VERSION ""

NS_ :

BS_:

BU_: mLEDR mLEDL TLR TLL RLR RLL HLR HLL DASCU CGW BCM

BO_ 3221225472 VECTOR__INDEPENDENT_SIG_MSG: 0 Vector__XXX
 SG_ MAS_SteeringAngle_Req : 0|16@1- (0.1,0) [-780|779.9] "Â°" Vector__XXX
 SG_ MAS_DistanceToGo_Val : 0|10@1+ (1,0) [0|1023] "cm" Vector__XXX
 SG_ MAS_TmissionMode_Req : 0|3@1+ (1,0) [0|4] "" Vector__XXX
 SG_ VCU_DriveInfo_RC : 0|4@1+ (1,0) [0|15] "" Vector__XXX

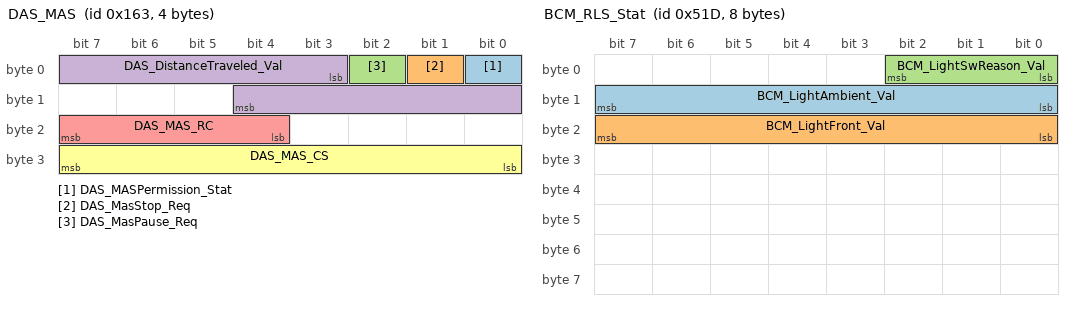
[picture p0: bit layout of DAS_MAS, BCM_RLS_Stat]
BO_ 355 DAS_MAS: 4 DASCU
 SG_ DAS_MASPermission_Stat : 0|1@1+ (1,0) [0|1] ""  CGW
 SG_ DAS_MasStop_Req : 1|1@1+ (1,0) [0|1] ""  CGW
 SG_ DAS_MasPause_Req : 2|1@1+ (1,0) [0|1] ""  CGW
 SG_ DAS_DistanceTraveled_Val : 3|10@1+ (1,0) [0|1023] "cm"  CGW
 SG_ DAS_MAS_RC : 20|4@1+ (1,0) [0|15] ""  CGW
 SG_ DAS_MAS_CS : 24|8@1+ (1,0) [0|255] ""  CGW

BO_ 640 BCM_VEH_STATE: 8 BCM
 SG_ BCM_T15_Stat : 0|1@1+ (1,0) [0|1] ""  HLR,mLEDR,TLR,RLL,RLR,DASCU,TLL,mLEDL,HLL
 SG_ BCM_CCTerm_Stat : 13|1@1+ (1,0) [0|1] "" Vector__XXX
 SG_ BCM_SwIndIntens_Stat : 52|1@1+ (1,0) [0|1] "" Vector__XXX
 SG_ BCM_T30d_Stat : 1|1@1+ (1,0) [0|1] ""  DASCU
 SG_ BCM_IndFadingTime_Req : 26|5@1+ (0.1,0) [0|3.1] "s" Vector__XXX
 SG_ HUD_IntensityRequest : 16|8@1+ (1,0) [0|255] "" Vector__XXX
 SG_ StealthModeEn : 6|1@1+ (1,0) [0|1] "" Vector__XXX
 SG_ BCM_T30i_DisableWarning : 14|1@1+ (1,0) [0|1] "" Vector__XXX
 SG_ BCM_T30i_Stat : 2|1@1+ (1,0) [0|1] ""  DASCU
 SG_ BCM_Light_Stat : 25|1@1+ (1,0) [0|1] "" Vector__XXX
 SG_ BCM_LightBCM_Stat : 15|1@1+ (1,0) [0|1] "" Vector__XXX
 SG_ BCM_CCTermDisableWarning : 31|1@1+ (1,0) [0|1] "" Vector__XXX
 SG_ BCM_SwBackIntens_Val : 40|8@1+ (0.394,0) [0|100.47] "%" Vector__XXX
 SG_ BCM_LVBatteryVoltage : 56|8@1+ (0.075,0) [0|19.125] "V" Vector__XXX
 SG_ BCM_PreheatFunction_Stat : 32|2@1+ (1,0) [0|3] "" Vector__XXX
 SG_ BCM_ADASTerm_Stat : 12|1@1+ (1,0) [0|1] ""  DASCU
 SG_ BCM_VehicleBody_Stat : 8|4@1+ (1,0) [0|6] ""  DASCU
 SG_ BCM_T30d_DisableWarning : 24|1@1+ (1,0) [0|1] ""  DASCU
 SG_ BCM_VehicleType_Stat : 7|1@1+ (1,0) [0|1] ""  DASCU
 SG_ BCM_T15h_Stat : 3|1@1+ (1,0) [0|1] "" Vector__XXX
 SG_ BCM_VehicleMode_Stat : 48|4@1+ (1,0) [0|6] ""  DASCU
 SG_ BCM_Vehicle_DrvMode : 53|3@1+ (1,0) [0|7] "" Vector__XXX
 SG_ BCM_VehiclePowertrain_Stat : 34|2@1+ (1,0) [0|3] "" Vector__XXX
 SG_ BCM_SPV_Feature_Stat : 5|1@1+ (1,0) [0|1] "" Vector__XXX

BO_ 1535 DAS_Configure: 5 DASCU
 SG_ DAS_CaebConf_Stat : 21|1@1+ (1,0) [0|1] ""  CGW
 SG_ DAS_CcConf_Stat : 0|1@1+ (1,0) [0|1] ""  CGW
 SG_ DAS_AccConf_Stat : 1|1@1+ (1,0) [0|1] ""  CGW
 SG_ DAS_LimConf_Stat : 2|1@1+ (1,0) [0|1] ""  CGW
 SG_ DAS_AslaConf_Stat : 3|1@1+ (1,0) [0|1] ""  CGW
 SG_ DAS_LkaConf_Stat : 4|1@1+ (1,0) [0|1] ""  CGW
 SG_ DAS_FcwConf_Stat : 5|1@1+ (1,0) [0|1] ""  CGW
 SG_ DAS_AebConf_Stat : 6|1@1+ (1,0) [0|1] ""  CGW
 SG_ DAS_LccConf_Stat : 7|1@1+ (1,0) [0|1] ""  CGW
 SG_ DAS_AlccConf_Stat : 8|1@1+ (1,0) [0|1] ""  CGW
 SG_ DAS_DowConf_Stat : 9|1@1+ (1,0) [0|1] ""  CGW
 SG_ DAS_LdwConf_Stat : 10|1@1+ (1,0) [0|1] ""  CGW
 SG_ DAS_LdpConf_Stat : 11|1@1+ (1,0) [0|1] ""  CGW
 SG_ DAS_TsrConf_Stat : 12|1@1+ (1,0) [0|1] ""  CGW
 SG_ DAS_AaConf_Stat : 13|1@1+ (1,0) [0|1] ""  CGW
 SG_ DAS_AfsConf_Stat : 14|1@1+ (1,0) [0|1] ""  CGW
 SG_ DAS_RdaConf_Stat : 15|1@1+ (1,0) [0|1] ""  CGW
 SG_ DAS_RctcConf_Stat : 16|1@1+ (1,0) [0|1] ""  CGW
 SG_ DAS_RcwConf_Stat : 17|1@1+ (1,0) [0|1] ""  CGW
 SG_ DAS_RecConf_Stat : 18|1@1+ (1,0) [0|1] ""  CGW
 SG_ DAS_NvConf_Stat : 19|1@1+ (1,0) [0|1] ""  CGW
 SG_ DAS_VisualConf_Stat : 20|1@1+ (1,0) [0|1] ""  CGW
 SG_ DAS_Conf_RC : 28|4@1+ (1,0) [0|15] ""  CGW
 SG_ DAS_Conf_CS : 32|8@1+ (1,0) [0|255] ""  CGW
 SG_ DAS_MliaConf_Stat : 22|1@1+ (1,0) [0|1] ""  CGW

BO_ 1309 BCM_RLS_Stat: 8 BCM
 SG_ BCM_LightAmbient_Val : 8|8@1+ (100,0) [0|25500] "lx"  DASCU
 SG_ BCM_LightFront_Val : 16|8@1+ (50,0) [0|12750] "lx"  DASCU
 SG_ BCM_LightSwReason_Val : 0|3@1+ (1,0) [0|6] ""  DASCU

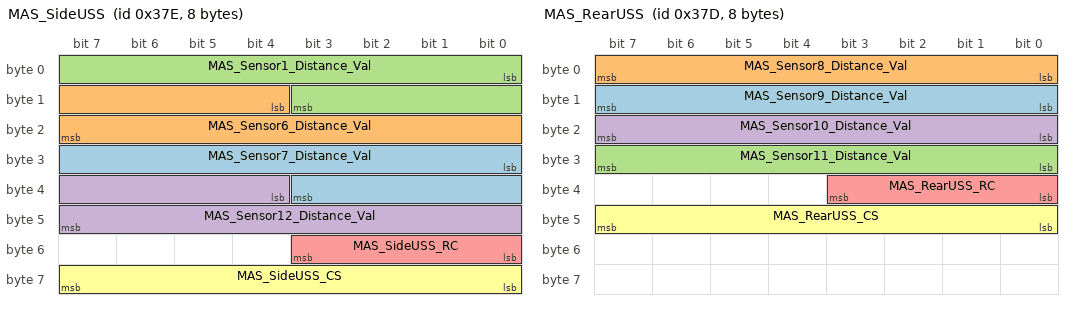
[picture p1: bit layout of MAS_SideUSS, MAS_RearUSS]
BO_ 894 MAS_SideUSS: 8 CGW
 SG_ MAS_Sensor7_Distance_Val : 24|12@1+ (2.5,0) [0|635] "cm"  DASCU
 SG_ MAS_Sensor6_Distance_Val : 12|12@1+ (2.5,0) [0|635] "cm"  DASCU
 SG_ MAS_Sensor1_Distance_Val : 0|12@1+ (2.5,0) [0|635] "cm"  DASCU
 SG_ MAS_Sensor12_Distance_Val : 36|12@1+ (2.5,0) [0|635] "cm"  DASCU
 SG_ MAS_SideUSS_RC : 48|4@1+ (1,0) [0|15] ""  DASCU
 SG_ MAS_SideUSS_CS : 56|8@1+ (1,0) [0|255] ""  DASCU

BO_ 893 MAS_RearUSS: 8 CGW
 SG_ MAS_Sensor9_Distance_Val : 8|8@1+ (1,0) [0|255] "cm"  DASCU
 SG_ MAS_Sensor8_Distance_Val : 0|8@1+ (1,0) [0|255] "cm"  DASCU
 SG_ MAS_Sensor11_Distance_Val : 24|8@1+ (1,0) [0|255] "cm"  DASCU
 SG_ MAS_Sensor10_Distance_Val : 16|8@1+ (1,0) [0|255] "cm"  DASCU
 SG_ MAS_RearUSS_RC : 32|4@1+ (1,0) [0|15] ""  DASCU
 SG_ MAS_RearUSS_CS : 40|8@1+ (1,0) [0|255] ""  DASCU

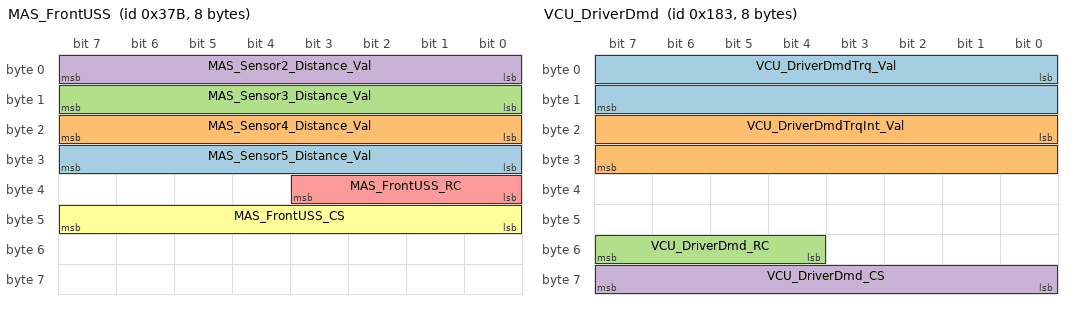
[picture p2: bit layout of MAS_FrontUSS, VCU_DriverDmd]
BO_ 891 MAS_FrontUSS: 8 CGW
 SG_ MAS_Sensor5_Distance_Val : 24|8@1+ (1,0) [0|255] "cm"  DASCU
 SG_ MAS_Sensor4_Distance_Val : 16|8@1+ (1,0) [0|255] "cm"  DASCU
 SG_ MAS_Sensor3_Distance_Val : 8|8@1+ (1,0) [0|255] "cm"  DASCU
 SG_ MAS_Sensor2_Distance_Val : 0|8@1+ (1,0) [0|255] "cm"  DASCU
 SG_ MAS_FrontUSS_RC : 32|4@1+ (1,0) [0|15] ""  DASCU
 SG_ MAS_FrontUSS_CS : 40|8@1+ (1,0) [0|255] ""  DASCU

BO_ 567 SWM_ContrlsState_Old: 8 CGW
 SG_ SWM_ContrlsState_Old_RC : 48|4@1+ (1,0) [0|15] ""  DASCU
 SG_ SWM_DC_WheelPosition_Stat : 10|6@1+ (1,0) [0|63] "" Vector__XXX
 SG_ SWM_ContrlsState_Old_CS : 56|8@1+ (1,0) [0|255] ""  DASCU
 SG_ SWM_MMSPrevBtn_Stat : 18|2@1+ (1,0) [0|3] "" Vector__XXX
 SG_ SWM_DC_WheelButton_Stat : 8|2@1+ (1,0) [0|3] "" Vector__XXX
 SG_ SWM_TELBtn_Stat : 20|2@1+ (1,0) [0|3] "" Vector__XXX
 SG_ SWM_ECULED_Stat : 36|2@1+ (1,0) [0|3] "" Vector__XXX
 SG_ SWM_ACC_SpeedIncrease_Stat : 6|2@1+ (1,0) [0|3] ""  DASCU
 SG_ SWM_ACCDistanceChange_Stat : 2|2@1+ (1,0) [0|3] ""  DASCU
 SG_ SWM_UpshiftPaddle_Stat : 32|2@1+ (1,0) [0|3] "" Vector__XXX
 SG_ SWM_ACCactivate_Stat : 0|2@1+ (1,0) [0|3] ""  DASCU
 SG_ SWM_MMSNextBtn_Stat : 16|2@1+ (1,0) [0|3] "" Vector__XXX
 SG_ SWM_ACCSpeedDecrease_Stat : 4|2@1+ (1,0) [0|3] ""  DASCU
 SG_ SWM_DownshiftPaddle_Stat : 34|2@1+ (1,0) [0|3] "" Vector__XXX
 SG_ SWM_VOLWheelBtn_Stat : 24|2@1+ (1,0) [0|3] "" Vector__XXX
 SG_ SWM_VCBtn_Stat : 22|2@1+ (1,0) [0|3] "" Vector__XXX
 SG_ SWM_VOLWheelPosition_Stat : 26|6@1+ (1,0) [0|63] "" Vector__XXX

BO_ 1902 Diag_To_RLR: 8 CGW
 SG_ Diag_To_RLR : 7|64@0+ (1,0) [0|1.84467440737096E+019] ""  RLR

BO_ 1901 Diag_To_RLL: 8 CGW
 SG_ Diag_To_RLL : 7|64@0+ (1,0) [0|1.84467440737096E+019] ""  RLL

BO_ 1894 Diag_To_TLR: 8 CGW
 SG_ Diag_To_TLR : 7|64@0+ (1,0) [0|1.84467440737096E+019] ""  TLR

BO_ 1893 Diag_To_TLL: 8 CGW
 SG_ Diag_To_TLL : 7|64@0+ (1,0) [0|1.84467440737096E+019] ""  TLL

BO_ 1900 Diag_To_mLEDR: 8 CGW
 SG_ Diag_To_mLEDR : 7|64@0+ (1,0) [0|1.84467440737096E+019] ""  mLEDR

BO_ 1915 Diag_To_HLR: 8 CGW
 SG_ Diag_To_HLR : 7|64@0+ (1,0) [0|1.84467440737096E+019] ""  HLR

BO_ 1898 Diag_To_mLEDL: 8 CGW
 SG_ Diag_To_mLEDL : 7|64@0+ (1,0) [0|1.84467440737096E+019] ""  mLEDL

BO_ 1897 Diag_To_HLL: 8 CGW
 SG_ Diag_To_HLL : 7|64@0+ (1,0) [0|1.84467440737096E+019] ""  HLL

BO_ 1910 Diag_From_TLR: 8 TLR
 SG_ Diag_From_TLR : 7|64@0+ (1,0) [0|1.84467440737096E+019] ""  CGW

BO_ 1909 Diag_From_TLL: 8 TLL
 SG_ Diag_From_TLL : 7|64@0+ (1,0) [0|1.84467440737096E+019] ""  CGW

BO_ 1918 Diag_From_RLR: 8 RLR
 SG_ Diag_From_RLR : 7|64@0+ (1,0) [0|1.84467440737096E+019] ""  CGW

BO_ 1917 Diag_From_RLL: 8 RLL
 SG_ Diag_From_RLL : 7|64@0+ (1,0) [0|1.84467440737096E+019] ""  CGW

BO_ 1916 Diag_From_mLEDR: 8 mLEDR
 SG_ Diag_From_mLEDR : 7|64@0+ (1,0) [0|1.84467440737096E+019] ""  CGW

BO_ 1899 Diag_From_HLR: 8 HLR
 SG_ Diag_From_HLR : 7|64@0+ (1,0) [0|1.84467440737096E+019] ""  CGW

BO_ 1914 Diag_From_mLEDL: 8 mLEDL
 SG_ Diag_From_mLEDL : 7|64@0+ (1,0) [0|1.84467440737096E+019] ""  CGW

BO_ 1913 Diag_From_HLL: 8 HLL
 SG_ Diag_From_HLL : 7|64@0+ (1,0) [0|1.84467440737096E+019] ""  CGW

BO_ 387 VCU_DriverDmd: 8 CGW
 SG_ VCU_DriverDmdTrq_Val : 0|16@1+ (0.25,-1533) [-1533|1537.5] "Nm"  DASCU
 SG_ VCU_DriverDmdTrqInt_Val : 16|16@1+ (0.25,-1533) [-1533|1537.5] "Nm"  DASCU
 SG_ VCU_DriverDmd_RC : 52|4@1+ (1,0) [0|15] ""  DASCU
 SG_ VCU_DriverDmd_CS : 56|8@1+ (1,0) [0|255] ""  DASCU

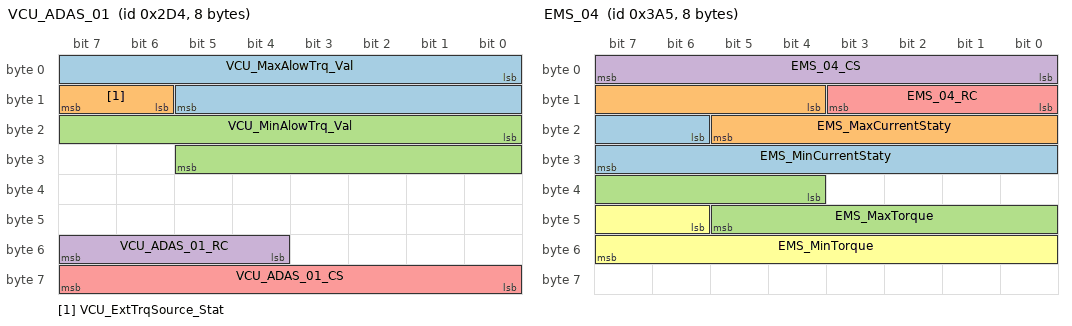
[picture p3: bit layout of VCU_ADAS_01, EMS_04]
BO_ 724 VCU_ADAS_01: 8 CGW
 SG_ VCU_MaxAlowTrq_Val : 0|14@1+ (0.25,-1533) [-1533|1537.5] "Nm"  DASCU
 SG_ VCU_ExtTrqSource_Stat : 14|2@1+ (1,0) [0|3] ""  DASCU
 SG_ VCU_MinAlowTrq_Val : 16|14@1+ (0.25,-1533) [-1533|1537.5] "Nm"  DASCU
 SG_ VCU_ADAS_01_RC : 52|4@1+ (1,0) [0|15] ""  DASCU
 SG_ VCU_ADAS_01_CS : 56|8@1+ (1,0) [0|255] ""  DASCU

BO_ 933 EMS_04: 8 CGW
 SG_ EMS_MinCurrentStaty : 22|10@1+ (1,-511) [-511|511] "A"  DASCU
 SG_ EMS_MaxCurrentStaty : 12|10@1+ (1,-511) [-511|511] "A"  DASCU
 SG_ EMS_MaxTorque : 36|10@1+ (1,-511) [-511|511] "Nm"  DASCU
 SG_ EMS_04_CS : 0|8@1+ (1,0) [0|255] ""  DASCU
 SG_ EMS_04_RC : 8|4@1+ (1,0) [0|15] ""  DASCU
 SG_ EMS_MinTorque : 46|10@1+ (1,-511) [-511|511] "Nm"  DASCU

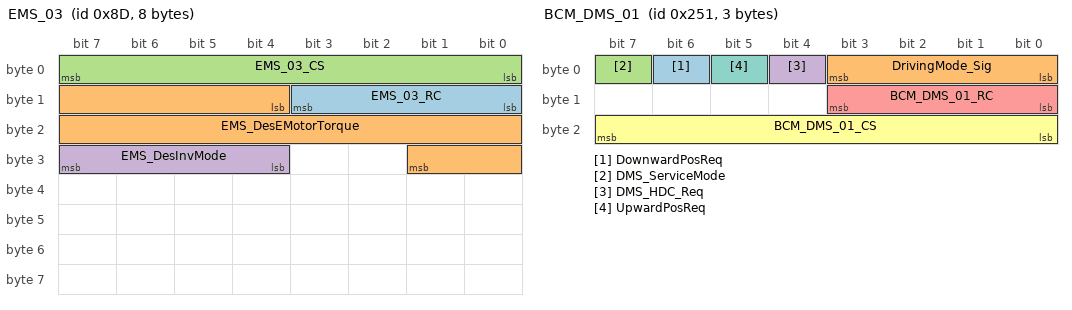
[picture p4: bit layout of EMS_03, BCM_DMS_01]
BO_ 141 EMS_03: 8 CGW
 SG_ EMS_03_RC : 8|4@1+ (1,0) [0|15] ""  DASCU
 SG_ EMS_DesEMotorTorque : 12|14@1+ (0.1,-819.1) [-819.1|819.1] "Nm"  DASCU
 SG_ EMS_03_CS : 0|8@1+ (1,0) [0|255] ""  DASCU
 SG_ EMS_DesInvMode : 28|4@1+ (1,0) [0|15] ""  DASCU

BO_ 593 BCM_DMS_01: 3 CGW
 SG_ DownwardPosReq : 6|1@1+ (1,0) [0|1] "" Vector__XXX
 SG_ DrivingMode_Sig : 0|4@1+ (1,0) [0|4] ""  DASCU
 SG_ DMS_ServiceMode : 7|1@1+ (1,0) [0|1] "" Vector__XXX
 SG_ DMS_HDC_Req : 4|1@1+ (1,0) [0|1] "" Vector__XXX
 SG_ BCM_DMS_01_RC : 8|4@1+ (1,0) [0|15] ""  DASCU
 SG_ BCM_DMS_01_CS : 16|8@1+ (1,0) [0|255] ""  DASCU
 SG_ UpwardPosReq : 5|1@1+ (1,0) [0|1] "" Vector__XXX

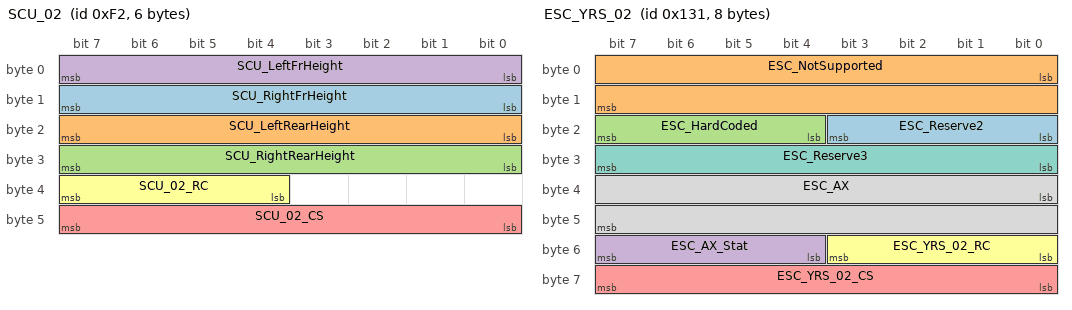
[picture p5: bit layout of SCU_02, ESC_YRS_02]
BO_ 242 SCU_02: 6 CGW
 SG_ SCU_RightFrHeight : 8|8@1+ (1,40) [40|254] ""  DASCU
 SG_ SCU_LeftRearHeight : 16|8@1+ (1,40) [40|254] ""  DASCU
 SG_ SCU_RightRearHeight : 24|8@1+ (1,40) [40|254] ""  DASCU
 SG_ SCU_LeftFrHeight : 0|8@1+ (1,40) [40|254] ""  DASCU
 SG_ SCU_02_CS : 40|8@1+ (1,0) [0|255] ""  DASCU
 SG_ SCU_02_RC : 36|4@1+ (1,0) [0|15] ""  DASCU

BO_ 305 ESC_YRS_02: 8 CGW
 SG_ ESC_Reserve2 : 16|4@1+ (1,0) [0|15] "" Vector__XXX
 SG_ ESC_NotSupported : 0|16@1+ (1,0) [0|65535] "" Vector__XXX
 SG_ ESC_HardCoded : 20|4@1+ (1,0) [0|15] "" Vector__XXX
 SG_ ESC_AX_Stat : 52|4@1+ (1,0) [0|15] ""  DASCU
 SG_ ESC_YRS_02_CS : 56|8@1+ (1,0) [0|255] ""  DASCU
 SG_ ESC_YRS_02_RC : 48|4@1+ (1,0) [0|15] ""  DASCU
 SG_ ESC_Reserve3 : 24|8@1+ (1,0) [0|255] "" Vector__XXX
 SG_ ESC_AX : 32|16@1+ (0.0001274,-4.1745) [-4.1745|4.1745] "g"  DASCU

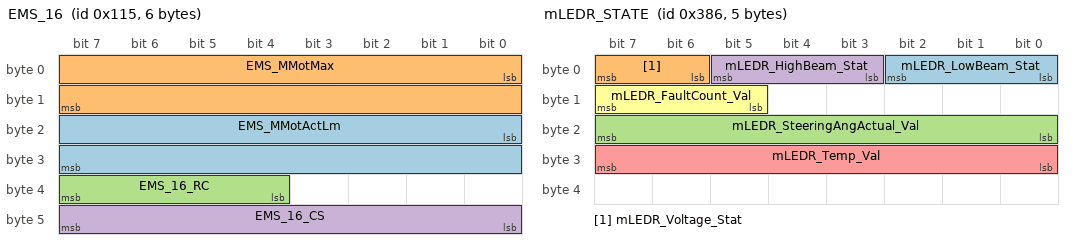
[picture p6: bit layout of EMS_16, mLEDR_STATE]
BO_ 277 EMS_16: 6 CGW
 SG_ EMS_MMotActLm : 16|16@1+ (1,-30000) [-30000|30000] "Nm"  DASCU
 SG_ EMS_MMotMax : 0|16@1+ (1,-30000) [-30000|30000] "Nm"  DASCU
 SG_ EMS_16_RC : 36|4@1+ (1,0) [0|15] ""  DASCU
 SG_ EMS_16_CS : 40|8@1+ (1,0) [0|255] ""  DASCU

BO_ 902 mLEDR_STATE: 5 mLEDR
 SG_ mLEDR_LowBeam_Stat : 0|3@1+ (1,0) [0|6] ""  BCM,DASCU,HLR
 SG_ mLEDR_Voltage_Stat : 6|2@1+ (1,0) [0|2] ""  HLR,BCM
 SG_ mLEDR_SteeringAngActual_Val : 16|8@1+ (1,0) [0|40] ""  DASCU,BCM,HLR
 SG_ mLEDR_HighBeam_Stat : 3|3@1+ (1,0) [0|4] ""  DASCU,HLR,BCM
 SG_ mLEDR_Temp_Val : 24|8@1+ (1,-40) [-40|150] ""  BCM,HLR
 SG_ mLEDR_FaultCount_Val : 13|3@1+ (1,0) [0|2] ""  BCM,DASCU,HLR

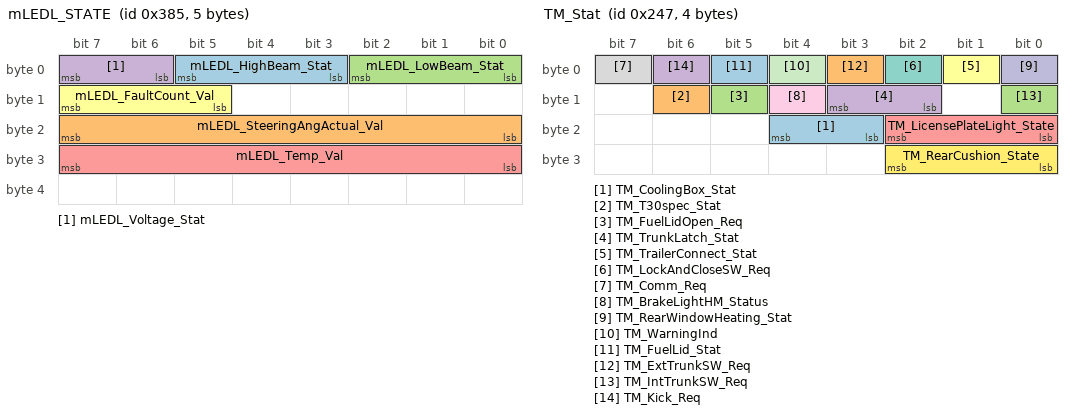
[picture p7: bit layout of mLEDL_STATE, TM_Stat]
BO_ 901 mLEDL_STATE: 5 mLEDL
 SG_ mLEDL_HighBeam_Stat : 3|3@1+ (1,0) [0|4] ""  HLL,BCM,DASCU
 SG_ mLEDL_SteeringAngActual_Val : 16|8@1+ (1,0) [0|40] ""  HLL,BCM,DASCU
 SG_ mLEDL_LowBeam_Stat : 0|3@1+ (1,0) [0|6] ""  HLL,DASCU,BCM
 SG_ mLEDL_Voltage_Stat : 6|2@1+ (1,0) [0|2] ""  BCM,HLL
 SG_ mLEDL_Temp_Val : 24|8@1+ (1,-40) [-40|150] "°C"  HLL,BCM
 SG_ mLEDL_FaultCount_Val : 13|3@1+ (1,0) [0|2] ""  HLL,BCM,DASCU

BO_ 583 TM_Stat: 4 CGW
 SG_ TM_CoolingBox_Stat : 19|2@1+ (1,0) [0|3] "2" Vector__XXX
 SG_ TM_T30spec_Stat : 14|1@1+ (1,0) [0|1] "" Vector__XXX
 SG_ TM_FuelLidOpen_Req : 13|1@1+ (1,0) [0|1] "" Vector__XXX
 SG_ TM_TrunkLatch_Stat : 10|2@1+ (1,0) [0|3] "" Vector__XXX
 SG_ TM_LicensePlateLight_State : 16|3@1+ (1,0) [0|2] "" Vector__XXX
 SG_ TM_TrailerConnect_Stat : 1|1@1+ (1,0) [0|1] ""  DASCU
 SG_ TM_LockAndCloseSW_Req : 2|1@1+ (1,0) [0|1] "" Vector__XXX
 SG_ TM_Comm_Req : 7|1@1+ (1,0) [0|1] ""  DASCU
 SG_ TM_BrakeLightHM_Status : 12|1@1+ (1,0) [0|1] "" Vector__XXX
 SG_ TM_RearWindowHeating_Stat : 0|1@1+ (1,0) [0|1] "" Vector__XXX
 SG_ TM_WarningInd : 4|1@1+ (1,0) [0|1] "" Vector__XXX
 SG_ TM_RearCushion_State : 24|3@1+ (1,0) [0|4] "" Vector__XXX
 SG_ TM_FuelLid_Stat : 5|1@1+ (1,0) [0|1] "" Vector__XXX
 SG_ TM_ExtTrunkSW_Req : 3|1@1+ (1,0) [0|1] "" Vector__XXX
 SG_ TM_IntTrunkSW_Req : 8|1@1+ (1,0) [0|1] "" Vector__XXX
 SG_ TM_Kick_Req : 6|1@1+ (1,0) [0|1] "" Vector__XXX

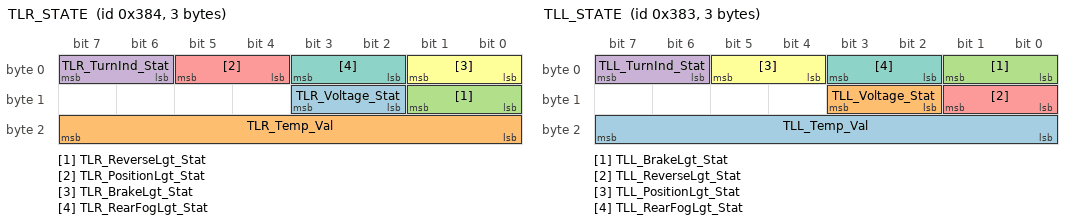
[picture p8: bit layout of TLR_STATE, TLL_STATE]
BO_ 900 TLR_STATE: 3 TLR
 SG_ TLR_Voltage_Stat : 10|2@1+ (1,0) [0|3] ""  BCM
 SG_ TLR_Temp_Val : 16|8@1+ (1,0) [0|150] "°C"  BCM
 SG_ TLR_ReverseLgt_Stat : 8|2@1+ (1,0) [0|3] ""  BCM
 SG_ TLR_TurnInd_Stat : 6|2@1+ (1,0) [0|3] ""  BCM
 SG_ TLR_PositionLgt_Stat : 4|2@1+ (1,0) [0|3] ""  BCM
 SG_ TLR_BrakeLgt_Stat : 0|2@1+ (1,0) [0|3] ""  BCM
 SG_ TLR_RearFogLgt_Stat : 2|2@1+ (1,0) [0|3] ""  BCM

BO_ 899 TLL_STATE: 3 TLL
 SG_ TLL_Temp_Val : 16|8@1+ (1,0) [0|150] "°C"  BCM
 SG_ TLL_Voltage_Stat : 10|2@1+ (1,0) [0|3] ""  BCM
 SG_ TLL_BrakeLgt_Stat : 0|2@1+ (1,0) [0|3] ""  BCM
 SG_ TLL_TurnInd_Stat : 6|2@1+ (1,0) [0|3] ""  BCM
 SG_ TLL_ReverseLgt_Stat : 8|2@1+ (1,0) [0|3] ""  BCM
 SG_ TLL_PositionLgt_Stat : 4|2@1+ (1,0) [0|3] ""  BCM
 SG_ TLL_RearFogLgt_Stat : 2|2@1+ (1,0) [0|3] ""  BCM

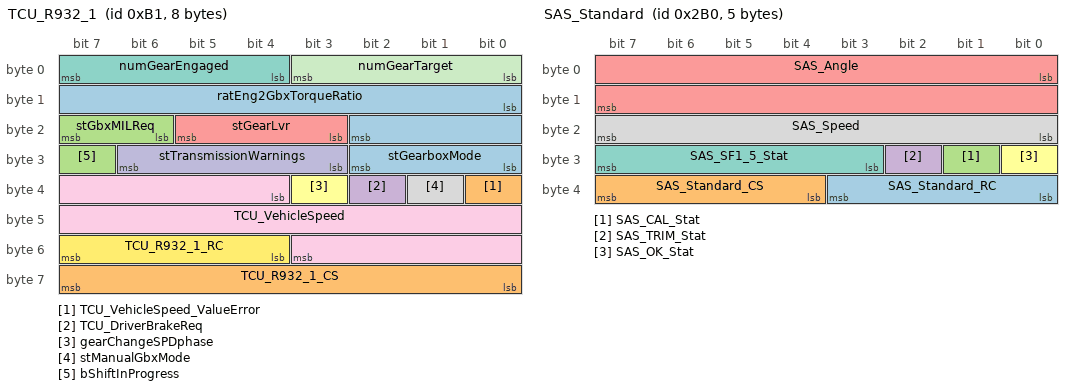
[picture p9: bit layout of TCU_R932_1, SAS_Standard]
BO_ 177 TCU_R932_1: 8 CGW
 SG_ ratEng2GbxTorqueRatio : 8|11@1+ (0.01,0) [0|20.47] "" Vector__XXX
 SG_ TCU_VehicleSpeed_ValueError : 32|1@1+ (1,0) [0|1] "" Vector__XXX
 SG_ stGbxMILReq : 22|2@1+ (1,0) [0|3] ""  DASCU
 SG_ TCU_DriverBrakeReq : 34|1@1+ (1,0) [0|1] "" Vector__XXX
 SG_ stGearLvr : 19|3@1+ (1,0) [0|7] ""  DASCU
 SG_ gearChangeSPDphase : 35|1@1+ (1,0) [0|1] ""  DASCU
 SG_ numGearEngaged : 4|4@1+ (1,0) [0|15] ""  DASCU
 SG_ stManualGbxMode : 33|1@1+ (1,0) [0|1] ""  DASCU
 SG_ TCU_VehicleSpeed : 36|16@1+ (0.01,0) [0|655.35] "km/h" Vector__XXX
 SG_ stTransmissionWarnings : 27|4@1+ (1,0) [0|15] "" Vector__XXX
 SG_ numGearTarget : 0|4@1+ (1,0) [0|15] ""  DASCU
 SG_ TCU_R932_1_RC : 52|4@1+ (1,0) [0|15] ""  DASCU
 SG_ stGearboxMode : 24|3@1+ (1,0) [0|7] ""  DASCU
 SG_ TCU_R932_1_CS : 56|8@1+ (1,0) [0|255] ""  DASCU
 SG_ bShiftInProgress : 31|1@1+ (1,0) [0|1] ""  DASCU

BO_ 568 SWM_ContrlsState: 8 CGW
 SG_ SWM_ContrlsState_CS : 56|8@1+ (1,0) [0|255] ""  DASCU
 SG_ SWM_ContrlsState_RC : 48|4@1+ (1,0) [0|15] ""  DASCU
 SG_ SWM_VolumeMute_Req : 42|2@1+ (1,0) [0|3] "" Vector__XXX
 SG_ SWM_VolumeDownBtn_Req : 40|2@1+ (1,0) [0|3] "" Vector__XXX
 SG_ SWM_VolumeUpBtn_Req : 38|2@1+ (1,0) [0|3] "" Vector__XXX
 SG_ SWM_VoiceCntrl_Req : 36|2@1+ (1,0) [0|3] "" Vector__XXX
 SG_ SWM_MMCPrevBtn_Req : 34|2@1+ (1,0) [0|3] "" Vector__XXX
 SG_ SWM_MMCNextBtn_Req : 32|2@1+ (1,0) [0|3] "" Vector__XXX
 SG_ SWM_MODE_Req : 0|2@1+ (1,0) [0|3] ""  DASCU
 SG_ SWM_CNCL_Req : 2|2@1+ (1,0) [0|3] ""  DASCU
 SG_ SWM_DIS_Req : 10|2@1+ (1,0) [0|3] ""  DASCU
 SG_ SWM_RES_Req : 12|2@1+ (1,0) [0|3] ""  DASCU
 SG_ SWM_UserFunc_Req : 8|2@1+ (1,0) [0|3] ""  DASCU
 SG_ SWM_ACCSpeedDecrease_Req : 4|2@1+ (1,0) [0|3] ""  DASCU
 SG_ SWM_ACCSpeedIncrease_Req : 6|2@1+ (1,0) [0|3] ""  DASCU
 SG_ SWM_SETSpeed_Req : 14|2@1+ (1,0) [0|3] ""  DASCU
 SG_ SWM_TELBtn_Req : 16|2@1+ (1,0) [0|3] "" Vector__XXX
 SG_ SWM_Home_Req : 18|2@1+ (1,0) [0|3] "" Vector__XXX
 SG_ SWM_Back_Req : 20|2@1+ (1,0) [0|3] "" Vector__XXX
 SG_ SWM_ICNextBtn_Req : 22|2@1+ (1,0) [0|3] "" Vector__XXX
 SG_ SWM_ICPrevBtn_Req : 24|2@1+ (1,0) [0|3] "" Vector__XXX
 SG_ SWM_ICUpBtn_Req : 26|2@1+ (1,0) [0|3] "" Vector__XXX
 SG_ SWM_ICDownBtn_Req : 28|2@1+ (1,0) [0|3] "" Vector__XXX
 SG_ SWM_ICConfBtn_Req : 30|2@1+ (1,0) [0|3] "" Vector__XXX
 SG_ SWM_UpshiftPaddle_Req : 44|2@1+ (1,0) [0|3] "" Vector__XXX
 SG_ SWM_DownshiftPaddle_Req : 46|2@1+ (1,0) [0|3] "" Vector__XXX
 SG_ SWM_PosHand_Stat : 54|2@1+ (1,0) [0|3] ""  DASCU

BO_ 688 SAS_Standard: 5 CGW
 SG_ SAS_Standard_RC : 32|4@1+ (1,0) [0|15] ""  DASCU
 SG_ SAS_Standard_CS : 36|4@1+ (1,0) [0|15] ""  DASCU
 SG_ SAS_CAL_Stat : 25|1@1+ (1,0) [0|1] ""  DASCU
 SG_ SAS_TRIM_Stat : 26|1@1+ (1,0) [0|1] "" Vector__XXX
 SG_ SAS_Angle : 0|16@1- (0.1,0) [-780|779.9] "°"  DASCU
 SG_ SAS_OK_Stat : 24|1@1+ (1,0) [0|1] ""  DASCU
 SG_ SAS_SF1_5_Stat : 27|5@1+ (1,0) [0|31] "" Vector__XXX
 SG_ SAS_Speed : 16|8@1+ (4,0) [0|1016] "°/s"  DASCU

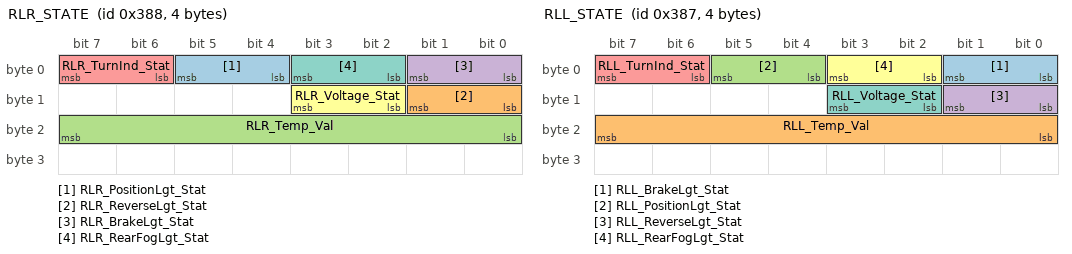
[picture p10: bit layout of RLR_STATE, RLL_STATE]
BO_ 904 RLR_STATE: 4 RLR
 SG_ RLR_PositionLgt_Stat : 4|2@1+ (1,0) [0|2] ""  BCM
 SG_ RLR_ReverseLgt_Stat : 8|2@1+ (1,0) [0|2] ""  BCM
 SG_ RLR_Temp_Val : 16|8@1+ (1,-40) [-40|150] "°C"  BCM
 SG_ RLR_BrakeLgt_Stat : 0|2@1+ (1,0) [0|2] ""  BCM
 SG_ RLR_TurnInd_Stat : 6|2@1+ (1,0) [0|2] ""  BCM
 SG_ RLR_Voltage_Stat : 10|2@1+ (1,0) [0|2] ""  BCM
 SG_ RLR_RearFogLgt_Stat : 2|2@1+ (1,0) [0|2] ""  BCM

BO_ 903 RLL_STATE: 4 RLL
 SG_ RLL_BrakeLgt_Stat : 0|2@1+ (1,0) [0|2] ""  BCM
 SG_ RLL_Temp_Val : 16|8@1+ (1,-40) [-40|150] "°C"  BCM
 SG_ RLL_PositionLgt_Stat : 4|2@1+ (1,0) [0|2] ""  BCM
 SG_ RLL_ReverseLgt_Stat : 8|2@1+ (1,0) [0|2] ""  BCM
 SG_ RLL_TurnInd_Stat : 6|2@1+ (1,0) [0|2] ""  BCM
 SG_ RLL_RearFogLgt_Stat : 2|2@1+ (1,0) [0|2] ""  BCM
 SG_ RLL_Voltage_Stat : 10|2@1+ (1,0) [0|2] ""  BCM

BO_ 976 MAS_Status: 8 CGW
 SG_ MAS_ParkingOutSuccess_Stat : 27|1@1+ (1,0) [0|1] ""  DASCU
 SG_ MAS_ParkingOutAvailable_Stat : 26|1@1+ (1,0) [0|1] ""  DASCU
 SG_ MAS_APAMode_Stat : 21|3@1+ (1,0) [0|7] ""  DASCU
 SG_ MAS_APAManeuverSuccess_Stat : 25|1@1+ (1,0) [0|1] ""  DASCU
 SG_ MAS_AVMUltrasonicSide_Stat : 16|2@1+ (1,0) [0|2] ""  DASCU
 SG_ MAS_Status_RC : 28|4@1+ (1,0) [0|15] ""  DASCU
 SG_ MAS_Status_CS : 32|8@1+ (1,0) [0|255] ""  DASCU
 SG_ MAS_AVMUltrasonicRear_Stat : 14|2@1+ (1,0) [0|2] ""  DASCU
 SG_ MAS_AVMUltrasonicFront_Stat : 12|2@1+ (1,0) [0|2] ""  DASCU
 SG_ MAS_AVMCameraRightSide_Stat : 7|1@1+ (1,0) [0|1] "" Vector__XXX
 SG_ MAS_AVMCameraLeftSide_Stat : 6|1@1+ (1,0) [0|1] "" Vector__XXX
 SG_ MAS_AVMCameraRear_Stat : 5|1@1+ (1,0) [0|1] "" Vector__XXX
 SG_ MAS_AVMCameraFront_Stat : 4|1@1+ (1,0) [0|1] "" Vector__XXX
 SG_ MAS_AVMUltraSonic_Stat : 3|1@1+ (1,0) [0|1] ""  DASCU
 SG_ MAS_AVMNarrowMode_Stat : 1|2@1+ (1,0) [0|1] "" Vector__XXX
 SG_ MAS_AVMAutoAct_Stat : 24|1@1+ (1,0) [0|1] "" Vector__XXX
 SG_ MAS_MASmode_Stat : 18|3@1+ (1,0) [0|4] "" Vector__XXX
 SG_ MAS_View_Stat : 8|3@1+ (1,0) [0|7] "" Vector__XXX
 SG_ MAS_Calibration_Stat : 11|1@1+ (1,0) [0|1] "" Vector__XXX

BO_ 320 DAS_HUD_02: 7 DASCU
 SG_ DAS_LeftLaneLDWWarning_Req m0 : 7|1@1+ (1,0) [0|1] ""  CGW
 SG_ DAS_RightLaneLDWWarning_Req m1 : 7|1@1+ (1,0) [0|1] ""  CGW
 SG_ DAS_SPLimRoadSignInf1_Stat m0 : 16|6@1+ (1,0) [0|63] ""  CGW
 SG_ DAS_SPLimRoadSignInf2_Stat m1 : 16|6@1+ (1,0) [0|63] ""  CGW
 SG_ DAS_SPLimRoadSignInf3_Stat m2 : 16|6@1+ (1,0) [0|63] ""  CGW
 SG_ DAS_RoadSignAddressing_Stat M : 22|2@1+ (1,0) [0|3] ""  CGW
 SG_ DAS_SPLimRoadSignCurrSpeed_Stat : 24|8@1+ (1,0) [0|255] "km/h"  CGW
 SG_ DAS_RoadLaneAddressing_Stat M : 34|1@1+ (1,0) [0|1] ""  CGW

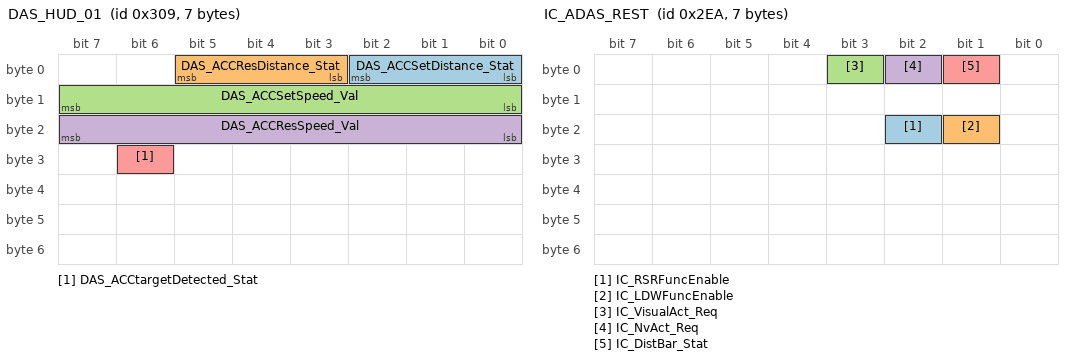
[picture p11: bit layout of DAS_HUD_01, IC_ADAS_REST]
BO_ 777 DAS_HUD_01: 7 DASCU
 SG_ DAS_ACCSetDistance_Stat : 0|3@1+ (1,0) [0|2] ""  CGW
 SG_ DAS_ACCResDistance_Stat : 3|3@1+ (1,0) [0|1] ""  CGW
 SG_ DAS_ACCSetSpeed_Val : 8|8@1+ (1,0) [0|255] ""  CGW
 SG_ DAS_ACCResSpeed_Val : 16|8@1+ (1,0) [0|255] ""  CGW
 SG_ DAS_ACCtargetDetected_Stat : 30|1@1+ (1,0) [0|1] ""  CGW

BO_ 746 IC_ADAS_REST: 7 CGW
 SG_ IC_RSRFuncEnable : 18|1@1+ (1,0) [0|1] "" Vector__XXX
 SG_ IC_LDWFuncEnable : 17|1@1+ (1,0) [0|1] "" Vector__XXX
 SG_ IC_VisualAct_Req : 3|1@1+ (1,0) [0|1] ""  DASCU
 SG_ IC_NvAct_Req : 2|1@1+ (1,0) [0|1] ""  DASCU
 SG_ IC_DistBar_Stat : 1|1@1+ (1,0) [0|1] ""  DASCU

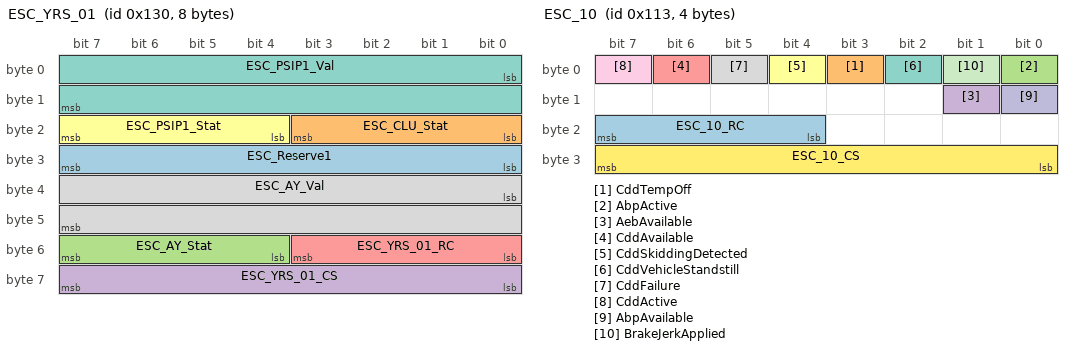
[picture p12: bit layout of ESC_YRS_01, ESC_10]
BO_ 304 ESC_YRS_01: 8 CGW
 SG_ ESC_Reserve1 : 24|8@1+ (1,0) [0|255] "" Vector__XXX
 SG_ ESC_CLU_Stat : 16|4@1+ (1,0) [0|15] "" Vector__XXX
 SG_ ESC_AY_Stat : 52|4@1+ (1,0) [0|15] ""  DASCU
 SG_ ESC_YRS_01_CS : 56|8@1+ (1,0) [0|255] ""  DASCU
 SG_ ESC_YRS_01_RC : 48|4@1+ (1,0) [0|15] ""  DASCU
 SG_ ESC_PSIP1_Stat : 20|4@1+ (1,0) [0|15] ""  DASCU
 SG_ ESC_PSIP1_Val : 0|16@1+ (0.005,-163.84) [-163.84|163.83] "°/s"  DASCU
 SG_ ESC_AY_Val : 32|16@1+ (0.0001274,-4.1745) [-4.1745|4.174659] "g"  DASCU

BO_ 275 ESC_10: 4 CGW
 SG_ ESC_10_RC : 20|4@1+ (1,0) [0|15] ""  DASCU
 SG_ CddTempOff : 3|1@1+ (1,0) [0|1] ""  DASCU
 SG_ AbpActive : 0|1@1+ (1,0) [0|1] "" Vector__XXX
 SG_ AebAvailable : 9|1@1+ (1,0) [0|1] ""  DASCU
 SG_ CddAvailable : 6|1@1+ (1,0) [0|1] ""  DASCU
 SG_ CddSkiddingDetected : 4|1@1+ (1,0) [0|1] ""  DASCU
 SG_ CddVehicleStandstill : 2|1@1+ (1,0) [0|1] ""  DASCU
 SG_ CddFailure : 5|1@1+ (1,0) [0|1] "" Vector__XXX
 SG_ CddActive : 7|1@1+ (1,0) [0|1] ""  DASCU
 SG_ AbpAvailable : 8|1@1+ (1,0) [0|1] "" Vector__XXX
 SG_ BrakeJerkApplied : 1|1@1+ (1,0) [0|1] "" Vector__XXX
 SG_ ESC_10_CS : 24|8@1+ (1,0) [0|255] ""  DASCU

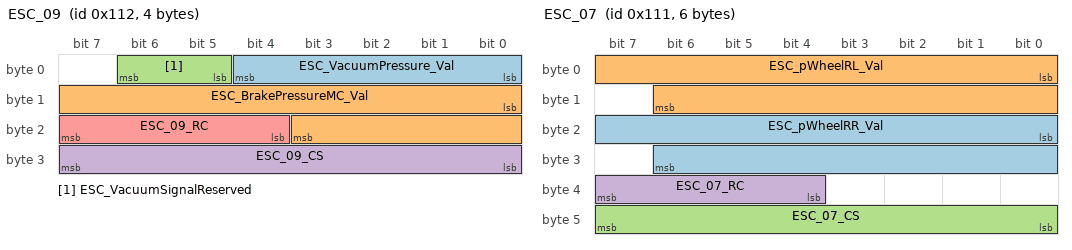
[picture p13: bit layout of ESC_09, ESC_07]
BO_ 274 ESC_09: 4 CGW
 SG_ ESC_VacuumPressure_Val : 0|5@1+ (5,-100) [-100|55] "kPa" Vector__XXX
 SG_ ESC_BrakePressureMC_Val : 8|12@1+ (0.1,0) [0|409.5] "bar"  DASCU,BCM
 SG_ ESC_VacuumSignalReserved : 5|2@1+ (1,0) [0|3] "" Vector__XXX
 SG_ ESC_09_CS : 24|8@1+ (1,0) [0|255] ""  DASCU
 SG_ ESC_09_RC : 20|4@1+ (1,0) [0|15] ""  DASCU

BO_ 273 ESC_07: 6 CGW
 SG_ ESC_pWheelRR_Val : 16|15@1+ (0.0153,0) [0|425] "bar"  DASCU
 SG_ ESC_pWheelRL_Val : 0|15@1+ (0.0153,0) [0|425] "bar"  DASCU
 SG_ ESC_07_CS : 40|8@1+ (1,0) [0|255] ""  DASCU
 SG_ ESC_07_RC : 36|4@1+ (1,0) [0|15] ""  DASCU

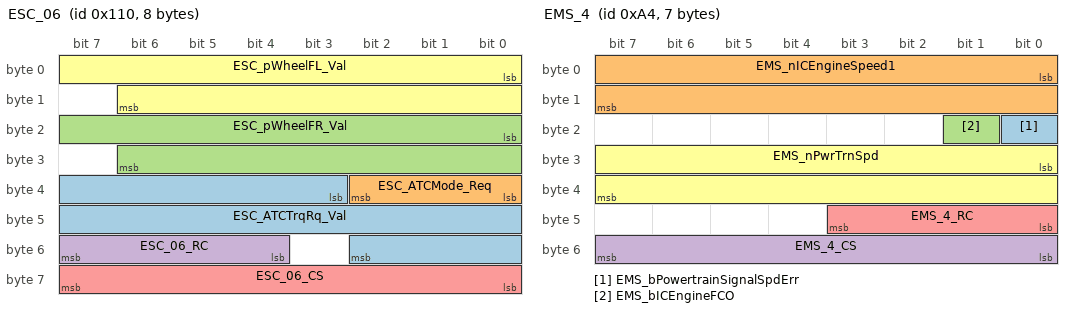
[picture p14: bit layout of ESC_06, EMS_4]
BO_ 272 ESC_06: 8 CGW
 SG_ ESC_ATCTrqRq_Val : 35|16@1+ (1,-30000) [-30000|35535] "Nm" Vector__XXX
 SG_ ESC_ATCMode_Req : 32|3@1+ (1,0) [0|7] "" Vector__XXX
 SG_ ESC_pWheelFR_Val : 16|15@1+ (0.0153,0) [0|425] "bar"  DASCU
 SG_ ESC_06_RC : 52|4@1+ (1,0) [0|15] ""  DASCU
 SG_ ESC_06_CS : 56|8@1+ (1,0) [0|255] ""  DASCU
 SG_ ESC_pWheelFL_Val : 0|15@1+ (0.0153,0) [0|425] "bar"  DASCU

BO_ 164 EMS_4: 7 CGW
 SG_ EMS_bPowertrainSignalSpdErr : 16|1@1+ (1,0) [0|1] "" Vector__XXX
 SG_ EMS_nICEngineSpeed1 : 0|16@1+ (0.25,0) [0|16383.75] "rpm"  DASCU
 SG_ EMS_bICEngineFCO : 17|1@1+ (1,0) [0|1] "" Vector__XXX
 SG_ EMS_4_CS : 48|8@1+ (1,0) [0|255] "" Vector__XXX
 SG_ EMS_4_RC : 40|4@1+ (1,0) [0|15] "" Vector__XXX
 SG_ EMS_nPwrTrnSpd : 24|16@1+ (0.25,0) [0|16383.75] "rpm" Vector__XXX

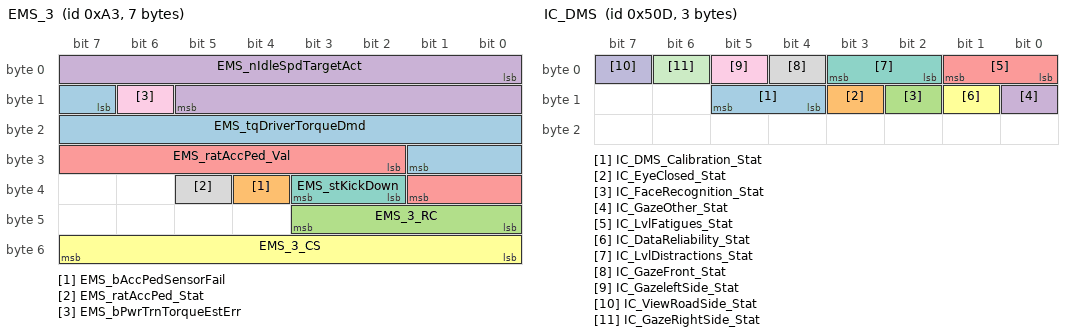
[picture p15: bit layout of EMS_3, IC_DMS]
BO_ 163 EMS_3: 7 CGW
 SG_ EMS_tqDriverTorqueDmd : 15|11@1+ (1,-500) [-500|1547] "Nm"  DASCU
 SG_ EMS_bAccPedSensorFail : 36|1@1+ (1,0) [0|1] ""  DASCU
 SG_ EMS_3_RC : 40|4@1+ (1,0) [0|15] "" Vector__XXX
 SG_ EMS_nIdleSpdTargetAct : 0|14@1+ (1,0) [0|16383] "rpm" Vector__XXX
 SG_ EMS_ratAccPed_Val : 26|8@1+ (0.39,0) [0|99.45] "%"  DASCU
 SG_ EMS_3_CS : 48|8@1+ (1,0) [0|255] "" Vector__XXX
 SG_ EMS_stKickDown : 34|2@1+ (1,0) [0|3] ""  DASCU
 SG_ EMS_ratAccPed_Stat : 37|1@1+ (1,0) [0|1] "" Vector__XXX
 SG_ EMS_bPwrTrnTorqueEstErr : 14|1@1+ (1,0) [0|1] "" Vector__XXX

BO_ 1292 IC_HUD_01: 4 CGW
 SG_ IC_Speed : 1|9@1+ (1,0) [0|510] "km/h"  DASCU

BO_ 1293 IC_DMS: 3 CGW
 SG_ IC_DMS_Calibration_Stat : 12|2@1+ (1,0) [0|2] ""  DASCU
 SG_ IC_EyeClosed_Stat : 11|1@1+ (1,0) [0|1] ""  DASCU
 SG_ IC_FaceRecognition_Stat : 10|1@1+ (1,0) [0|1] ""  DASCU
 SG_ IC_GazeOther_Stat : 8|1@1+ (1,0) [0|1] ""  DASCU
 SG_ IC_LvlFatigues_Stat : 0|2@1+ (1,0) [0|3] ""  DASCU
 SG_ IC_DataReliability_Stat : 9|1@1+ (1,0) [0|1] ""  DASCU
 SG_ IC_LvlDistractions_Stat : 2|2@1+ (1,0) [0|2] ""  DASCU
 SG_ IC_GazeFront_Stat : 4|1@1+ (1,0) [0|1] ""  DASCU
 SG_ IC_GazeleftSide_Stat : 5|1@1+ (1,0) [0|1] ""  DASCU
 SG_ IC_ViewRoadSide_Stat : 7|1@1+ (1,0) [0|1] ""  DASCU
 SG_ IC_GazeRightSide_Stat : 6|1@1+ (1,0) [0|1] ""  DASCU

BO_ 743 IC_ABSOLUTE_CLOCK: 6 CGW
 SG_ IC_AbsoluteDateAndTime : 0|32@1+ (1,0) [0|4294967295] ""  DASCU
 SG_ IC_ABSOLUTE_CLOCK_RC : 36|4@1+ (1,0) [0|15] ""  DASCU
 SG_ IC_ABSOLUTE_CLOCK_CS : 40|8@1+ (1,0) [0|255] ""  DASCU

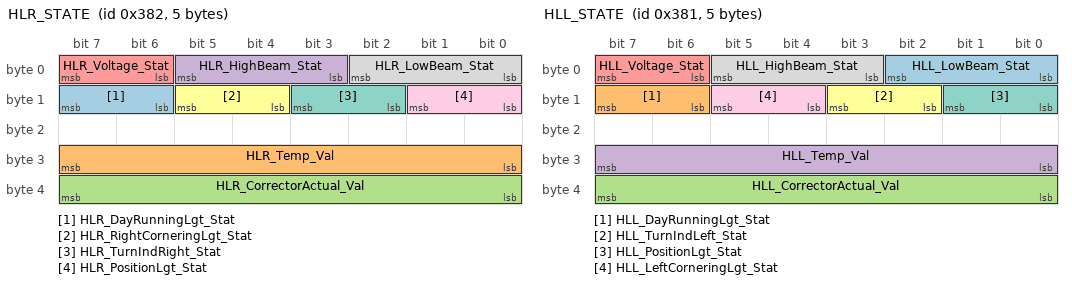
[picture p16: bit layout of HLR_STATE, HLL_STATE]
BO_ 898 HLR_STATE: 5 HLR
 SG_ HLR_DayRunningLgt_Stat : 14|2@1+ (1,0) [0|2] ""  BCM,mLEDR
 SG_ HLR_Temp_Val : 24|8@1+ (1,-40) [-40|150] "°C"  BCM,mLEDR
 SG_ HLR_CorrectorActual_Val : 32|8@1+ (1,0) [0|255] ""  DASCU,mLEDR,BCM
 SG_ HLR_HighBeam_Stat : 3|3@1+ (1,0) [0|4] ""  BCM,mLEDR
 SG_ HLR_Voltage_Stat : 6|2@1+ (1,0) [0|2] ""  BCM,mLEDR
 SG_ HLR_RightCorneringLgt_Stat : 12|2@1+ (1,0) [0|2] ""  mLEDR,BCM
 SG_ HLR_TurnIndRight_Stat : 10|2@1+ (1,0) [0|2] ""  BCM,mLEDR
 SG_ HLR_LowBeam_Stat : 0|3@1+ (1,0) [0|6] ""  BCM,mLEDR
 SG_ HLR_PositionLgt_Stat : 8|2@1+ (1,0) [0|2] ""  BCM,mLEDR

BO_ 897 HLL_STATE: 5 HLL
 SG_ HLL_LowBeam_Stat : 0|3@1+ (1,0) [0|6] ""  mLEDL,BCM
 SG_ HLL_DayRunningLgt_Stat : 14|2@1+ (1,0) [0|2] ""  mLEDL,BCM
 SG_ HLL_CorrectorActual_Val : 32|8@1+ (1,0) [0|255] ""  DASCU,mLEDL,BCM
 SG_ HLL_Temp_Val : 24|8@1+ (1,-40) [-40|150] "°C"  BCM,mLEDL
 SG_ HLL_Voltage_Stat : 6|2@1+ (1,0) [0|2] ""  mLEDL,BCM
 SG_ HLL_TurnIndLeft_Stat : 10|2@1+ (1,0) [0|2] ""  mLEDL,BCM
 SG_ HLL_PositionLgt_Stat : 8|2@1+ (1,0) [0|2] ""  mLEDL,BCM
 SG_ HLL_HighBeam_Stat : 3|3@1+ (1,0) [0|4] ""  BCM,mLEDL
 SG_ HLL_LeftCorneringLgt_Stat : 12|2@1+ (1,0) [0|2] ""  mLEDL,BCM

BO_ 1428 FIU_Msg3: 8 CGW
 SG_ FIU_FR_Synx_Req : 6|2@1+ (1,0) [0|2] "" Vector__XXX
 SG_ FIU_FL_Synx_Req : 4|2@1+ (1,0) [0|2] "" Vector__XXX
 SG_ FIU_ReduceChrgCurr_Stat : 38|1@1+ (1,0) [0|1] "" Vector__XXX
 SG_ FIU_SchedWed_Stat : 13|1@1+ (1,0) [0|1] "" Vector__XXX
 SG_ FIU_SchedTue_Stat : 12|1@1+ (1,0) [0|1] "" Vector__XXX
 SG_ FIU_SchedThu_Stat : 14|1@1+ (1,0) [0|1] "" Vector__XXX
 SG_ FIU_SchedSu_Stat : 25|1@1+ (1,0) [0|1] "" Vector__XXX
 SG_ FIU_SchedStart_Stat : 31|1@1+ (1,0) [0|1] "" Vector__XXX
 SG_ FIU_SchedSat_Stat : 24|1@1+ (1,0) [0|1] "" Vector__XXX
 SG_ FIU_SchedMon_Stat : 39|1@1+ (1,0) [0|1] "" Vector__XXX
 SG_ FIU_SchedFri_Stat : 15|1@1+ (1,0) [0|1] "" Vector__XXX
 SG_ FIU_SchedEnd_Stat : 53|1@1+ (1,0) [0|1] "" Vector__XXX
 SG_ FIU_Sched_StartTimeMinutes_Val : 40|4@1+ (5,0) [0|55] "min" Vector__XXX
 SG_ FIU_Sched_StartTimeHours_Val : 26|5@1+ (1,0) [0|24] "h" Vector__XXX
 SG_ FIU_Sched_EndTimeMinutes_Val : 44|4@1+ (5,0) [0|55] "min" Vector__XXX
 SG_ FIU_Sched_EndTimeHours_Val : 48|5@1+ (1,0) [0|24] "h" Vector__XXX
 SG_ FIU_PrepearClim_Stat : 54|1@1+ (1,0) [0|1] "" Vector__XXX
 SG_ FIU_DischrgLim_Val : 35|3@1+ (10,0) [20|60] "%" Vector__XXX
 SG_ FIU_ProjectionLiveObj_Req : 23|1@1+ (1,0) [0|1] ""  DASCU
 SG_ FIU_ProjectionNavigation_Req : 22|1@1+ (1,0) [0|1] ""  DASCU
 SG_ FIU_ProjectionRoadSigns_Req : 21|1@1+ (1,0) [0|1] ""  DASCU
 SG_ FIU_ProjectionOnRoad_Req : 18|1@1+ (1,0) [0|1] ""  DASCU
 SG_ FIU_RR_Synx_Req : 10|2@1+ (1,0) [0|2] "" Vector__XXX
 SG_ FIU_RL_Synx_Req : 8|2@1+ (1,0) [0|2] "" Vector__XXX
 SG_ FIU_ChrgLim_Val : 32|3@1+ (10,0) [60|100] "%" Vector__XXX
 SG_ FIU_ICimage_Req : 16|2@1+ (1,0) [0|3] "" Vector__XXX
 SG_ FIU_RearSideWindowsElcrome_Req : 19|2@1+ (1,0) [0|3] "" Vector__XXX
 SG_ FIU_ArmrestHeatFL_Req : 0|1@1+ (1,0) [0|1] "" Vector__XXX
 SG_ FIU_ArmrestHeatRL_Req : 2|1@1+ (1,0) [0|1] "" Vector__XXX
 SG_ FIU_ArmrestHeatFR_Req : 1|1@1+ (1,0) [0|1] "" Vector__XXX
 SG_ FIU_ArmrestHeatRR_Req : 3|1@1+ (1,0) [0|1] "" Vector__XXX

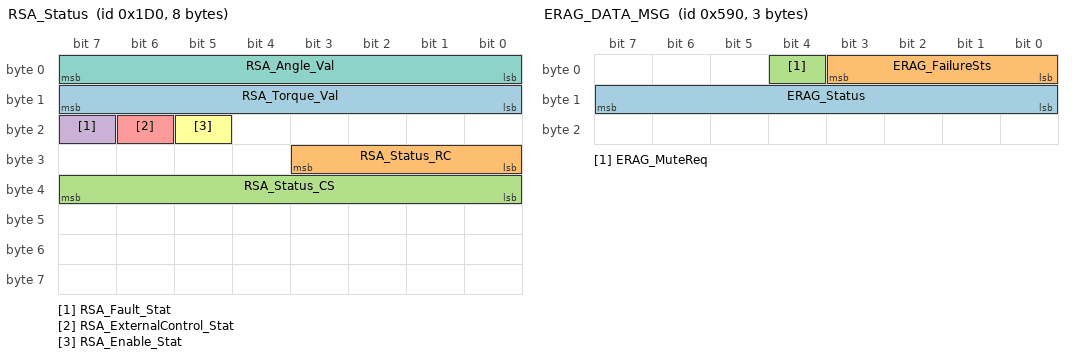
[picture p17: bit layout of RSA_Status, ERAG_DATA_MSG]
BO_ 464 RSA_Status: 8 CGW
 SG_ RSA_Torque_Val : 8|8@1+ (0.125,-15.875) [-15.875|15.875] "Nm"  DASCU
 SG_ RSA_Status_RC : 24|4@1+ (1,0) [0|15] ""  DASCU
 SG_ RSA_Status_CS : 32|8@1+ (1,0) [0|255] ""  DASCU
 SG_ RSA_Fault_Stat : 23|1@1+ (1,0) [0|1] ""  DASCU
 SG_ RSA_ExternalControl_Stat : 22|1@1+ (1,0) [0|1] ""  DASCU
 SG_ RSA_Enable_Stat : 21|1@1+ (1,0) [0|1] ""  DASCU
 SG_ RSA_Angle_Val : 0|8@1+ (0.1,-12.7) [-12.7|12.7] "°"  DASCU

BO_ 1198 ERAG_NMEA6: 8 CGW
 SG_ NMEA6_Sig : 0|64@1+ (1,0) [0|1.84467440737096E+019] ""  DASCU

BO_ 1196 ERAG_NMEA5: 8 CGW
 SG_ NMEA5_Sig : 0|64@1+ (1,0) [0|1.84467440737096E+019] ""  DASCU

BO_ 1194 ERAG_NMEA4: 8 CGW
 SG_ NMEA4_Sig : 0|64@1+ (1,0) [0|1.84467440737096E+019] ""  DASCU

BO_ 1192 ERAG_NMEA3: 8 CGW
 SG_ NMEA3_Sig : 0|64@1+ (1,0) [0|1.84467440737096E+019] ""  DASCU

BO_ 1190 ERAG_NMEA2: 8 CGW
 SG_ NMEA2_Sig : 0|64@1+ (1,0) [0|1.84467440737096E+019] ""  DASCU

BO_ 1188 ERAG_NMEA1: 8 CGW
 SG_ NMEA1_Sig : 0|64@1+ (1,0) [0|1.84467440737096E+019] ""  DASCU

BO_ 1424 ERAG_DATA_MSG: 3 CGW
 SG_ ERAG_Status : 8|8@1+ (1,0) [0|255] ""  DASCU
 SG_ ERAG_FailureSts : 0|4@1+ (1,0) [0|6] ""  DASCU
 SG_ ERAG_MuteReq : 4|1@1+ (1,0) [0|1] ""  DASCU

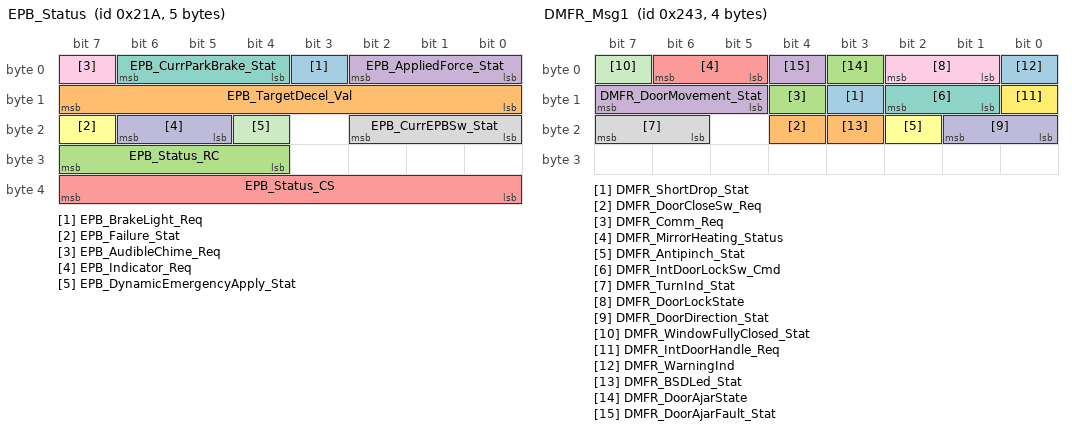
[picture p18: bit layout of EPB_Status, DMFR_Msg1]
BO_ 538 EPB_Status: 5 CGW
 SG_ EPB_BrakeLight_Req : 3|1@1+ (1,0) [0|1] "" Vector__XXX
 SG_ EPB_TargetDecel_Val : 8|8@1+ (0.05,-4) [-4|8] "m/s^2" Vector__XXX
 SG_ EPB_Status_RC : 28|4@1+ (1,0) [0|15] ""  DASCU
 SG_ EPB_AppliedForce_Stat : 0|3@1+ (1,0) [0|3] "" Vector__XXX
 SG_ EPB_Status_CS : 32|8@1+ (1,0) [0|255] ""  DASCU
 SG_ EPB_Failure_Stat : 23|1@1+ (1,0) [0|1] "" Vector__XXX
 SG_ EPB_CurrParkBrake_Stat : 4|3@1+ (1,0) [0|5] ""  DASCU
 SG_ EPB_CurrEPBSw_Stat : 16|3@1+ (1,0) [0|3] "" Vector__XXX
 SG_ EPB_AudibleChime_Req : 7|1@1+ (1,0) [0|1] "" Vector__XXX
 SG_ EPB_Indicator_Req : 21|2@1+ (1,0) [0|3] "" Vector__XXX
 SG_ EPB_DynamicEmergencyApply_Stat : 20|1@1+ (1,0) [0|1] ""  DASCU

BO_ 582 DMRR_Msg1: 5 CGW
 SG_ DMRR_DoorCloseSw_Req : 4|1@1+ (1,0) [0|1] "" Vector__XXX
 SG_ DMRR_DoorDirection_Stat : 24|2@1+ (1,0) [0|2] "" Vector__XXX
 SG_ DMRR_ChildLock_Stat : 8|2@1+ (1,0) [0|2] "" Vector__XXX
 SG_ DMRR_DoorMovement_Stat : 20|3@1+ (1,0) [0|4] "" Vector__XXX
 SG_ DMRR_RearCurtain_Req : 36|2@1+ (1,0) [0|2] "" Vector__XXX
 SG_ DMRR_IntDoorHandle_Req : 5|1@1+ (1,0) [0|1] ""  DASCU
 SG_ DMRR_WarningInd : 0|1@1+ (1,0) [0|1] "" Vector__XXX
 SG_ DMRR_VolumeLevel_Cmd : 10|3@1+ (1,0) [0|4] "" Vector__XXX
 SG_ DMRR_WindowFullyClosed_Stat : 13|1@1+ (1,0) [0|1] "" Vector__XXX
 SG_ DMRR_Comm_Req : 18|1@1+ (1,0) [0|1] "" Vector__XXX
 SG_ DMRR_ElcromeBright_Stat : 30|2@1+ (1,0) [0|3] "" Vector__XXX
 SG_ DMRR_DoorLockState : 1|2@1+ (1,0) [0|2] "" Vector__XXX
 SG_ DMRR_Multimedia_Req : 16|2@1+ (1,0) [0|2] "" Vector__XXX
 SG_ DMRR_Antipinch_Stat : 23|1@1+ (1,0) [0|1] "" Vector__XXX
 SG_ DMRR_RL_Window_Cmd : 27|3@1+ (1,0) [0|4] "" Vector__XXX
 SG_ DMRR_IntDoorLockSw_Cmd : 6|2@1+ (1,0) [0|2] "" Vector__XXX
 SG_ DMRR_SunShade_Stat : 32|3@1+ (1,0) [0|4] "" Vector__XXX
 SG_ DMRR_DoorAjarState : 3|1@1+ (1,0) [0|1] ""  DASCU
 SG_ DMRR_DoorAjarFault_Stat : 19|1@1+ (1,0) [0|1] "" Vector__XXX

BO_ 581 DMRL_Msg1: 5 CGW
 SG_ DMRL_DoorCloseSw_Req : 4|1@1+ (1,0) [0|1] "" Vector__XXX
 SG_ DMRL_WindowFullyClosed_Stat : 13|1@1+ (1,0) [0|1] "" Vector__XXX
 SG_ DMRL_ChildLock_Stat : 8|2@1+ (1,0) [0|2] "" Vector__XXX
 SG_ DMRL_IntDoorHandle_Req : 5|1@1+ (1,0) [0|1] ""  DASCU
 SG_ DMRL_IntDoorLockSw_Cmd : 6|2@1+ (1,0) [0|2] "" Vector__XXX
 SG_ DMRL_DoorLockState : 1|2@1+ (1,0) [0|2] "" Vector__XXX
 SG_ DMRL_ElcromeBright_Stat : 30|2@1+ (1,0) [0|3] "" Vector__XXX
 SG_ DMRL_DoorMovement_Stat : 20|3@1+ (1,0) [0|4] "" Vector__XXX
 SG_ DMRL_RR_Window_Cmd : 27|3@1+ (1,0) [0|4] "" Vector__XXX
 SG_ DMRL_RearCurtain_Req : 36|2@1+ (1,0) [0|2] "" Vector__XXX
 SG_ DMRL_DoorDirection_Stat : 24|2@1+ (1,0) [0|2] "" Vector__XXX
 SG_ DMRL_Antipinch_Stat : 23|1@1+ (1,0) [0|1] "" Vector__XXX
 SG_ DMRL_WarningInd : 0|1@1+ (1,0) [0|1] "" Vector__XXX
 SG_ DMRL_VolumeLevel_Cmd : 10|3@1+ (1,0) [0|4] "" Vector__XXX
 SG_ DMRL_Multimedia_Req : 16|2@1+ (1,0) [0|2] "" Vector__XXX
 SG_ DMRL_Comm_Req : 18|1@1+ (1,0) [0|1] "" Vector__XXX
 SG_ DMRL_SunShade_Stat : 32|3@1+ (1,0) [0|4] "" Vector__XXX
 SG_ DMRL_DoorAjarState : 3|1@1+ (1,0) [0|1] ""  DASCU
 SG_ DMRL_DoorAjarFault_Stat : 19|1@1+ (1,0) [0|1] "" Vector__XXX

BO_ 579 DMFR_Msg1: 4 CGW
 SG_ DMFR_ShortDrop_Stat : 11|1@1+ (1,0) [0|1] "" Vector__XXX
 SG_ DMFR_DoorCloseSw_Req : 20|1@1+ (1,0) [0|1] "" Vector__XXX
 SG_ DMFR_Comm_Req : 12|1@1+ (1,0) [0|1] "" Vector__XXX
 SG_ DMFR_DoorMovement_Stat : 13|3@1+ (1,0) [0|4] "" Vector__XXX
 SG_ DMFR_MirrorHeating_Status : 5|2@1+ (1,0) [0|3] "" Vector__XXX
 SG_ DMFR_Antipinch_Stat : 18|1@1+ (1,0) [0|1] "" Vector__XXX
 SG_ DMFR_IntDoorLockSw_Cmd : 9|2@1+ (1,0) [0|2] "" Vector__XXX
 SG_ DMFR_TurnInd_Stat : 22|2@1+ (1,0) [0|2] "" Vector__XXX
 SG_ DMFR_DoorLockState : 1|2@1+ (1,0) [0|2] "" Vector__XXX
 SG_ DMFR_DoorDirection_Stat : 16|2@1+ (1,0) [0|2] "" Vector__XXX
 SG_ DMFR_WindowFullyClosed_Stat : 7|1@1+ (1,0) [0|1] "" Vector__XXX
 SG_ DMFR_IntDoorHandle_Req : 8|1@1+ (1,0) [0|1] ""  DASCU
 SG_ DMFR_WarningInd : 0|1@1+ (1,0) [0|1] "" Vector__XXX
 SG_ DMFR_BSDLed_Stat : 19|1@1+ (1,0) [0|1] "" Vector__XXX
 SG_ DMFR_DoorAjarState : 3|1@1+ (1,0) [0|1] ""  DASCU
 SG_ DMFR_DoorAjarFault_Stat : 4|1@1+ (1,0) [0|1] "" Vector__XXX

BO_ 580 DMFL_Msg1: 8 CGW
 SG_ DMFL_ChildLockRRTab_Stat : 15|1@1+ (1,0) [0|1] "" Vector__XXX
 SG_ DMFL_ChildLockRLTab_Stat : 12|1@1+ (1,0) [0|1] "" Vector__XXX
 SG_ DMFL_ShortDrop_Stat : 44|1@1+ (1,0) [0|1] "" Vector__XXX
 SG_ DMFL_ChildLockCentralTab_Stat : 6|1@1+ (1,0) [0|1] "" Vector__XXX
 SG_ DMFL_DoorCloseSw_Req : 7|1@1+ (1,0) [0|1] "" Vector__XXX
 SG_ DMFL_RightMirrorFold_Cmd : 30|2@1+ (1,0) [0|2] "" Vector__XXX
 SG_ DMFL_DoorMovement_Stat : 36|3@1+ (1,0) [0|4] "" Vector__XXX
 SG_ DMFL_KeyCylinder_Req : 0|2@1+ (1,0) [0|3] "" Vector__XXX
 SG_ DMFL_DoorLockState : 3|2@1+ (1,0) [0|2] "" Vector__XXX
 SG_ DMFL_RRWindow_Cmd : 24|3@1+ (1,0) [0|4] "" Vector__XXX
 SG_ DMFL_ChildLock_RRdoor_Stat : 52|1@1+ (1,0) [0|1] "" Vector__XXX
 SG_ DMFL_ChildLock_RLwindow_Stat : 11|1@1+ (1,0) [0|1] "" Vector__XXX
 SG_ DMFL_WindowFullyClosed_Stat : 32|1@1+ (1,0) [0|1] "" Vector__XXX
 SG_ DMFL_ChildLock_RRwindow_Stat : 47|1@1+ (1,0) [0|1] "" Vector__XXX
 SG_ DMFL_BSDLed_Stat : 42|1@1+ (1,0) [0|1] "" Vector__XXX
 SG_ DMFL_IntDoorHandle_Req : 10|1@1+ (1,0) [0|1] ""  DASCU
 SG_ DMFL_TurnInd_Stat : 45|2@1+ (1,0) [0|2] "" Vector__XXX
 SG_ DMFL_Antipinch_Stat : 39|1@1+ (1,0) [0|1] "" Vector__XXX
 SG_ DMFL_WarningInd : 2|1@1+ (1,0) [0|1] "" Vector__XXX
 SG_ DMFL_Comm_Req : 34|1@1+ (1,0) [0|1] "" Vector__XXX
 SG_ DMFL_RightMirrorTilt_Cmd : 23|1@1+ (1,0) [0|1] "" Vector__XXX
 SG_ DMFL_RLWindow_Cmd : 20|3@1+ (1,0) [0|4] "" Vector__XXX
 SG_ DMFL_RearWindowCurtain_Req : 48|2@1+ (1,0) [0|2] "" Vector__XXX
 SG_ DMFL_ChildLock_RLdoor_Stat : 50|1@1+ (1,0) [0|1] "" Vector__XXX
 SG_ DMFL_RightMirrorAdjust_Cmd : 27|3@1+ (1,0) [0|4] "" Vector__XXX
 SG_ DMFL_ChildLock_Stat : 35|1@1+ (1,0) [0|1] "" Vector__XXX
 SG_ DMFL_MirrorHeating_Status : 8|2@1+ (1,0) [0|3] "" Vector__XXX
 SG_ DMFL_IntDoorLockSw_Cmd : 13|2@1+ (1,0) [0|2] "" Vector__XXX
 SG_ DMFL_FRWindow_Cmd : 17|3@1+ (1,0) [0|4] "" Vector__XXX
 SG_ DMFL_DoorDirection_Stat : 40|2@1+ (1,0) [0|2] "" Vector__XXX
 SG_ DMFL_DoorAjarState : 5|1@1+ (1,0) [0|1] ""  DASCU
 SG_ DMFL_DoorAjarFault_Stat : 43|1@1+ (1,0) [0|1] "" Vector__XXX

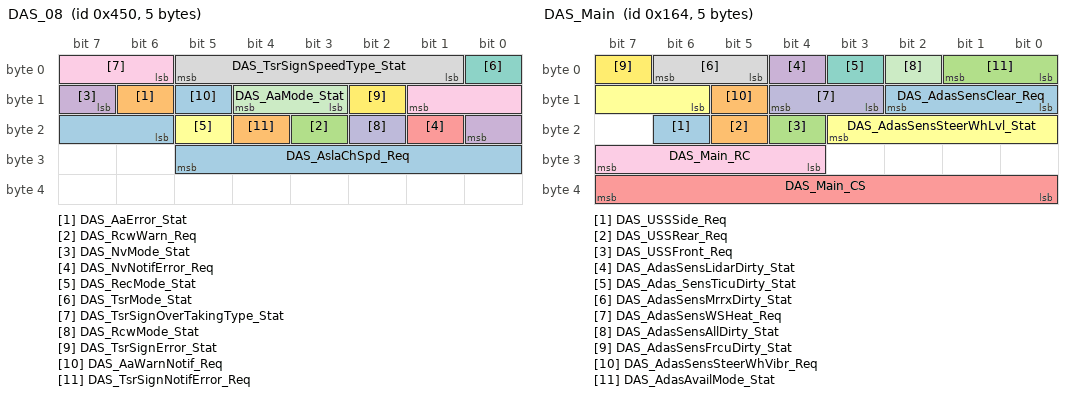
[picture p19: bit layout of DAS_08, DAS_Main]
BO_ 1104 DAS_08: 5 DASCU
 SG_ DAS_AslaChSpd_Req : 22|8@1+ (1,0) [0|254] "km"  CGW
 SG_ DAS_AaError_Stat : 14|1@1+ (1,0) [0|1] ""  CGW
 SG_ DAS_RcwWarn_Req : 19|1@1+ (1,0) [0|1] ""  BCM,CGW
 SG_ DAS_NvMode_Stat : 15|2@1+ (1,0) [0|2] ""  CGW
 SG_ DAS_NvNotifError_Req : 17|1@1+ (1,0) [0|1] ""  CGW
 SG_ DAS_RecMode_Stat : 21|1@1+ (1,0) [0|1] ""  CGW
 SG_ DAS_TsrMode_Stat : 0|1@1+ (1,0) [0|1] ""  CGW
 SG_ DAS_TsrSignSpeedType_Stat : 1|5@1+ (1,0) [0|20] ""  CGW
 SG_ DAS_TsrSignOverTakingType_Stat : 6|4@1+ (1,0) [0|11] ""  CGW
 SG_ DAS_RcwMode_Stat : 18|1@1+ (1,0) [0|1] ""  CGW
 SG_ DAS_AaMode_Stat : 11|2@1+ (1,0) [0|2] ""  CGW
 SG_ DAS_TsrSignError_Stat : 10|1@1+ (1,0) [0|1] ""  CGW
 SG_ DAS_AaWarnNotif_Req : 13|1@1+ (1,0) [0|1] ""  CGW
 SG_ DAS_TsrSignNotifError_Req : 20|1@1+ (1,0) [0|1] ""  CGW

BO_ 523 DAS_07: 6 DASCU
 SG_ DAS_LdpNotifError_Req : 29|1@1+ (1,0) [0|1] ""  CGW
 SG_ DAS_ALccNotifError_Req : 12|1@1+ (1,0) [0|1] ""  CGW
 SG_ DAS_LdpRightLaneWarn_Req : 11|1@1+ (1,0) [0|1] ""  CGW
 SG_ DAS_LdpLeftLaneWarn_Req : 10|1@1+ (1,0) [0|1] ""  CGW
 SG_ DAS_LdwLeftLaneWarn_Req : 13|1@1+ (1,0) [0|1] ""  CGW
 SG_ DAS_LkaWarnNotif_Req : 2|1@1+ (1,0) [0|1] ""  CGW
 SG_ DAS_LkaNotifError_Req : 3|1@1+ (1,0) [0|1] ""  CGW
 SG_ DAS_DowMode_Stat : 19|1@1+ (1,0) [0|1] ""  CGW,BCM
 SG_ DAS_LccLeftWarn_Req : 24|1@1+ (1,0) [0|1] ""  BCM,CGW
 SG_ DAS_LccRightLed_Req : 21|1@1+ (1,0) [0|3] ""  BCM,CGW
 SG_ DAS_LdwSound_Req : 15|1@1+ (1,0) [0|1] ""  CGW
 SG_ DAS_07_RC : 36|4@1+ (1,0) [0|15] ""  CGW,BCM
 SG_ DAS_RdaNotifError_Req : 6|1@1+ (1,0) [0|1] ""  BCM,CGW
 SG_ DAS_LccNotifError_Req : 27|1@1+ (1,0) [0|1] ""  CGW,BCM
 SG_ DAS_LkaShootdownSound_Req : 1|1@1+ (1,0) [0|1] ""  CGW
 SG_ DAS_LccSound_Req : 26|1@1+ (1,0) [0|1] ""  BCM,CGW
 SG_ DAS_LdwMode_Stat : 7|3@1+ (1,0) [0|4] ""  BCM,CGW
 SG_ DAS_LccLeftLed_Req : 20|1@1+ (1,0) [0|3] ""  BCM,CGW
 SG_ DAS_LdwNotifError_Req : 16|1@1+ (1,0) [0|1] ""  CGW
 SG_ DAS_DowNotifError_Req : 28|1@1+ (1,0) [0|1] ""  CGW,BCM
 SG_ DAS_RctcWarn_Req : 5|1@1+ (1,0) [0|1] ""  CGW,BCM
 SG_ DAS_RdaWarn_Req : 4|1@1+ (1,0) [0|1] ""  BCM,CGW
 SG_ DAS_LdwRightLaneWarn_Req : 14|1@1+ (1,0) [0|1] ""  CGW
 SG_ DAS_LkaWarnSound_Req : 0|1@1+ (1,0) [0|1] ""  CGW
 SG_ DAS_LccRightWarn_Req : 25|1@1+ (1,0) [0|1] ""  CGW,BCM
 SG_ DAS_07_CS : 40|8@1+ (1,0) [0|255] ""  CGW,BCM
 SG_ DAS_LccMode_Stat : 17|2@1+ (1,0) [0|2] ""  BCM,CGW

BO_ 356 DAS_Main: 5 DASCU
 SG_ DAS_USSSide_Req : 22|1@1+ (1,0) [0|1] ""  CGW
 SG_ DAS_USSRear_Req : 21|1@1+ (1,0) [0|1] ""  CGW
 SG_ DAS_USSFront_Req : 20|1@1+ (1,0) [0|1] ""  CGW
 SG_ DAS_AdasSensLidarDirty_Stat : 4|1@1+ (1,0) [0|1] ""  CGW,BCM
 SG_ DAS_Main_CS : 32|8@1+ (1,0) [0|255] ""  BCM,CGW
 SG_ DAS_AdasSensSteerWhLvl_Stat : 14|6@1+ (1,0) [0|63] ""  CGW,BCM
 SG_ DAS_Adas_SensTicuDirty_Stat : 3|1@1+ (1,0) [0|1] ""  BCM,CGW
 SG_ DAS_AdasSensMrrxDirty_Stat : 5|2@1+ (1,0) [0|3] ""  BCM,CGW
 SG_ DAS_Main_RC : 28|4@1+ (1,0) [0|15] ""  BCM,CGW
 SG_ DAS_AdasSensWSHeat_Req : 11|2@1+ (1,0) [0|3] ""  BCM,CGW
 SG_ DAS_AdasSensAllDirty_Stat : 2|1@1+ (1,0) [0|1] ""  CGW,BCM
 SG_ DAS_AdasSensFrcuDirty_Stat : 7|1@1+ (1,0) [0|1] ""  BCM,CGW
 SG_ DAS_AdasSensClear_Req : 8|3@1+ (1,0) [0|4] ""  BCM,CGW
 SG_ DAS_AdasSensSteerWhVibr_Req : 13|1@1+ (1,0) [0|1] ""  CGW,BCM
 SG_ DAS_AdasAvailMode_Stat : 0|2@1+ (1,0) [0|2] ""  CGW

BO_ 353 DAS_FIU_Settings: 8 DASCU
 SG_ DAS_SettRdaAutoBrake_Stat : 48|1@1+ (1,0) [0|1] ""  CGW
 SG_ DAS_ProjectionRoadSigns_Req : 45|1@1+ (1,0) [0|1] ""  CGW
 SG_ DAS_ProjectionOnRoad_Req : 44|1@1+ (1,0) [0|1] ""  CGW
 SG_ DAS_ProjectionNavigation_Req : 46|1@1+ (1,0) [0|1] ""  CGW
 SG_ DAS_ProjectionLiveObj_Req : 47|1@1+ (1,0) [0|1] ""  CGW
 SG_ DAS_SettFcwMode_Stat : 14|2@1+ (1,0) [0|2] ""  CGW
 SG_ DAS_SettRda_Stat : 36|1@1+ (1,0) [0|1] ""  CGW
 SG_ DAS_SettLdwVibration_Stat : 28|1@1+ (1,0) [0|1] ""  CGW
 SG_ DAS_SettRctc_Stat : 37|1@1+ (1,0) [0|1] ""  CGW
 SG_ DAS_SettAa_Stat : 32|1@1+ (1,0) [0|1] ""  CGW
 SG_ DAS_SettLdw_Stat : 26|1@1+ (1,0) [0|1] ""  CGW
 SG_ DAS_SettLdwSound_Stat : 29|1@1+ (1,0) [0|1] ""  CGW
 SG_ DAS_SettLdp_Stat : 30|1@1+ (1,0) [0|1] ""  CGW
 SG_ DAS_SettLcc_Stat : 18|1@1+ (1,0) [0|1] ""  CGW
 SG_ DAS_SettLdwMode_Stat : 27|1@1+ (1,0) [0|1] ""  CGW
 SG_ DAS_SettLka_Stat : 6|1@1+ (1,0) [0|1] ""  CGW
 SG_ DAS_SettFcw_Stat : 7|1@1+ (1,0) [0|1] ""  CGW
 SG_ DAS_SettRecResol_Stat : 40|1@1+ (1,0) [0|1] ""  CGW
 SG_ DAS_SettSensClean_Stat : 43|1@1+ (1,0) [0|1] ""  CGW
 SG_ DAS_SettCcMode_Stat : 3|2@1+ (1,0) [0|2] ""  CGW
 SG_ DAS_SettLccSound_Stat : 22|1@1+ (1,0) [0|1] ""  CGW
 SG_ DAS_SettRec_Stat : 39|1@1+ (1,0) [0|1] ""  CGW
 SG_ DAS_SettDowSound_Stat : 25|1@1+ (1,0) [0|1] ""  CGW
 SG_ DAS_SettAaMode_Stat : 33|1@1+ (1,0) [0|1] ""  CGW
 SG_ DAS_SettAfs_Stat : 35|1@1+ (1,0) [0|1] ""  CGW
 SG_ DAS_SettTsr_Stat : 31|1@1+ (1,0) [0|1] ""  CGW
 SG_ DAS_SettLccMode_Stat : 19|2@1+ (1,0) [0|2] ""  CGW
 SG_ DAS_FIU_Settings_RC : 52|4@1+ (1,0) [0|15] ""  CGW
 SG_ DAS_SettRecFileSize_Stat : 41|2@1+ (1,0) [0|2] ""  CGW
 SG_ DAS_SettDow_Stat : 24|1@1+ (1,0) [0|1] ""  CGW
 SG_ DAS_SettAslaOver_Stat : 8|6@1+ (1,0) [0|60] "km/h"  CGW
 SG_ DAS_SettLccVibration_Stat : 21|1@1+ (1,0) [0|1] ""  CGW
 SG_ DAS_SettFcwVibration_Stat : 16|1@1+ (1,0) [0|1] ""  CGW
 SG_ DAS_SettCcSpdCorrect_Stat : 34|1@1+ (1,0) [0|1] ""  CGW
 SG_ DAS_SettCcType_Stat : 0|2@1+ (1,0) [0|3] ""  CGW
 SG_ DAS_SettAlcc_Stat : 23|1@1+ (1,0) [0|1] ""  CGW
 SG_ DAS_FIU_Settings_CS : 56|8@1+ (1,0) [0|255] ""  CGW
 SG_ DAS_SettAsla_Stat : 5|1@1+ (1,0) [0|1] ""  CGW
 SG_ DAS_SettAeb_Stat : 17|1@1+ (1,0) [0|1] ""  CGW

BO_ 778 DAS_03: 8 DASCU
 SG_ DAS_LkaShootdownNotif_Req : 15|1@1+ (1,0) [0|1] ""  CGW
 SG_ DAS_MliaStreetLigth_Stat : 36|1@1+ (1,0) [0|1] ""  BCM
 SG_ DAS_AccToCc_Req : 12|1@1+ (1,0) [0|1] ""  CGW
 SG_ DAS_AccNotifError_Req : 13|1@1+ (1,0) [0|1] ""  CGW
 SG_ DAS_LimNotifError_Req : 14|1@1+ (1,0) [0|1] ""  CGW
 SG_ DAS_AebUnAvaliable_Stat : 31|1@1+ (1,0) [0|1] ""  CGW
 SG_ DAS_LkaAngleSpeed_Req : 40|10@1- (1,0) [0|1023] ""  CGW
 SG_ DAS_AebDeactivNotif_Stat : 16|1@1+ (1,0) [0|1] ""  CGW
 SG_ DAS_CcSetDist_Stat : 10|2@1+ (1,0) [0|3] ""  CGW
 SG_ DAS_CcReject_Req : 20|3@1+ (1,0) [0|6] ""  CGW
 SG_ DAS_CcNotifError_Req : 28|1@1+ (1,0) [0|1] ""  CGW
 SG_ DAS_FcwSoundWarn_Req : 18|1@1+ (1,0) [0|1] ""  CGW
 SG_ DAS_AslaMode_Stat : 29|1@1+ (1,0) [0|1] ""  CGW
 SG_ DAS_CcTargetId_Stat : 23|1@1+ (1,0) [0|1] ""  CGW
 SG_ DAS_AebNotifError_Req : 19|1@1+ (1,0) [0|1] ""  CGW
 SG_ DAS_FcwNotifError_Req : 38|1@1+ (1,0) [0|1] ""  CGW
 SG_ DAS_FcwMode_Stat : 39|1@1+ (1,0) [0|1] ""  CGW
 SG_ DAS_CcType_Stat : 0|2@1+ (1,0) [0|3] ""  CGW,BCM
 SG_ DAS_CcSleep_Stat : 27|1@1+ (1,0) [0|1] ""  CGW
 SG_ DAS_FcwActivNotif_Req : 17|1@1+ (1,0) [0|1] ""  CGW
 SG_ DAS_03_RC : 52|4@1+ (1,0) [0|15] ""  CGW
 SG_ DAS_CcSetSpeed_Stat : 2|8@1+ (1,0) [0|255] "km/h"  CGW
 SG_ DAS_03_CS : 56|8@1+ (1,0) [0|255] ""  CGW
 SG_ DAS_MliaMode_Stat : 33|2@1+ (1,0) [0|3] ""  BCM
 SG_ DAS_MliaFuncError_Stat : 35|1@1+ (1,0) [0|1] ""  BCM

BO_ 642 BCM_Veh_State2: 6 CGW
 SG_ BCM_RoofControl_Req : 46|2@1+ (1,0) [0|2] "" Vector__XXX
 SG_ BCM_AdasSensWSHeat_Req : 40|2@1+ (1,0) [0|3] ""  DASCU
 SG_ BCM_PanoramicViewLed_Cmd : 31|1@1+ (1,0) [0|1] "" Vector__XXX
 SG_ BCM_AntiTheft_Stat : 30|1@1+ (1,0) [0|1] "" Vector__XXX
 SG_ BCM_LccBtn_Stat : 24|1@1+ (1,0) [0|1] ""  DASCU
 SG_ BCM_LdwBtn_Stat : 25|1@1+ (1,0) [0|1] ""  DASCU
 SG_ BCM_AdasSensClear_Stat : 26|1@1+ (1,0) [0|1] ""  DASCU
 SG_ BCM_FootrestRRWarning_Stat : 18|1@1+ (1,0) [0|1] "" Vector__XXX
 SG_ BCM_AmbientTempHMI : 8|8@1+ (0.5,-50) [-50|75] "°C"  DASCU
 SG_ BCM_GovernmentComSw_Stat : 16|1@1+ (1,0) [0|1] "" Vector__XXX
 SG_ BCM_FootrestRLWarning_Stat : 7|1@1+ (1,0) [0|1] "" Vector__XXX
 SG_ BCM_MAS_Activation_Req : 0|2@1+ (1,0) [0|2] "" Vector__XXX
 SG_ BCM_EasyExitSMFL_Stat : 23|1@1+ (1,0) [0|1] "" Vector__XXX
 SG_ BCM_GovernmentHandset_Stat : 19|1@1+ (1,0) [0|1] "" Vector__XXX
 SG_ BCM_ElcromeMirror_Req : 32|8@1+ (0.394,0) [0|100.47] "" Vector__XXX
 SG_ BCM_HeadUpDispSw_Stat : 2|1@1+ (1,0) [0|1] "" Vector__XXX
 SG_ BCM_RearWindowHeatingLED : 17|1@1+ (1,0) [0|1] "" Vector__XXX
 SG_ BCM_EasyExitSMRL_Stat : 20|1@1+ (1,0) [0|1] "" Vector__XXX
 SG_ BCM_EasyExitSMRR_Stat : 21|1@1+ (1,0) [0|1] "" Vector__XXX
 SG_ BCM_EasyExitSMFR_Stat : 22|1@1+ (1,0) [0|1] "" Vector__XXX
 SG_ BCM_FootrestRR_Stat : 5|2@1+ (1,0) [0|3] "" Vector__XXX
 SG_ BCM_FootrestRL_Stat : 3|2@1+ (1,0) [0|3] "" Vector__XXX
 SG_ BCM_RemoteStart_Stat : 28|2@1+ (1,0) [0|3] "" Vector__XXX
 SG_ BCM_T15h_Deactivation_Req : 27|1@1+ (1,0) [0|1] "" Vector__XXX

CM_ BU_ mLEDR "mLEDR: matrix LED Right";
CM_ BU_ mLEDL "mLEDL: matrix LED Left";
CM_ BU_ TLR "TLR: Trunk Lid Light Right";
CM_ BU_ TLL "TLL: Trunk Lid Light Left";
CM_ BU_ RLR "RLR: Rear Light Right";
CM_ BU_ RLL "RLL: Rear Light Left";
CM_ BU_ HLR "HLR: Head Light Right";
CM_ BU_ HLL "HLL: Head Light Left";
CM_ BU_ DASCU "DASCU: Driving Assistance System Control Unit";
CM_ BU_ CGW "CGW: Central Gateway";
CM_ BU_ BCM "BCM: Body Control Module";
CM_ BO_ 3221225472 "This is a message for not used signals, created by Vector CANdb++ DBC OLE DB Provider.";
CM_ SG_ 3221225472 MAS_SteeringAngle_Req "Requested rotation angle by APA";
CM_ SG_ 3221225472 MAS_DistanceToGo_Val "The distance to travel";
CM_ SG_ 3221225472 MAS_TmissionMode_Req "The transmission state requested by APA";
CM_ SG_ 3221225472 VCU_DriveInfo_RC "Rolling Counter [0 - 15]";
CM_ SG_ 355 DAS_MASPermission_Stat "Permission from ADAS";
CM_ SG_ 355 DAS_MasStop_Req "Request to stop MAS";
CM_ SG_ 355 DAS_MasPause_Req "Request to pause MAS";
CM_ SG_ 355 DAS_DistanceTraveled_Val "Distance traveled by vehicle";
CM_ SG_ 355 DAS_MAS_RC "Rolling Counter [0 - 15]";
CM_ SG_ 355 DAS_MAS_CS "Checksum CRC8 SAE J1850 of the data field this message";
CM_ SG_ 640 BCM_T15_Stat "Terminal T15 state";
CM_ SG_ 640 BCM_CCTerm_Stat "Terminal to power climate system";
CM_ SG_ 640 BCM_SwIndIntens_Stat "Switches indicator intensity level";
CM_ SG_ 640 BCM_T30d_Stat "State of T30d terminal";
CM_ SG_ 640 BCM_IndFadingTime_Req "The timer for smoothly change switches intensity, when day detected.";
CM_ SG_ 640 HUD_IntensityRequest "Head-up display intensity value from RLS";
CM_ SG_ 640 StealthModeEn "Indicates that the Stealth mode  is required:
$0 = Stealth mode disable
$1 = Stealth mode enable";
CM_ SG_ 640 BCM_T30i_DisableWarning "$0 = No Warning 
$1 = Warning Active";
CM_ SG_ 640 BCM_T30i_Stat "State of T30i terminal";
CM_ SG_ 640 BCM_Light_Stat "Terminal to power individual light sections";
CM_ SG_ 640 BCM_LightBCM_Stat "Terminal to power all internal plafonds";
CM_ SG_ 640 BCM_CCTermDisableWarning "Indicates if CC terminal will be disconnected soon";
CM_ SG_ 640 BCM_SwBackIntens_Val "Background  illumination level of switches";
CM_ SG_ 640 BCM_LVBatteryVoltage "Indicates the battery voltage. Measurement from the Battery sensor";
CM_ SG_ 640 BCM_PreheatFunction_Stat "Status of Preheating function:
0x1 – If BCM_T15_Stat = 0x0 than Preheating Inprogress, ready to Preheating phase
0x1 - If BCM_T15_Stat = 0x1 than Additional Heating Active";
CM_ SG_ 640 BCM_ADASTerm_Stat "Terminal to power ADASCAN";
CM_ SG_ 640 BCM_VehicleBody_Stat "Vehicle's body type (sedan, limousine, etc.)";
CM_ SG_ 640 BCM_T30d_DisableWarning "T30d terminal warning status signal
3 sec before T30d off";
CM_ SG_ 640 BCM_VehicleType_Stat "Type of vehicle: armoured or not";
CM_ SG_ 640 BCM_T15h_Stat "Terminal 15h status";
CM_ SG_ 640 BCM_VehicleMode_Stat "Current vehicle state according Terminal concept";
CM_ SG_ 640 BCM_Vehicle_DrvMode "Vehicle drive mode, set by user";
CM_ SG_ 640 BCM_VehiclePowertrain_Stat "Type of vehicle powertrain";
CM_ SG_ 640 BCM_SPV_Feature_Stat "The flag, which provide an information about vehicle type.
Default value - 0x0 uses for commercial vehilces,
0x1 - SPV (Special purpose vehilces)  type uses for GON vehicles";
CM_ SG_ 1535 DAS_CaebConf_Stat "CAEB configuration status";
CM_ SG_ 1535 DAS_CcConf_Stat "CC configuration status";
CM_ SG_ 1535 DAS_AccConf_Stat "ACC configuration status";
CM_ SG_ 1535 DAS_LimConf_Stat "Lim configuration status";
CM_ SG_ 1535 DAS_AslaConf_Stat "ASLA configuration status";
CM_ SG_ 1535 DAS_LkaConf_Stat "LKA configuration status";
CM_ SG_ 1535 DAS_FcwConf_Stat "FCW configuration status";
CM_ SG_ 1535 DAS_AebConf_Stat "AEB configuration status";
CM_ SG_ 1535 DAS_LccConf_Stat "LCC configuration status";
CM_ SG_ 1535 DAS_AlccConf_Stat "ALCC configuration status";
CM_ SG_ 1535 DAS_DowConf_Stat "DOW configuration status";
CM_ SG_ 1535 DAS_LdwConf_Stat "LDW configuration status";
CM_ SG_ 1535 DAS_LdpConf_Stat "LDP configuration status";
CM_ SG_ 1535 DAS_TsrConf_Stat "TSR configuration status";
CM_ SG_ 1535 DAS_AaConf_Stat "AA configuration status";
CM_ SG_ 1535 DAS_AfsConf_Stat "AFS configuration status";
CM_ SG_ 1535 DAS_RdaConf_Stat "RDA configuration status";
CM_ SG_ 1535 DAS_RctcConf_Stat "RCTC configuration status";
CM_ SG_ 1535 DAS_RcwConf_Stat "RCW configuration status";
CM_ SG_ 1535 DAS_RecConf_Stat "REC (Recording video) configuration status";
CM_ SG_ 1535 DAS_NvConf_Stat "NV configuration status";
CM_ SG_ 1535 DAS_VisualConf_Stat "VISUAL configuration status";
CM_ SG_ 1535 DAS_Conf_RC "Rolling Counter [0 - 15]";
CM_ SG_ 1535 DAS_Conf_CS "Checksum CRC8 SAE J1850 of the data field this message";
CM_ SG_ 1535 DAS_MliaConf_Stat "MLIA configuration status";
CM_ SG_ 1309 BCM_LightAmbient_Val "RAW value of ambient light from light sensor";
CM_ SG_ 1309 BCM_LightFront_Val "RAW value of front light from light sensor";
CM_ SG_ 1309 BCM_LightSwReason_Val "This signal indicates which ambient conditions have been detected by the running light sensor";
CM_ SG_ 894 MAS_Sensor7_Distance_Val "Value of the signal corresponds to the distance in cm from the sensor to the obstacle";
CM_ SG_ 894 MAS_Sensor6_Distance_Val "Value of the signal corresponds to the distance in cm from the sensor to the obstacle";
CM_ SG_ 894 MAS_Sensor1_Distance_Val "Value of the signal corresponds to the distance in cm from the sensor to the obstacle";
CM_ SG_ 894 MAS_Sensor12_Distance_Val "Value of the signal corresponds to the distance in cm from the sensor to the obstacle";
CM_ SG_ 894 MAS_SideUSS_RC "Rolling Counter [0 - 15]";
CM_ SG_ 894 MAS_SideUSS_CS "Checksum CRC8 SAE J1850 of the data field this message";
CM_ SG_ 893 MAS_Sensor9_Distance_Val "Value of the signal corresponds to the distance in cm from the sensor to the obstacle";
CM_ SG_ 893 MAS_Sensor8_Distance_Val "Value of the signal corresponds to the distance in cm from the sensor to the obstacle";
CM_ SG_ 893 MAS_Sensor11_Distance_Val "Value of the signal corresponds to the distance in cm from the sensor to the obstacle";
CM_ SG_ 893 MAS_Sensor10_Distance_Val "Value of the signal corresponds to the distance in cm from the sensor to the obstacle";
CM_ SG_ 893 MAS_RearUSS_RC "Rolling Counter [0 - 15]";
CM_ SG_ 893 MAS_RearUSS_CS "Checksum CRC8 SAE J1850 of the data field this message";
CM_ SG_ 891 MAS_Sensor5_Distance_Val "Value of the signal corresponds to the distance in cm from the sensor to the obstacle";
CM_ SG_ 891 MAS_Sensor4_Distance_Val "Value of the signal corresponds to the distance in cm from the sensor to the obstacle";
CM_ SG_ 891 MAS_Sensor3_Distance_Val "Value of the signal corresponds to the distance in cm from the sensor to the obstacle";
CM_ SG_ 891 MAS_Sensor2_Distance_Val "Value of the signal corresponds to the distance in cm from the sensor to the obstacle";
CM_ SG_ 891 MAS_FrontUSS_RC "Rolling Counter [0 - 15]";
CM_ SG_ 891 MAS_FrontUSS_CS "Checksum CRC8 SAE J1850 of the data field this message";
CM_ BO_ 567 "Cycle time should be changed from 100 ms to 20 ms if moving of sound adjastment roller detected.
in order to adjust the MMC volume more smoothly";
CM_ SG_ 567 SWM_ContrlsState_Old_RC "Rolling Counter [0 - 15]";
CM_ SG_ 567 SWM_DC_WheelPosition_Stat "Dash Board Computer thumbwheel : endless wheel value.
0x3F - Failure";
CM_ SG_ 567 SWM_ContrlsState_Old_CS "Checksum XOR8 of the data field this message
Checksum computed as per XOR algorithm:
Byte 1 XOR byte 2 .... XOR byte n-1. (n = packet length.)";
CM_ SG_ 567 SWM_MMSPrevBtn_Stat "Previous button media file";
CM_ SG_ 567 SWM_DC_WheelButton_Stat "Dash Board Computer thumbwheel : can be pressed and released once the position is suiting to the driver
$0 = Reserved
$1 = Released
$2 = Pressed
$3 = Failure";
CM_ SG_ 567 SWM_TELBtn_Stat "Incoming call answer button";
CM_ SG_ 567 SWM_ECULED_Stat "Exclusive use for EOL: indicates the status of the SW heater";
CM_ SG_ 567 SWM_ACC_SpeedIncrease_Stat "Adaptive cruise control speed increase button";
CM_ SG_ 567 SWM_ACCDistanceChange_Stat "Button for changing the distance of adaptive cruise control";
CM_ SG_ 567 SWM_UpshiftPaddle_Stat "Indicates a driver request for changing up a gear via the steering wheel paddle:
0x0 = Reserved
0x1 = Released
0x2 = Pressed
0x3 = Failure";
CM_ SG_ 567 SWM_ACCactivate_Stat "Adaptive cruise control activation button";
CM_ SG_ 567 SWM_MMSNextBtn_Stat "Button to switch next media file";
CM_ SG_ 567 SWM_ACCSpeedDecrease_Stat "Adaptive cruise control distance activation button";
CM_ SG_ 567 SWM_DownshiftPaddle_Stat "Indicates a driver request for changing down a gear via the steering wheel paddle:
0x0 = Reserved
0x1 = Released
0x2 = Pressed
0x3 = Failure";
CM_ SG_ 567 SWM_VOLWheelBtn_Stat "Volume control wheel";
CM_ SG_ 567 SWM_VCBtn_Stat "Voice control activation button or call reset";
CM_ SG_ 567 SWM_VOLWheelPosition_Stat "0x3F - Failure";
CM_ BO_ 1902 "Diagnostic Message";
CM_ SG_ 1902 Diag_To_RLR "Diagnostic signal";
CM_ BO_ 1901 "Diagnostic Message";
CM_ SG_ 1901 Diag_To_RLL "Diagnostic signal";
CM_ BO_ 1894 "Diagnostic Message";
CM_ SG_ 1894 Diag_To_TLR "Diagnostic signal";
CM_ BO_ 1893 "Diagnostic Message";
CM_ SG_ 1893 Diag_To_TLL "Diagnostic signal";
CM_ BO_ 1900 "Diagnostic Message";
CM_ SG_ 1900 Diag_To_mLEDR "Diagnostic signal";
CM_ BO_ 1915 "Diagnostic Message";
CM_ SG_ 1915 Diag_To_HLR "Diagnostic signal";
CM_ BO_ 1898 "Diagnostic Message";
CM_ SG_ 1898 Diag_To_mLEDL "Diagnostic signal";
CM_ BO_ 1897 "Diagnostic Message";
CM_ SG_ 1897 Diag_To_HLL "Diagnostic signal";
CM_ BO_ 1910 "Diagnostic Message";
CM_ SG_ 1910 Diag_From_TLR "Diagnostic signal";
CM_ BO_ 1909 "Diagnostic Message";
CM_ SG_ 1909 Diag_From_TLL "Diagnostic signal";
CM_ BO_ 1918 "Diagnostic Message";
CM_ SG_ 1918 Diag_From_RLR "Diagnostic signal";
CM_ BO_ 1917 "Diagnostic Message";
CM_ SG_ 1917 Diag_From_RLL "Diagnostic signal";
CM_ BO_ 1916 "Diagnostic Message";
CM_ SG_ 1916 Diag_From_mLEDR "Diagnostic signal";
CM_ BO_ 1899 "Diagnostic Message";
CM_ SG_ 1899 Diag_From_HLR "Diagnostic signal";
CM_ BO_ 1914 "Diagnostic Message";
CM_ SG_ 1914 Diag_From_mLEDL "Diagnostic signal";
CM_ BO_ 1913 "Diagnostic Message";
CM_ SG_ 1913 Diag_From_HLL "Diagnostic signal";
CM_ SG_ 387 VCU_DriverDmdTrq_Val "Driver demand overall torque WITHOUT interventions from ESC, CC, Speed limiter";
CM_ SG_ 387 VCU_DriverDmdTrqInt_Val "Driver demand overall torque WITH interventions from ESC, CC, Speed limiter";
CM_ SG_ 387 VCU_DriverDmd_RC "Rolling Counter [0 - 15]";
CM_ SG_ 387 VCU_DriverDmd_CS "Checksum CRC8 SAE J1850 of the data field this message";
CM_ SG_ 724 VCU_MaxAlowTrq_Val "Maximum alowable requested overall torque ";
CM_ SG_ 724 VCU_ExtTrqSource_Stat "VCU external torque implementation status";
CM_ SG_ 724 VCU_MinAlowTrq_Val "Minimum alowable requested overall torque ";
CM_ SG_ 724 VCU_ADAS_01_RC "Rolling Counter [0 - 15]";
CM_ SG_ 724 VCU_ADAS_01_CS "Checksum CRC8 SAE J1850 of the data field this message";
CM_ SG_ 933 EMS_MinCurrentStaty "Limit of electric current in generator mode, quasi stationary limit";
CM_ SG_ 933 EMS_MaxCurrentStaty "Limit of electric current in motor mode, quasi stationary limit";
CM_ SG_ 933 EMS_MaxTorque "Max allowed torque";
CM_ SG_ 933 EMS_04_CS "Checksum XOR8 of the data field this message
Checksum computed as per XOR algorithm:
Byte 1 XOR byte 2 .... XOR byte n-1. (n = packet length.)";
CM_ SG_ 933 EMS_04_RC "Rolling Counter [0 - 15]";
CM_ SG_ 933 EMS_MinTorque "Min allowed torque";
CM_ SG_ 141 EMS_03_RC "Rolling Counter [0 - 15]";
CM_ SG_ 141 EMS_DesEMotorTorque "Desired e-motor torque";
CM_ SG_ 141 EMS_03_CS "Checksum XOR8 of the data field this message
Checksum computed as per XOR algorithm:
Byte 1 XOR byte 2 .... XOR byte n-1. (n = packet length.)";
CM_ SG_ 141 EMS_DesInvMode "Desired inverter mode";
CM_ SG_ 593 DownwardPosReq "request lowering the position (stepwise)";
CM_ SG_ 593 DrivingMode_Sig "This signal provide information about selected driving mode";
CM_ SG_ 593 DMS_ServiceMode "Service Mode requested by the driver:
$0 = Service Mode Not Requested
$1 = Service Mode Requested";
CM_ SG_ 593 DMS_HDC_Req "Hill Descent Assist function requested by the driver:
$0 = HDC Not Requested
$1 = HDC Requested";
CM_ SG_ 593 BCM_DMS_01_RC "Rolling Counter [0 - 15]";
CM_ SG_ 593 BCM_DMS_01_CS "Checksum XOR8 of the data field this message
Checksum computed as per XOR algorithm:
Byte 1 XOR byte 2 .... XOR byte n-1. (n = packet length.)";
CM_ SG_ 593 UpwardPosReq "Request heightening the position (stepwise)";
CM_ SG_ 242 SCU_RightFrHeight "Right Front height (physical count value for height sensor pulse width)
The range of the pulse width count value is 40-254.
40 is min pulse width reflecting the lowest limitation of wheel rebound.
254 is max pulse width reflecting the highest limitatio";
CM_ SG_ 242 SCU_LeftRearHeight "Left Rear height (physical count value for height sensor pulse width)
The range of the pulse width count value is 40-254.
40 is min pulse width reflecting the lowest limitation of wheel rebound.
254 is max pulse width reflecting the highest limitation";
CM_ SG_ 242 SCU_RightRearHeight "Right Rear height (physical count value for height sensor pulse width)
The range of the pulse width count value is 40-254.
40 is min pulse width reflecting the lowest limitation of wheel rebound.
254 is max pulse width reflecting the highest limitation";
CM_ SG_ 242 SCU_LeftFrHeight "Left Front height (physical count value for height sensor pulse width)
The range of the pulse width count value is 40-254.
40 is min pulse width reflecting the lowest limitation of wheel rebound.
254 is max pulse width reflecting the highest limitation";
CM_ SG_ 242 SCU_02_CS "Checksum XOR8 of the data field this message
Checksum computed as per XOR algorithm:
Byte 1 XOR byte 2 .... XOR byte n-1. (n = packet length.)";
CM_ SG_ 242 SCU_02_RC "Rolling Counter [0 - 15]";
CM_ SG_ 305 ESC_Reserve2 "Reserve Signal. Coded with 00h";
CM_ SG_ 305 ESC_NotSupported "Not supported. Coded with FFFFh";
CM_ SG_ 305 ESC_HardCoded "Hard coded with xx01 = sensor not available as PSIPP parameter not supported";
CM_ SG_ 305 ESC_AX_Stat "Qualifier for longitudinal acceleration export signal
xx00 Signal in specification
xx01 Sensor not available
xx10 Signal failure
xx11 Reserved
x0xx Initialization finished
x1xx Initialization running
0xxx Reserved
1xxx Reserved";
CM_ SG_ 305 ESC_YRS_02_CS "Checksum CRC8 SAE J1850 of the data field this message";
CM_ SG_ 305 ESC_YRS_02_RC "Rolling Counter [0 - 15]";
CM_ SG_ 305 ESC_Reserve3 "Reserve. Coded 00h";
CM_ SG_ 305 ESC_AX "Longitudinal acceleration signal routed by ESC ";
CM_ SG_ 277 EMS_MMotActLm "Minimum available static propulsion torque. 
The information must consider at least all torque losses caused by engine friction and engine load such as those from generator or A/C compressor.
For better control performance especially at low speeds, min";
CM_ SG_ 277 EMS_MMotMax "Maximum available static propulsion torque.
Gives the maximum possible engine torque under the current operation constraints (engine speed, smoke limitation, ...)";
CM_ SG_ 277 EMS_16_RC "Rolling Counter [0 - 15]";
CM_ SG_ 277 EMS_16_CS "Checksum CRC8 SAE J1850 of the data field this message";
CM_ SG_ 902 mLEDR_LowBeam_Stat "State of Low Beam Light";
CM_ SG_ 902 mLEDR_Voltage_Stat "State of mLEDR Voltage";
CM_ SG_ 902 mLEDR_SteeringAngActual_Val "Actual Value of Dynamic Bendung Light Function";
CM_ SG_ 902 mLEDR_HighBeam_Stat "State of High Beam Light";
CM_ SG_ 902 mLEDR_Temp_Val "Temperature of mLEDR";
CM_ SG_ 902 mLEDR_FaultCount_Val "State of mLEDR Voltage";
CM_ SG_ 901 mLEDL_HighBeam_Stat "State of High Beam Light";
CM_ SG_ 901 mLEDL_SteeringAngActual_Val "Actual Value of Dynamic Bendung Light Function";
CM_ SG_ 901 mLEDL_LowBeam_Stat "State of Low Beam LightState of Low Beam Light";
CM_ SG_ 901 mLEDL_Voltage_Stat "State of mLEDL Voltage";
CM_ SG_ 901 mLEDL_Temp_Val "Temperature of mLEDL";
CM_ SG_ 901 mLEDL_FaultCount_Val "State of mLEDL";
CM_ BO_ 583 "The DLC and Layout must be as in UMP_1 because PTG is receive this message ";
CM_ SG_ 583 TM_CoolingBox_Stat "Cooling box temperature status";
CM_ SG_ 583 TM_T30spec_Stat "Terminal T30 from additional battery";
CM_ SG_ 583 TM_FuelLidOpen_Req "Fuel lid unlock request for PHEV vehicles";
CM_ SG_ 583 TM_TrunkLatch_Stat "Indicates the trunk latch position";
CM_ SG_ 583 TM_LicensePlateLight_State "State of license plate lights";
CM_ SG_ 583 TM_TrailerConnect_Stat "Trailer connect status signal
Indicates wether the trailer is connected or not";
CM_ SG_ 583 TM_LockAndCloseSW_Req "State of interior trunk lid close an lock swich";
CM_ SG_ 583 TM_Comm_Req "Request to initiate/ maintain communication activity from TM";
CM_ SG_ 583 TM_BrakeLightHM_Status "Current status of brake lights";
CM_ SG_ 583 TM_RearWindowHeating_Stat "State of rear window heating";
CM_ SG_ 583 TM_WarningInd "Request a warning message to be displayed on IC:
$0 = No Warning
$1 = Warning requested";
CM_ SG_ 583 TM_RearCushion_State "The state of rear window cushion";
CM_ SG_ 583 TM_FuelLid_Stat "Fuel lid open status";
CM_ SG_ 583 TM_ExtTrunkSW_Req "Exterior switch on the trunk used to open the trunk:
0x0 = No Request
0x1 = Unlock request";
CM_ SG_ 583 TM_IntTrunkSW_Req "State of interior trunk lid close swich";
CM_ SG_ 583 TM_Kick_Req "Request to open or close trunk lid from kick sensor";
CM_ SG_ 900 TLR_Voltage_Stat "State of TLR Voltage";
CM_ SG_ 900 TLR_Temp_Val "Temperature of TLR";
CM_ SG_ 900 TLR_ReverseLgt_Stat "State of Reverse Light";
CM_ SG_ 900 TLR_TurnInd_Stat "State of Direcrion Indicator";
CM_ SG_ 900 TLR_PositionLgt_Stat "State of Position Light";
CM_ SG_ 900 TLR_BrakeLgt_Stat "State of Brake Light";
CM_ SG_ 900 TLR_RearFogLgt_Stat "State of Rear Fog Light";
CM_ SG_ 899 TLL_Temp_Val "Temperature of TLL";
CM_ SG_ 899 TLL_Voltage_Stat "State of TLL Voltage";
CM_ SG_ 899 TLL_BrakeLgt_Stat "State of Brake Light";
CM_ SG_ 899 TLL_TurnInd_Stat "State of Direcrion Indicator";
CM_ SG_ 899 TLL_ReverseLgt_Stat "State of Reverse Light";
CM_ SG_ 899 TLL_PositionLgt_Stat "State of Position Light";
CM_ SG_ 899 TLL_RearFogLgt_Stat "State of Rear Fog Light";
CM_ SG_ 177 ratEng2GbxTorqueRatio "Engine to gearbox out torque ratio (without differential)";
CM_ SG_ 177 TCU_VehicleSpeed_ValueError "Indicates if the signal vehicleSpeed has valid value";
CM_ SG_ 177 stGbxMILReq "TCU MIL lamp";
CM_ SG_ 177 TCU_DriverBrakeReq "Indicates a request to the user for pressing the brake pedal:
$0 = No request
$1 = Brake pedal requested";
CM_ SG_ 177 stGearLvr "Signal gear lever (PRND) position for HEV";
CM_ SG_ 177 gearChangeSPDphase "Speed ratio changing stage of gearshift";
CM_ SG_ 177 numGearEngaged "Actual gear";
CM_ SG_ 177 stManualGbxMode "Manual gear shift mode";
CM_ SG_ 177 TCU_VehicleSpeed "calculated vehicle speed value";
CM_ SG_ 177 stTransmissionWarnings "TCU MIL lamp";
CM_ SG_ 177 numGearTarget "Gear target";
CM_ SG_ 177 TCU_R932_1_RC "Rolling Counter [0 - 15]";
CM_ SG_ 177 stGearboxMode "Gearbox mode, Driving mode settings in TCU";
CM_ SG_ 177 TCU_R932_1_CS "Checksum XOR8 of the data field this message
Checksum computed as per XOR algorithm:
Byte 1 XOR byte 2 .... XOR byte n-1. (n = packet length.)";
CM_ SG_ 177 bShiftInProgress "Shift is in progress";
CM_ SG_ 568 SWM_ContrlsState_CS "Checksum XOR8 of the data field this message
Checksum computed as per XOR algorithm:
Byte 1 XOR byte 2 .... XOR byte n-1. (n = packet length.)";
CM_ SG_ 568 SWM_ContrlsState_RC "Rolling Counter [0 - 15]";
CM_ SG_ 568 SWM_VolumeMute_Req "Mute active";
CM_ SG_ 568 SWM_VolumeDownBtn_Req "Volume down";
CM_ SG_ 568 SWM_VolumeUpBtn_Req "Volume up";
CM_ SG_ 568 SWM_VoiceCntrl_Req "Call Voice control ";
CM_ SG_ 568 SWM_MMCPrevBtn_Req "MMC control";
CM_ SG_ 568 SWM_MMCNextBtn_Req "MMC control";
CM_ SG_ 568 SWM_MODE_Req "Press change mode ACC or CC or LIM";
CM_ SG_ 568 SWM_CNCL_Req "Press activate/switch on stand by  mode (ACC/CC/LIM)";
CM_ SG_ 568 SWM_DIS_Req "Distance button pressed";
CM_ SG_ 568 SWM_RES_Req "Press switch off/switch on stand by mode (ACC/CC/LIM)";
CM_ SG_ 568 SWM_UserFunc_Req "User's choosen MMC function switch";
CM_ SG_ 568 SWM_ACCSpeedDecrease_Req "Decrease ACC/CC/LIM speed value";
CM_ SG_ 568 SWM_ACCSpeedIncrease_Req "Increase ACC/CC/LIM speed value";
CM_ SG_ 568 SWM_SETSpeed_Req "Set vehicle speed ACC/CC/LIM";
CM_ SG_ 568 SWM_TELBtn_Req "Telephone function turn on or answer incoming call";
CM_ SG_ 568 SWM_Home_Req "Call IC's main menu";
CM_ SG_ 568 SWM_Back_Req "Go back IC's menu";
CM_ SG_ 568 SWM_ICNextBtn_Req "Show next IC's menu";
CM_ SG_ 568 SWM_ICPrevBtn_Req "Show previous IC's menu";
CM_ SG_ 568 SWM_ICUpBtn_Req "Move up in selected menu";
CM_ SG_ 568 SWM_ICDownBtn_Req "Move down in selected menu";
CM_ SG_ 568 SWM_ICConfBtn_Req "Activate selected menu";
CM_ SG_ 568 SWM_UpshiftPaddle_Req "Indicates a driver request for changing up a gear via the steering wheel paddle:
0x0 = Reserved
0x1 = Released
0x2 = Pressed
0x3 = Failure";
CM_ SG_ 568 SWM_DownshiftPaddle_Req "Indicates a driver request for changing down a gear via the steering wheel paddle:
0x0 = Reserved
0x1 = Released
0x2 = Pressed
0x3 = Failure";
CM_ SG_ 568 SWM_PosHand_Stat "Hand position on steering wheel status signal";
CM_ SG_ 688 SAS_Standard_RC "Rolling Counter [0 - 15]";
CM_ SG_ 688 SAS_Standard_CS "Checksum XOR4 of the data field this message";
CM_ SG_ 688 SAS_CAL_Stat "Calibration status";
CM_ SG_ 688 SAS_TRIM_Stat "Indicates trimming status of sensor done at development plants. Used only for development/ internal purposes at Bosch";
CM_ SG_ 688 SAS_Angle "Steering wheel angle. Signal outputs fault value if sensor is not calibrated or sensor has detected internal failure";
CM_ SG_ 688 SAS_OK_Stat "Failure status.";
CM_ SG_ 688 SAS_SF1_5_Stat "Internal status flags SF1 up to SF5. Only for internal use at Bosch";
CM_ SG_ 688 SAS_Speed "Steering Wheel rotation speed. Outputs fault value if sensor has detected internal failure.";
CM_ SG_ 904 RLR_PositionLgt_Stat "State of Position Light";
CM_ SG_ 904 RLR_ReverseLgt_Stat "State of Reverse Light";
CM_ SG_ 904 RLR_Temp_Val "Temperature of RLR";
CM_ SG_ 904 RLR_BrakeLgt_Stat "State of Brake Light";
CM_ SG_ 904 RLR_TurnInd_Stat "State of Direcrion Indicator";
CM_ SG_ 904 RLR_Voltage_Stat "State of RLR Voltage";
CM_ SG_ 904 RLR_RearFogLgt_Stat "State of Rear Fog Light";
CM_ SG_ 903 RLL_BrakeLgt_Stat "State of Brake Light";
CM_ SG_ 903 RLL_Temp_Val "Temperature of RLL";
CM_ SG_ 903 RLL_PositionLgt_Stat "State of Position Light";
CM_ SG_ 903 RLL_ReverseLgt_Stat "State of Reverse Light";
CM_ SG_ 903 RLL_TurnInd_Stat "State of Direcrion Indicator";
CM_ SG_ 903 RLL_RearFogLgt_Stat "State of Rear Fog Light";
CM_ SG_ 903 RLL_Voltage_Stat "State of RLL Voltage";
CM_ SG_ 976 MAS_ParkingOutSuccess_Stat "Successful execution status of Parking Out";
CM_ SG_ 976 MAS_ParkingOutAvailable_Stat "Avaluablity of automatic parking out";
CM_ SG_ 976 MAS_APAMode_Stat "Current APA mode";
CM_ SG_ 976 MAS_APAManeuverSuccess_Stat "0x0 (APA did not execute a parking maneuver successfully OR the parking maneuver was not started) 0x1 (APA executed a parking maneuver successfully)";
CM_ SG_ 976 MAS_AVMUltrasonicSide_Stat "The FIU must show the user that the information from the side parking sensors cannot be trusted.";
CM_ SG_ 976 MAS_Status_RC "Rolling Counter [0 - 15]";
CM_ SG_ 976 MAS_Status_CS "Checksum CRC8 SAE J1850 of the data field this message";
CM_ SG_ 976 MAS_AVMUltrasonicRear_Stat "The FIU must show the user that the information from the front parking sensors cannot be trusted.";
CM_ SG_ 976 MAS_AVMUltrasonicFront_Stat "The FIU must show the user that the information from the front parking sensors cannot be trusted.";
CM_ SG_ 976 MAS_AVMCameraRightSide_Stat "FIU should show information that the camera is not available.";
CM_ SG_ 976 MAS_AVMCameraLeftSide_Stat "FIU should show information that the camera is not available.";
CM_ SG_ 976 MAS_AVMCameraRear_Stat "FIU should show information that the camera is not available.";
CM_ SG_ 976 MAS_AVMCameraFront_Stat "FIU should show information that the camera is not available.";
CM_ SG_ 976 MAS_AVMUltraSonic_Stat "0 -MAS is not activated by parking sensors, does not show the distance to objects, and does not transmit sound to the DSP.";
CM_ SG_ 976 MAS_AVMNarrowMode_Stat "0 - AVM is not in 2D mode
1 - AVM is in wide mode, i.e. shows only the image from the camera in 2D View
2 - AVM shows the image from the camera + Top view";
CM_ SG_ 976 MAS_AVMAutoAct_Stat "Automatic activation set less than 15 km/h";
CM_ SG_ 976 MAS_MASmode_Stat "Current mode
0x0 - MAS func (AVM, APA) not active
0x1- MAS in AVM mode (Souround view + USS)
0x2 - MAS in APA mode (Autopark/Remote autopark)
0x3 - MAS resp on req from FIU or BCM with vehspeed >15 km/h (active for 3 frames)
0x4 - MAS system in Error";
CM_ SG_ 976 MAS_View_Stat "On this signal, FIU will understand which view mode to make active";
CM_ SG_ 320 DAS_LeftLaneLDWWarning_Req "Left Side of the Lane Departure Warning";
CM_ SG_ 320 DAS_RightLaneLDWWarning_Req "Right Side of the Lane Departure Warning";
CM_ SG_ 320 DAS_SPLimRoadSignInf1_Stat "Current road sign Information list 1 (Road sign to be displayed)";
CM_ SG_ 320 DAS_SPLimRoadSignInf2_Stat "Current road sign Information list 2 (Road sign to be displayed)";
CM_ SG_ 320 DAS_SPLimRoadSignInf3_Stat "Current road sign Information list 3 (Road sign to be displayed)";
CM_ SG_ 320 DAS_RoadSignAddressing_Stat "Multiplexor addresing the corresponding road sign Information list";
CM_ SG_ 320 DAS_SPLimRoadSignCurrSpeed_Stat "Indicates the current speed limitation as per to Road Sign Recognition";
CM_ SG_ 320 DAS_RoadLaneAddressing_Stat "Multiplexor addresing the corresponding road side";
CM_ SG_ 777 DAS_ACCSetDistance_Stat "Current set distance to vehicle in front for ACC function
";
CM_ SG_ 777 DAS_ACCResDistance_Stat "Resume ACC function=>  set distance to heading vehicle";
CM_ SG_ 777 DAS_ACCSetSpeed_Val "Current set speed in ACC function";
CM_ SG_ 777 DAS_ACCResSpeed_Val "Resume ACC function=> set speed";
CM_ SG_ 777 DAS_ACCtargetDetected_Stat "ACC detection status:
";
CM_ SG_ 746 IC_RSRFuncEnable "Request or not Road Signs Recognation function:
$0 = Disable
$1 = Enable";
CM_ SG_ 746 IC_LDWFuncEnable "Request or not Lane Departure Warning function
$0 = Disable
$1 = Enable";
CM_ SG_ 746 IC_VisualAct_Req "Request to activate Visual";
CM_ SG_ 746 IC_NvAct_Req "Request to activate Night Vision";
CM_ SG_ 746 IC_DistBar_Stat "Visibility of distance settings bar";
CM_ SG_ 304 ESC_Reserve1 "Reserve Signal. Coded with 0000h";
CM_ SG_ 304 ESC_CLU_Stat "Sensor cluster status signal routed through ESP
xx00 Reserved
xx01 Reserved
xx10 Reserved
xx11 Reserved
x0xx No sync underflow detected
x1xx Sync underflow detected
0xxx No sync failure detected
1xxx Sync failure detected";
CM_ SG_ 304 ESC_AY_Stat "Qualifier for lateral acceleration export signal
xx00 Signal in specification
xx01 Sensor not available
xx10 Signal failure
xx11 Reserved
x0xx Initialization finished
x1xx Initialization running
0xxx Reserved
1xxx Reserved";
CM_ SG_ 304 ESC_YRS_01_CS "Checksum CRC8 SAE J1850 of the data field this message";
CM_ SG_ 304 ESC_YRS_01_RC "Rolling Counter [0 - 15]";
CM_ SG_ 304 ESC_PSIP1_Stat "Qualifier for yaw rate export signal
xx00 Signal in specification
xx01 Sensor not available
xx10 Signal failure
xx11 Reserved
x0xx Initialization finished
x1xx Initialization running
0xxx Reserved
1xxx Reserved";
CM_ SG_ 304 ESC_PSIP1_Val "Yaw rate signal routed through ESP. Signal limited by SW to +/-100 degree per sec";
CM_ SG_ 304 ESC_AY_Val "Lateral Acceleration signal routed through ESP. Signal limited by SW to -/+1.8 g";
CM_ SG_ 275 ESC_10_RC "Rolling Counter [0 - 15]";
CM_ SG_ 275 CddTempOff "Indicates cdd switched off due to brake temperature 
$0 = CDD OFF due to Brake Temperature";
CM_ SG_ 275 AbpActive "Indicates APB (automatic brake prefill) is active
$0 = APB inactive
$1 = APB active";
CM_ SG_ 275 AebAvailable "Indicates AEB control availability
$0 = Not Available
$1 = Available";
CM_ SG_ 275 CddAvailable "Indicates CDD control available
$0 = Not Available
$1 = Available";
CM_ SG_ 275 CddSkiddingDetected "Indicates CDD skidding 
$0 = No Skidding
$1 = Skidding Detected";
CM_ SG_ 275 CddVehicleStandstill "Vehicle hold actively on standstill by CDD
$0 = Standstill by CDD OFF
$1 = Standstill by CDD ON";
CM_ SG_ 275 CddFailure "Indicates CDD has detected a failure
$0 = No Failure
$1 = Failure";
CM_ SG_ 275 CddActive "Indicates cdd control active (Controlled Deceleration for Driver Assistant Systems)
$0 = Inactive
$1 = Active";
CM_ SG_ 275 AbpAvailable "Indicates ABP control availability
$0 = Not Available
$1 = Available";
CM_ SG_ 275 BrakeJerkApplied "Indicates to CDA whether Brake jerk is applied:
$0 = Brake Jerk Not Applied
$1 = Brake Jerk Applied";
CM_ SG_ 275 ESC_10_CS "Checksum CRC8 SAE J1850 of the data field this message";
CM_ SG_ 274 ESC_VacuumPressure_Val "Vacuum pressure information in brake booster front chamber";
CM_ SG_ 274 ESC_BrakePressureMC_Val "Brake pressure (estimated/measured) in the master cylinder
0xFFF = Error";
CM_ SG_ 274 ESC_VacuumSignalReserved "Reserved signal for future extension. E.g. vacuum sensor status";
CM_ SG_ 274 ESC_09_CS "Checksum CRC8 SAE J1850 of the data field this message";
CM_ SG_ 274 ESC_09_RC "Rolling Counter [0 - 15]";
CM_ SG_ 273 ESC_pWheelRR_Val "Estimated brake pressure at rear right wheel
0x7FFF = fault value";
CM_ SG_ 273 ESC_pWheelRL_Val "Estimated brake pressure at rear left wheel
0x7FFF = fault value";
CM_ SG_ 273 ESC_07_CS "Checksum CRC8 SAE J1850 of the data field this message";
CM_ SG_ 273 ESC_07_RC "Rolling Counter [0 - 15]";
CM_ SG_ 272 ESC_ATCTrqRq_Val "Desired torque for transfer case
0xFFFF = Error";
CM_ SG_ 272 ESC_ATCMode_Req "Indicates the torque request mode for transfer case
$0 = No Intervention
$1 = Limit Minimum
$2 = Limit Maximum
$3 = Fast Open Request
$7 = Error

IF ATC_ModeReq == Limit_minimum OR Limit_maximum THEN the ATC_TrqRq needs to be sent with a value";
CM_ SG_ 272 ESC_pWheelFR_Val "Estimated brake pressure at front right wheel
0x7FFF = fault value";
CM_ SG_ 272 ESC_06_RC "Rolling Counter [0 - 15]";
CM_ SG_ 272 ESC_06_CS "Checksum CRC8 SAE J1850 of the data field this message";
CM_ SG_ 272 ESC_pWheelFL_Val "Estimated brake pressure at front left wheel
0x7FFF = fault value";
CM_ SG_ 164 EMS_bPowertrainSignalSpdErr "ERR_N_ENG Error - powertrain speed signal";
CM_ SG_ 164 EMS_nICEngineSpeed1 "Internal combustion engine: Engine speed ";
CM_ SG_ 164 EMS_bICEngineFCO "FCO_STAT: Engine in fuel cut off  ";
CM_ SG_ 164 EMS_4_CS "Checksum XOR8 of the data field this message
Checksum computed as per XOR algorithm:
Byte 1 XOR byte 2 .... XOR byte n-1. (n = packet length.)";
CM_ SG_ 164 EMS_4_RC "Rolling Counter [0 - 15]";
CM_ SG_ 164 EMS_nPwrTrnSpd "Powertrain speed";
CM_ SG_ 163 EMS_bAccPedSensorFail "Throttle pedal sensor failed";
CM_ SG_ 163 EMS_3_RC "Rolling Counter [0 - 15]";
CM_ SG_ 163 EMS_nIdleSpdTargetAct "Actual target idle speed";
CM_ SG_ 163 EMS_ratAccPed_Val "Acceleration pedal position";
CM_ SG_ 163 EMS_3_CS "Checksum XOR8 of the data field this message
Checksum computed as per XOR algorithm:
Byte 1 XOR byte 2 .... XOR byte n-1. (n = packet length.)";
CM_ SG_ 163 EMS_stKickDown "Kick Down";
CM_ SG_ 163 EMS_ratAccPed_Stat "Error flag for Acceleration pedal position signal (ratAccPed ):
$0 = No Fault
$1 = Fault";
CM_ SG_ 163 EMS_bPwrTrnTorqueEstErr "Error torque calculation";
CM_ SG_ 1292 IC_Speed "vehicle speed value calculated by IC";
CM_ SG_ 1293 IC_DMS_Calibration_Stat "DMS calibration status";
CM_ SG_ 1293 IC_EyeClosed_Stat "Condition of the eyes Open or Closed";
CM_ SG_ 1293 IC_FaceRecognition_Stat "Face recognition status";
CM_ SG_ 1293 IC_GazeOther_Stat "Gaze on other status";
CM_ SG_ 1293 IC_LvlFatigues_Stat "Status of fatigues";
CM_ SG_ 1293 IC_DataReliability_Stat "Reliability of data status";
CM_ SG_ 1293 IC_LvlDistractions_Stat "Status of distractions level";
CM_ SG_ 1293 IC_GazeFront_Stat "Gaze on Front status";
CM_ SG_ 1293 IC_GazeleftSide_Stat "Gaze on left side status";
CM_ SG_ 1293 IC_ViewRoadSide_Stat "View road side status";
CM_ SG_ 1293 IC_GazeRightSide_Stat "Gaze on right side status";
CM_ SG_ 743 IC_AbsoluteDateAndTime "Absolute time initiated at the assembly line moment.
UNIX Clock date and time information.
Epoch time = year zero => UNIX Clock = 0 => 1 January 1970
The Unix time number is zero at the Unix epoch, and increases by exactly 86400 per day since the epoch";
CM_ SG_ 743 IC_ABSOLUTE_CLOCK_RC "Rolling Counter [0 - 15]";
CM_ SG_ 743 IC_ABSOLUTE_CLOCK_CS "Checksum CRC8 SAE J1850 of the data field this message";
CM_ SG_ 898 HLR_DayRunningLgt_Stat "State of DayTime Running Light";
CM_ SG_ 898 HLR_Temp_Val "Temperature of HLR";
CM_ SG_ 898 HLR_CorrectorActual_Val "Actual Value of Headlight Corrector";
CM_ SG_ 898 HLR_HighBeam_Stat "State of High Beam Light";
CM_ SG_ 898 HLR_Voltage_Stat "State of HLR Voltage";
CM_ SG_ 898 HLR_RightCorneringLgt_Stat "State of Rightt Cornering Light";
CM_ SG_ 898 HLR_TurnIndRight_Stat "State of Right Direcrion Indicator";
CM_ SG_ 898 HLR_LowBeam_Stat "State of Low Beam Light";
CM_ SG_ 898 HLR_PositionLgt_Stat "State of Position Light";
CM_ SG_ 897 HLL_LowBeam_Stat "State of Low Beam Light";
CM_ SG_ 897 HLL_DayRunningLgt_Stat "State of DayTime Running Light";
CM_ SG_ 897 HLL_CorrectorActual_Val "Actual Value of Headlight Corrector";
CM_ SG_ 897 HLL_Temp_Val "Temperature of HLL";
CM_ SG_ 897 HLL_Voltage_Stat "State of HLL Voltage";
CM_ SG_ 897 HLL_TurnIndLeft_Stat "State of Left Direcrion Indicator";
CM_ SG_ 897 HLL_PositionLgt_Stat "State of Position Light";
CM_ SG_ 897 HLL_HighBeam_Stat "State of High Beam Light";
CM_ SG_ 897 HLL_LeftCorneringLgt_Stat "State of Left Cornering Light";
CM_ SG_ 1428 FIU_FR_Synx_Req "SYNX mode command";
CM_ SG_ 1428 FIU_FL_Synx_Req "SYNX mode command";
CM_ SG_ 1428 FIU_ReduceChrgCurr_Stat "On/OFF Reduce charging current function";
CM_ SG_ 1428 FIU_SchedWed_Stat "Repeat function in Wednesday";
CM_ SG_ 1428 FIU_SchedTue_Stat "Repeat function in Tuesday";
CM_ SG_ 1428 FIU_SchedThu_Stat "Repeat function in Thursday";
CM_ SG_ 1428 FIU_SchedSu_Stat "Repeat function in Sunday";
CM_ SG_ 1428 FIU_SchedStart_Stat "Activate/Deactivate charging start timer ";
CM_ SG_ 1428 FIU_SchedSat_Stat "Repeat function in Saturday";
CM_ SG_ 1428 FIU_SchedMon_Stat "Repeat function in Monday";
CM_ SG_ 1428 FIU_SchedFri_Stat "Repeat function in Friday";
CM_ SG_ 1428 FIU_SchedEnd_Stat "Activate/Deactivate charging end timer ";
CM_ SG_ 1428 FIU_Sched_StartTimeMinutes_Val "Start charging time (Minutes)";
CM_ SG_ 1428 FIU_Sched_StartTimeHours_Val "Start charging time (Hours)";
CM_ SG_ 1428 FIU_Sched_EndTimeMinutes_Val "End charging time (Minutes)";
CM_ SG_ 1428 FIU_Sched_EndTimeHours_Val "End charging time (Hours)";
CM_ SG_ 1428 FIU_PrepearClim_Stat "Activate/Deactivate Pre-conditional climate at end ";
CM_ SG_ 1428 FIU_DischrgLim_Val "Set battery discharging limit";
CM_ SG_ 1428 FIU_ProjectionLiveObj_Req "Projection of recognized live objects enable request";
CM_ SG_ 1428 FIU_ProjectionNavigation_Req "Projection of navigatoon system enable request";
CM_ SG_ 1428 FIU_ProjectionRoadSigns_Req "Projection of road signs enable request";
CM_ SG_ 1428 FIU_ProjectionOnRoad_Req "Projection on a road enable request";
CM_ SG_ 1428 FIU_RR_Synx_Req "SYNX mode command";
CM_ SG_ 1428 FIU_RL_Synx_Req "SYNX mode command";
CM_ SG_ 1428 FIU_ChrgLim_Val "Set battery charging limit";
CM_ SG_ 1428 FIU_ICimage_Req "IC image changing request";
CM_ SG_ 1428 FIU_RearSideWindowsElcrome_Req "Request for dimming rear side windows";
CM_ SG_ 1428 FIU_ArmrestHeatFL_Req "Armrest heating request for front left zone";
CM_ SG_ 1428 FIU_ArmrestHeatRL_Req "Armrest heating request for rear left zone";
CM_ SG_ 1428 FIU_ArmrestHeatFR_Req "Armrest heating request for front right zone";
CM_ SG_ 1428 FIU_ArmrestHeatRR_Req "Armrest heating request for rear right zone";
CM_ SG_ 464 RSA_Torque_Val "Output torque of the electric motor";
CM_ SG_ 464 RSA_Status_RC "Rolling Counter [0 - 15]";
CM_ SG_ 464 RSA_Status_CS "Checksum CRC8 SAE J1850 of the data field this message";
CM_ SG_ 464 RSA_Fault_Stat "RSA Fault flag";
CM_ SG_ 464 RSA_ExternalControl_Stat "RSA external control status flag";
CM_ SG_ 464 RSA_Enable_Stat "Enable status of RSA";
CM_ SG_ 464 RSA_Angle_Val "Steering angle of the rear steering axle";
CM_ SG_ 1198 NMEA6_Sig "Navigation traffic NMEA (bytes 41 - 48)";
CM_ SG_ 1196 NMEA5_Sig "Navigation traffic NMEA (bytes 33 - 40)";
CM_ SG_ 1194 NMEA4_Sig "Navigation traffic NMEA (bytes 25 - 32)";
CM_ SG_ 1192 NMEA3_Sig "Navigation traffic NMEA (bytes 17 - 24)";
CM_ SG_ 1190 NMEA2_Sig "Navigation traffic NMEA (bytes 9 - 16)";
CM_ SG_ 1188 NMEA1_Sig "Navigation traffic NMEA (bytes 1 - 8)";
CM_ SG_ 1424 ERAG_Status "Indicates the ERAG status";
CM_ SG_ 1424 ERAG_FailureSts "Indicates the ERAG failures status:
Bitwise indication:
- bit position 0 set = Unavailable microphone
- bit position 1 set = Unavailable speaker
- bit position 2 set = No connection
- bit position 3 set = Reserved";
CM_ SG_ 1424 ERAG_MuteReq "Mute command
0x0 = Mute Inactive
0x1 = Mute Active";
CM_ SG_ 538 EPB_BrakeLight_Req "Brake light on request from EPB system";
CM_ SG_ 538 EPB_TargetDecel_Val "Decelartion requested from EPB when EPB switch is detected pressed and vehicle speed > 7km/h
This information will be taken into account by braking unit only if the EPB_DynamicEmergencyApply signal request is active.
ESC requests this signal to be certi";
CM_ SG_ 538 EPB_Status_RC "Rolling Counter [0 - 15]";
CM_ SG_ 538 EPB_AppliedForce_Stat "State of he force applied by tightening the cable.
$0 = No Force Applied
$1 = Low Force Applied
$2 = Medium Force Applied
$3 = Maximum Force Applied";
CM_ SG_ 538 EPB_Status_CS "Checksum CRC8 SAE J1850 of the data field this message";
CM_ SG_ 538 EPB_Failure_Stat "EPB failure status:
$0 = No failure
$1 = Failure";
CM_ SG_ 538 EPB_CurrParkBrake_Stat "EPB current status
$0 = Not Initialized
$1 = Released
$2 = Engaged
$3 = Release Under Progress
$4 = Engagement Under Progress
$5 = Reserved";
CM_ SG_ 538 EPB_CurrEPBSw_Stat "EPB switch current status
$0 = No Request
$1 = Release Brake
$2 = Lock Brake
$3 = Fault";
CM_ SG_ 538 EPB_AudibleChime_Req "Audible warning request";
CM_ SG_ 538 EPB_Indicator_Req "Feedback from EPB for indication Parking brake activation
Reserved = No action by ATS";
CM_ SG_ 538 EPB_DynamicEmergencyApply_Stat "Emergency braking from EPB button when speed > 7km/h:
$0= Not Enabled
$1= Enabled

ESC requests this signal to be certified ASIL C";
CM_ SG_ 582 DMRR_DoorCloseSw_Req "Request for power closing door from external switch on door panel";
CM_ SG_ 582 DMRR_DoorDirection_Stat "Direction of movement of the RR door";
CM_ SG_ 582 DMRR_ChildLock_Stat "Indicates the Child Lock status";
CM_ SG_ 582 DMRR_DoorMovement_Stat "RR door electric drive status";
CM_ SG_ 582 DMRR_RearCurtain_Req "Rear window blind control request from RR passenger";
CM_ SG_ 582 DMRR_IntDoorHandle_Req "State of RR door internal handle: engaged or not";
CM_ SG_ 582 DMRR_WarningInd "Request from DMRR to switch warning indicator in instrument cluster";
CM_ SG_ 582 DMRR_WindowFullyClosed_Stat "Completeness of window closing status";
CM_ SG_ 582 DMRR_Comm_Req "Request to wake up the car from the RR door";
CM_ SG_ 582 DMRR_ElcromeBright_Stat "RR door glass tinting status";
CM_ SG_ 582 DMRR_DoorLockState "RR Door Lock Status";
CM_ SG_ 582 DMRR_Multimedia_Req "Request to turn off/on the multimedia system from the RR passenger";
CM_ SG_ 582 DMRR_Antipinch_Stat "State of antipinch function of RR door";
CM_ SG_ 582 DMRR_RL_Window_Cmd "Request to control RL window from RR door";
CM_ SG_ 582 DMRR_IntDoorLockSw_Cmd "Interior door lock switch command";
CM_ SG_ 582 DMRR_SunShade_Stat "State of RR window sun shade";
CM_ SG_ 582 DMRR_DoorAjarState "RR door opening status";
CM_ SG_ 582 DMRR_DoorAjarFault_Stat "The fault status of ajar sensor in door lock";
CM_ SG_ 581 DMRL_DoorCloseSw_Req "Request for power closing door from external switch on door panel";
CM_ SG_ 581 DMRL_WindowFullyClosed_Stat "Completeness of window closing status";
CM_ SG_ 581 DMRL_ChildLock_Stat "Indicates the Child Lock status";
CM_ SG_ 581 DMRL_IntDoorHandle_Req "State of RL door internal handle: engaged or not";
CM_ SG_ 581 DMRL_IntDoorLockSw_Cmd "Interior door lock switch command";
CM_ SG_ 581 DMRL_DoorLockState "RL Door Lock Status";
CM_ SG_ 581 DMRL_ElcromeBright_Stat "RL door glass tinting status";
CM_ SG_ 581 DMRL_DoorMovement_Stat "RL door electric drive status";
CM_ SG_ 581 DMRL_RR_Window_Cmd "Request to control RL window from RR door";
CM_ SG_ 581 DMRL_RearCurtain_Req "Rear window blind control request from RL passenger";
CM_ SG_ 581 DMRL_DoorDirection_Stat "Direction of movement of the RL door";
CM_ SG_ 581 DMRL_Antipinch_Stat "State of antipinch function of RL door";
CM_ SG_ 581 DMRL_WarningInd "Request from DMRL to switch warning indicator in instrument cluster";
CM_ SG_ 581 DMRL_VolumeLevel_Cmd "The request to change volumme level via RL MMS  joystic.";
CM_ SG_ 581 DMRL_Multimedia_Req "Request to turn off/on the multimedia system from the RL passenger";
CM_ SG_ 581 DMRL_Comm_Req "Request to wake up the car from the RL door";
CM_ SG_ 581 DMRL_SunShade_Stat "State of RL window sun shade";
CM_ SG_ 581 DMRL_DoorAjarState "RL door opening status";
CM_ SG_ 581 DMRL_DoorAjarFault_Stat "The fault status of ajar sensor in door lock";
CM_ SG_ 579 DMFR_ShortDrop_Stat "FR window short drop position state";
CM_ SG_ 579 DMFR_DoorCloseSw_Req "Request for power closing door from external switch on door panel";
CM_ SG_ 579 DMFR_Comm_Req "Request to wake up the car from the FR door";
CM_ SG_ 579 DMFR_DoorMovement_Stat "FR door electric drive status";
CM_ SG_ 579 DMFR_MirrorHeating_Status "FR mirror heating status";
CM_ SG_ 579 DMFR_Antipinch_Stat "State of antipinch function of FR door";
CM_ SG_ 579 DMFR_IntDoorLockSw_Cmd "Interior door lock switch command";
CM_ SG_ 579 DMFR_TurnInd_Stat "FR turn signal repeater status";
CM_ SG_ 579 DMFR_DoorLockState "FR Door Lock Status";
CM_ SG_ 579 DMFR_DoorDirection_Stat "Direction of movement of the FR door";
CM_ SG_ 579 DMFR_WindowFullyClosed_Stat "Completeness of window closing status";
CM_ SG_ 579 DMFR_IntDoorHandle_Req "State of FR door internal handle: engaged or not";
CM_ SG_ 579 DMFR_WarningInd "Request from DMFR to switch warning indicator in instrument cluster";
CM_ SG_ 579 DMFR_BSDLed_Stat "FR Mirror Blind Spot Indicator Status";
CM_ SG_ 579 DMFR_DoorAjarState "FR door opening status";
CM_ SG_ 579 DMFR_DoorAjarFault_Stat "The fault status of ajar sensor in door lock";
CM_ SG_ 580 DMFL_ChildLockRRTab_Stat "State of Child lock function for rear right tab";
CM_ SG_ 580 DMFL_ChildLockRLTab_Stat "State of Child lock function for rear left tab";
CM_ SG_ 580 DMFL_ShortDrop_Stat "FL window short drop position state";
CM_ SG_ 580 DMFL_ChildLockCentralTab_Stat "State of Child lock function for central tab";
CM_ SG_ 580 DMFL_DoorCloseSw_Req "Request for power closing door from external switch on door panel";
CM_ SG_ 580 DMFL_RightMirrorFold_Cmd "Right Mirror folding command";
CM_ SG_ 580 DMFL_DoorMovement_Stat "FL door electric drive status";
CM_ SG_ 580 DMFL_KeyCylinder_Req "Request from the door lock cylinder";
CM_ SG_ 580 DMFL_DoorLockState "FL Door Lock Status";
CM_ SG_ 580 DMFL_RRWindow_Cmd "RR Window move command";
CM_ SG_ 580 DMFL_ChildLock_RRdoor_Stat "RR Window Child Lock Control";
CM_ SG_ 580 DMFL_ChildLock_RLwindow_Stat "Disable RL Window control";
CM_ SG_ 580 DMFL_WindowFullyClosed_Stat "Completeness of window closing status";
CM_ SG_ 580 DMFL_ChildLock_RRwindow_Stat "Disable RR Window control";
CM_ SG_ 580 DMFL_BSDLed_Stat "State of FL blind spot led";
CM_ SG_ 580 DMFL_IntDoorHandle_Req "State of FL door internal handle: engaged or not";
CM_ SG_ 580 DMFL_TurnInd_Stat "FL turn signal repeater status";
CM_ SG_ 580 DMFL_Antipinch_Stat "State of antipinch function of FL door";
CM_ SG_ 580 DMFL_WarningInd "Request from DMFL to switch warning indicator in instrument cluster";
CM_ SG_ 580 DMFL_Comm_Req "Request to wake up the car from the FL door";
CM_ SG_ 580 DMFL_RightMirrorTilt_Cmd "Right mirror tilt command";
CM_ SG_ 580 DMFL_RLWindow_Cmd "RL Window move command";
CM_ SG_ 580 DMFL_RearWindowCurtain_Req "Request to control rear window curtain from switch on FL door";
CM_ SG_ 580 DMFL_ChildLock_RLdoor_Stat "State of Child lock function for RL door lock";
CM_ SG_ 580 DMFL_RightMirrorAdjust_Cmd "Right Mirror Adjustment command";
CM_ SG_ 580 DMFL_ChildLock_Stat "Status of activation child lock function via switch on driver door";
CM_ SG_ 580 DMFL_MirrorHeating_Status "FL mirror heating status";
CM_ SG_ 580 DMFL_IntDoorLockSw_Cmd "Interior door lock switch command";
CM_ SG_ 580 DMFL_FRWindow_Cmd "FR Window move command";
CM_ SG_ 580 DMFL_DoorDirection_Stat "Direction of movement of the FL door";
CM_ SG_ 580 DMFL_DoorAjarState "FL door opening status";
CM_ SG_ 580 DMFL_DoorAjarFault_Stat "The fault status of ajar sensor in door lock";
CM_ SG_ 1104 DAS_AslaChSpd_Req "Asking the driver to select a new speed";
CM_ SG_ 1104 DAS_AaError_Stat "Error of AA (Attention Assist)";
CM_ SG_ 1104 DAS_RcwWarn_Req "RCW is requesting yellow alarm light";
CM_ SG_ 1104 DAS_NvMode_Stat "Mode of NightVision (NV)";
CM_ SG_ 1104 DAS_NvNotifError_Req "Error notification of NV (Night vision)";
CM_ SG_ 1104 DAS_RecMode_Stat "Mode of Videos recorder";
CM_ SG_ 1104 DAS_TsrMode_Stat "Mode of trafic sign recognition";
CM_ SG_ 1104 DAS_TsrSignSpeedType_Stat "Speed sign Type";
CM_ SG_ 1104 DAS_TsrSignOverTakingType_Stat "Overtaking sign Type";
CM_ SG_ 1104 DAS_RcwMode_Stat "Mode of Rear collision warning";
CM_ SG_ 1104 DAS_AaMode_Stat "Mode of trafic AA";
CM_ SG_ 1104 DAS_TsrSignError_Stat "Error of TSR";
CM_ SG_ 1104 DAS_AaWarnNotif_Req "Notification to wake up";
CM_ SG_ 1104 DAS_TsrSignNotifError_Req "Error notification of TSR";
CM_ SG_ 523 DAS_LdpNotifError_Req "Error notification of Ldp";
CM_ SG_ 523 DAS_ALccNotifError_Req "Error notification of ALCC";
CM_ SG_ 523 DAS_LdpRightLaneWarn_Req "LDP is requesting warning notification Right line";
CM_ SG_ 523 DAS_LdpLeftLaneWarn_Req "LDP is requesting warning notification Left line";
CM_ SG_ 523 DAS_LdwLeftLaneWarn_Req "LDW is requesting warning notification Left line";
CM_ SG_ 523 DAS_LkaWarnNotif_Req "Notification to take the steering wheel";
CM_ SG_ 523 DAS_LkaNotifError_Req "Error notification of LKA";
CM_ SG_ 523 DAS_DowMode_Stat "Mode of Door Open Warning";
CM_ SG_ 523 DAS_LccLeftWarn_Req "LCC is requesting activate notification left side";
CM_ SG_ 523 DAS_LccRightLed_Req "LCC is requesting activate right LED";
CM_ SG_ 523 DAS_LdwSound_Req "LDW is requesting warning sound";
CM_ SG_ 523 DAS_07_RC "Rolling Counter [0 - 15]";
CM_ SG_ 523 DAS_RdaNotifError_Req "Error notification of RDA";
CM_ SG_ 523 DAS_LccNotifError_Req "Error notification of LCC";
CM_ SG_ 523 DAS_LkaShootdownSound_Req "Sound when function is turned off";
CM_ SG_ 523 DAS_LccSound_Req "LCC is requesting sound warning";
CM_ SG_ 523 DAS_LdwMode_Stat "Mode of Lane Departure Warning";
CM_ SG_ 523 DAS_LccLeftLed_Req "LCC is requesting activate left LED";
CM_ SG_ 523 DAS_LdwNotifError_Req "Error notification of LDW";
CM_ SG_ 523 DAS_DowNotifError_Req "Error notification of DOW";
CM_ SG_ 523 DAS_RctcWarn_Req "RCTC is requesting warning notification";
CM_ SG_ 523 DAS_RdaWarn_Req "RDA is requesting warning notification";
CM_ SG_ 523 DAS_LdwRightLaneWarn_Req "LDW is requesting warning notification Right line";
CM_ SG_ 523 DAS_LkaWarnSound_Req "Warning sound to take the steering wheel";
CM_ SG_ 523 DAS_LccRightWarn_Req "LCC is requesting activate notification right side";
CM_ SG_ 523 DAS_07_CS "Checksum CRC8 SAE J1850 of the data field this message";
CM_ SG_ 523 DAS_LccMode_Stat "Mode of Lane Change Control (LCC)";
CM_ SG_ 356 DAS_USSSide_Req "ADAS is requesting to transmit data from USS side";
CM_ SG_ 356 DAS_USSRear_Req "ADAS is requesting to transmit data from USS rear";
CM_ SG_ 356 DAS_USSFront_Req "ADAS is requesting to transmit data from USS front";
CM_ SG_ 356 DAS_AdasSensLidarDirty_Stat "LIDAR sensor status";
CM_ SG_ 356 DAS_Main_CS "Checksum CRC8 SAE J1850 of the data field this message";
CM_ SG_ 356 DAS_AdasSensSteerWhLvl_Stat "Vibration level";
CM_ SG_ 356 DAS_Adas_SensTicuDirty_Stat "Termal Image sensor status";
CM_ SG_ 356 DAS_AdasSensMrrxDirty_Stat "Rear radar status";
CM_ SG_ 356 DAS_Main_RC "Rolling Counter [0 - 15]";
CM_ SG_ 356 DAS_AdasSensWSHeat_Req "ADAS is requesting heat on wind sheeld";
CM_ SG_ 356 DAS_AdasSensAllDirty_Stat "All Front sensors unit status";
CM_ SG_ 356 DAS_AdasSensFrcuDirty_Stat "Front radar status";
CM_ SG_ 356 DAS_AdasSensClear_Req "ADAS is requesting to clear sensor";
CM_ SG_ 356 DAS_AdasSensSteerWhVibr_Req "ADAS is requesting vibration on steering wheel";
CM_ SG_ 356 DAS_AdasAvailMode_Stat "ADAS Status";
CM_ SG_ 353 DAS_SettRdaAutoBrake_Stat "Status AutoBrake of RDA";
CM_ SG_ 353 DAS_ProjectionRoadSigns_Req "Projection of road signs enable request";
CM_ SG_ 353 DAS_ProjectionOnRoad_Req "Projection on a road enable request";
CM_ SG_ 353 DAS_ProjectionNavigation_Req "Projection of navigatoon system enable request";
CM_ SG_ 353 DAS_ProjectionLiveObj_Req "Projection of recognized live objects enable request";
CM_ SG_ 353 DAS_SettFcwMode_Stat "Mode of FCW";
CM_ SG_ 353 DAS_SettRda_Stat "Status of RDA";
CM_ SG_ 353 DAS_SettLdwVibration_Stat "Vibration on steering wheel when LDW is warning request";
CM_ SG_ 353 DAS_SettRctc_Stat "Status of RCTC";
CM_ SG_ 353 DAS_SettAa_Stat "Status of AA (Attention Assist)";
CM_ SG_ 353 DAS_SettLdw_Stat "Status of LDW";
CM_ SG_ 353 DAS_SettLdwSound_Stat "Sound on IC when LDW is warning";
CM_ SG_ 353 DAS_SettLdp_Stat "Status of LDP";
CM_ SG_ 353 DAS_SettLcc_Stat "Status of LCC";
CM_ SG_ 353 DAS_SettLdwMode_Stat "Mode of LDW";
CM_ SG_ 353 DAS_SettLka_Stat "Status of LKA";
CM_ SG_ 353 DAS_SettFcw_Stat "Status of FCW";
CM_ SG_ 353 DAS_SettRecResol_Stat "Resolution of video-file";
CM_ SG_ 353 DAS_SettSensClean_Stat "Status of Sensor clean function";
CM_ SG_ 353 DAS_SettCcMode_Stat "Mode selection";
CM_ SG_ 353 DAS_SettLccSound_Stat "Sound on IC when LCC is warning request";
CM_ SG_ 353 DAS_SettRec_Stat "Status of REC";
CM_ SG_ 353 DAS_SettDowSound_Stat "Sound on IC when DOW is warning request";
CM_ SG_ 353 DAS_SettAaMode_Stat "Mode of AA";
CM_ SG_ 353 DAS_SettAfs_Stat "Status of AFS (Automatic Forced Stop)";
CM_ SG_ 353 DAS_SettTsr_Stat "Status of TSR (Traffic Sign Recognition)";
CM_ SG_ 353 DAS_SettLccMode_Stat "Mode of LCC";
CM_ SG_ 353 DAS_FIU_Settings_RC "Rolling Counter [0 - 15]";
CM_ SG_ 353 DAS_SettRecFileSize_Stat "Size of video-file";
CM_ SG_ 353 DAS_SettDow_Stat "Status of DOW (Door Open Warning)";
CM_ SG_ 353 DAS_SettAslaOver_Stat "Overtaking speed";
CM_ SG_ 353 DAS_SettLccVibration_Stat "Vibration on steering wheel when LCC is warning request";
CM_ SG_ 353 DAS_SettFcwVibration_Stat "Vibration on steering wheel when FCW is warning request";
CM_ SG_ 353 DAS_SettCcSpdCorrect_Stat "Change of speed in a turn";
CM_ SG_ 353 DAS_SettCcType_Stat "Type selection";
CM_ SG_ 353 DAS_SettAlcc_Stat "Status of ALCC";
CM_ SG_ 353 DAS_FIU_Settings_CS "Checksum CRC8 SAE J1850 of the data field this message";
CM_ SG_ 353 DAS_SettAsla_Stat "Status of ASLA";
CM_ SG_ 353 DAS_SettAeb_Stat "Status of AEB (Automatic Emergency Braking)";
CM_ SG_ 778 DAS_LkaShootdownNotif_Req "Sound when function is turned off";
CM_ SG_ 778 DAS_MliaStreetLigth_Stat "The presence of artificial lighting";
CM_ SG_ 778 DAS_AccToCc_Req "Proposal to switch from ACC to CC";
CM_ SG_ 778 DAS_AccNotifError_Req "Error notification of ACC";
CM_ SG_ 778 DAS_LimNotifError_Req "Error notification of LIM (Speed Limiter)";
CM_ SG_ 778 DAS_AebUnAvaliable_Stat "The function works, but does not see objects due to rain/sunlight";
CM_ SG_ 778 DAS_LkaAngleSpeed_Req "Maximum required steering angle speed";
CM_ SG_ 778 DAS_AebDeactivNotif_Stat "Notification for IC: Emergency braking is turn-off";
CM_ SG_ 778 DAS_CcSetDist_Stat "Target distance";
CM_ SG_ 778 DAS_CcReject_Req "CC is requesting the notification";
CM_ SG_ 778 DAS_CcNotifError_Req "Error notification of CC";
CM_ SG_ 778 DAS_FcwSoundWarn_Req "FCW is requesting warning sound";
CM_ SG_ 778 DAS_AslaMode_Stat "Mode of Active speed limit assist";
CM_ SG_ 778 DAS_CcTargetId_Stat "Target car number";
CM_ SG_ 778 DAS_AebNotifError_Req "Error notification of AEB";
CM_ SG_ 778 DAS_FcwNotifError_Req "Error notification of FCW (Forward Collision Warning)";
CM_ SG_ 778 DAS_FcwMode_Stat "Mode of front colision warning";
CM_ SG_ 778 DAS_CcType_Stat "Type cruis control";
CM_ SG_ 778 DAS_CcSleep_Stat "CC has fallen asleep";
CM_ SG_ 778 DAS_FcwActivNotif_Req "Notification for IC: Front collision warning is activated";
CM_ SG_ 778 DAS_03_RC "Rolling Counter [0 - 15]";
CM_ SG_ 778 DAS_CcSetSpeed_Stat "Target speed, kmh";
CM_ SG_ 778 DAS_03_CS "Checksum XOR8 of the data field this message
Checksum computed as per XOR algorithm:
Byte 1 XOR byte 2 .... XOR byte n-1. (n = packet length.)";
CM_ SG_ 778 DAS_MliaMode_Stat "Mode of Matrix light assistant";
CM_ SG_ 778 DAS_MliaFuncError_Stat "Error  of MLIA (Matrix Led Intelligent Assist)";
CM_ SG_ 642 BCM_RoofControl_Req "Soft roof  control request";
CM_ SG_ 642 BCM_AdasSensWSHeat_Req "ADAS is requesting heat on wind sheeld";
CM_ SG_ 642 BCM_PanoramicViewLed_Cmd "Request frrom BCM for activation LED indicator on Panoramic View Switch (CCPR)";
CM_ SG_ 642 BCM_AntiTheft_Stat "Status of activation Ani Theft system.";
CM_ SG_ 642 BCM_LccBtn_Stat "Lane change Control button state";
CM_ SG_ 642 BCM_LdwBtn_Stat "Lane departure warning control button state";
CM_ SG_ 642 BCM_AdasSensClear_Stat "State of ADAS elements washing";
CM_ SG_ 642 BCM_FootrestRRWarning_Stat "Footrest RR warning status
Straponten on warning on rear tablet";
CM_ SG_ 642 BCM_AmbientTempHMI "Ambient temperature for inform an user";
CM_ SG_ 642 BCM_GovernmentComSw_Stat "The status of activating Switch for government communication. The InterCom System shall be deactivated after 5s, when switch active.";
CM_ SG_ 642 BCM_FootrestRLWarning_Stat "Footrest RL warning status
Straponten on warning on rear tablet";
CM_ SG_ 642 BCM_MAS_Activation_Req "Parking assistent switch state";
CM_ SG_ 642 BCM_EasyExitSMFL_Stat "Easy exit request to SMFL";
CM_ SG_ 642 BCM_GovernmentHandset_Stat "The status of handset for government communication, The Intercom system shall be deactivated immediatly, when handset is picked up.";
CM_ SG_ 642 BCM_ElcromeMirror_Req "Request to control electrochrome of outside mirrors";
CM_ SG_ 642 BCM_HeadUpDispSw_Stat "State of head-up display switch";
CM_ SG_ 642 BCM_RearWindowHeatingLED "Request to on/off rear window heating control indicator";
CM_ SG_ 642 BCM_EasyExitSMRL_Stat "Easy exit request to SMRL";
CM_ SG_ 642 BCM_EasyExitSMRR_Stat "Easy exit request to SMRR";
CM_ SG_ 642 BCM_EasyExitSMFR_Stat "Easy exit request to SMFR";
CM_ SG_ 642 BCM_FootrestRR_Stat "Footrest RR status
Status position footrest from BCM";
CM_ SG_ 642 BCM_FootrestRL_Stat "Footrest RL status
Status position footrest from BCM";
CM_ SG_ 642 BCM_RemoteStart_Stat "Satet of remote start process";
CM_ SG_ 642 BCM_T15h_Deactivation_Req "T15h terminal deactivation request signal from BCM.";
BA_DEF_ SG_  "GenSigEVName" STRING ;
BA_DEF_ SG_  "SigType" ENUM  "Default","Range","RangeSigned","ASCII","Discrete","Control","ReferencePGN","DTC","StringDelimiter","StringLength","StringLengthControl","MessageCounter","MessageChecksum";
BA_DEF_ SG_  "GenSigILSupport" ENUM  "No","Yes";
BA_DEF_ SG_  "GenSigSendType" ENUM  "Cyclic","OnWrite","OnWriteWithRepetition","OnChange","OnChangeWithRepetition","IfActive","IfActiveWithRepetition","NoSigSendType","NotUsed","NotUsed","NotUsed","NotUsed","NotUsed";
BA_DEF_ SG_  "GenSigStartValue" INT 0 0;
BA_DEF_ BO_  "GenMsgRequestable" INT 0 1;
BA_DEF_ BO_  "GenMsgILSupport" ENUM  "No","Yes";
BA_DEF_ BO_  "VFrameFormat" ENUM  "StandardCAN","ExtendedCAN","reserved","J1939PG","reserved","reserved","reserved","reserved","reserved","reserved","reserved","reserved","reserved","reserved","StandardCAN_FD","ExtendedCAN_FD";
BA_DEF_ BO_  "J1939PgAppearanceOnBus" ENUM  "Default","CAN_Extended","CANFD_Extended";
BA_DEF_ BO_  "J1939CPgTOS" INT 0 7;
BA_DEF_ BO_  "J1939CPgSendTimeout" INT -1 3600000;
BA_DEF_ BO_  "DiagRequest" ENUM  "No","Yes";
BA_DEF_ BO_  "CANFD_BRS" ENUM  "0","1";
BA_DEF_ BO_  "GenMsgCycleTime" INT 0 0;
BA_DEF_ BO_  "GenMsgSendType" ENUM  "Cyclic","Spontaneous","IfActive","NoMsgSendType","NotUsed";
BA_DEF_ BU_  "J1939MultiPgSizeThreshold" INT 0 64;
BA_DEF_ BU_  "J1939MultiPgSendTimeout" INT 0 3600000;
BA_DEF_ BU_  "J1939MultiPgBroadcastType" ENUM  "FBFF","FEFF";
BA_DEF_  "MultiplexExtEnabled" ENUM  "No","Yes";
BA_DEF_  "BaudrateFD" INT 0 5000000;
BA_DEF_  "Project" STRING ;
BA_DEF_  "DBName" STRING ;
BA_DEF_  "Baudrate" INT 0 1000000;
BA_DEF_  "BusType" STRING ;
BA_DEF_  "Manufacturer" STRING ;
BA_DEF_DEF_  "GenSigEVName" "Env@Nodename_@Signame";
BA_DEF_DEF_  "SigType" "Default";
BA_DEF_DEF_  "GenSigILSupport" "Yes";
BA_DEF_DEF_  "GenSigSendType" "Cyclic";
BA_DEF_DEF_  "GenSigStartValue" 0;
BA_DEF_DEF_  "GenMsgRequestable" 1;
BA_DEF_DEF_  "GenMsgILSupport" "Yes";
BA_DEF_DEF_  "VFrameFormat" "";
BA_DEF_DEF_  "J1939PgAppearanceOnBus" "Default";
BA_DEF_DEF_  "J1939CPgTOS" 2;
BA_DEF_DEF_  "J1939CPgSendTimeout" -1;
BA_DEF_DEF_  "DiagRequest" "No";
BA_DEF_DEF_  "CANFD_BRS" "1";
BA_DEF_DEF_  "GenMsgCycleTime" 0;
BA_DEF_DEF_  "GenMsgSendType" "";
BA_DEF_DEF_  "J1939MultiPgSizeThreshold" 56;
BA_DEF_DEF_  "J1939MultiPgSendTimeout" 2;
BA_DEF_DEF_  "J1939MultiPgBroadcastType" "FBFF";
BA_DEF_DEF_  "MultiplexExtEnabled" "No";
BA_DEF_DEF_  "BaudrateFD" 0;
BA_DEF_DEF_  "Project" "UMP 1.5";
BA_DEF_DEF_  "DBName" "";
BA_DEF_DEF_  "Baudrate" 500000;
BA_DEF_DEF_  "BusType" "CAN";
BA_DEF_DEF_  "Manufacturer" "NAMI";
BA_ "MultiplexExtEnabled" 1;
BA_ "BaudrateFD" 2000000;
BA_ "BusType" "CAN FD";
BA_ "DBName" "ADASCANFD";
BA_ "VFrameFormat" BO_ 355 0;
BA_ "GenMsgCycleTime" BO_ 355 50;
BA_ "GenMsgSendType" BO_ 355 0;
BA_ "VFrameFormat" BO_ 640 0;
BA_ "GenMsgCycleTime" BO_ 640 50;
BA_ "GenMsgSendType" BO_ 640 0;
BA_ "VFrameFormat" BO_ 1535 0;
BA_ "GenMsgCycleTime" BO_ 1535 5000;
BA_ "GenMsgSendType" BO_ 1535 0;
BA_ "VFrameFormat" BO_ 1309 0;
BA_ "GenMsgCycleTime" BO_ 1309 250;
BA_ "GenMsgSendType" BO_ 1309 0;
BA_ "VFrameFormat" BO_ 894 0;
BA_ "GenMsgCycleTime" BO_ 894 100;
BA_ "GenMsgSendType" BO_ 894 0;
BA_ "VFrameFormat" BO_ 893 0;
BA_ "GenMsgCycleTime" BO_ 893 100;
BA_ "GenMsgSendType" BO_ 893 0;
BA_ "VFrameFormat" BO_ 891 0;
BA_ "GenMsgCycleTime" BO_ 891 100;
BA_ "GenMsgSendType" BO_ 891 0;
BA_ "VFrameFormat" BO_ 567 0;
BA_ "GenMsgCycleTime" BO_ 567 100;
BA_ "GenMsgSendType" BO_ 567 0;
BA_ "VFrameFormat" BO_ 1902 0;
BA_ "GenMsgSendType" BO_ 1902 1;
BA_ "VFrameFormat" BO_ 1901 0;
BA_ "GenMsgSendType" BO_ 1901 1;
BA_ "VFrameFormat" BO_ 1894 0;
BA_ "GenMsgSendType" BO_ 1894 1;
BA_ "VFrameFormat" BO_ 1893 0;
BA_ "GenMsgSendType" BO_ 1893 1;
BA_ "VFrameFormat" BO_ 1900 0;
BA_ "GenMsgSendType" BO_ 1900 1;
BA_ "VFrameFormat" BO_ 1915 0;
BA_ "GenMsgSendType" BO_ 1915 1;
BA_ "VFrameFormat" BO_ 1898 0;
BA_ "GenMsgSendType" BO_ 1898 1;
BA_ "VFrameFormat" BO_ 1897 0;
BA_ "GenMsgSendType" BO_ 1897 1;
BA_ "VFrameFormat" BO_ 1910 0;
BA_ "GenMsgSendType" BO_ 1910 1;
BA_ "VFrameFormat" BO_ 1909 0;
BA_ "GenMsgSendType" BO_ 1909 1;
BA_ "VFrameFormat" BO_ 1918 0;
BA_ "GenMsgSendType" BO_ 1918 1;
BA_ "VFrameFormat" BO_ 1917 0;
BA_ "GenMsgSendType" BO_ 1917 1;
BA_ "VFrameFormat" BO_ 1916 0;
BA_ "GenMsgSendType" BO_ 1916 1;
BA_ "VFrameFormat" BO_ 1899 0;
BA_ "GenMsgSendType" BO_ 1899 1;
BA_ "VFrameFormat" BO_ 1914 0;
BA_ "GenMsgSendType" BO_ 1914 1;
BA_ "VFrameFormat" BO_ 1913 0;
BA_ "GenMsgSendType" BO_ 1913 1;
BA_ "VFrameFormat" BO_ 387 0;
BA_ "GenMsgCycleTime" BO_ 387 10;
BA_ "GenMsgSendType" BO_ 387 0;
BA_ "VFrameFormat" BO_ 724 0;
BA_ "GenMsgCycleTime" BO_ 724 100;
BA_ "GenMsgSendType" BO_ 724 0;
BA_ "VFrameFormat" BO_ 933 0;
BA_ "GenMsgCycleTime" BO_ 933 100;
BA_ "GenMsgSendType" BO_ 933 0;
BA_ "VFrameFormat" BO_ 141 0;
BA_ "GenMsgCycleTime" BO_ 141 10;
BA_ "GenMsgSendType" BO_ 141 0;
BA_ "VFrameFormat" BO_ 593 0;
BA_ "GenMsgCycleTime" BO_ 593 100;
BA_ "GenMsgSendType" BO_ 593 0;
BA_ "VFrameFormat" BO_ 242 0;
BA_ "GenMsgCycleTime" BO_ 242 100;
BA_ "GenMsgSendType" BO_ 242 0;
BA_ "VFrameFormat" BO_ 305 0;
BA_ "GenMsgCycleTime" BO_ 305 10;
BA_ "GenMsgSendType" BO_ 305 0;
BA_ "VFrameFormat" BO_ 277 0;
BA_ "GenMsgCycleTime" BO_ 277 20;
BA_ "GenMsgSendType" BO_ 277 0;
BA_ "VFrameFormat" BO_ 902 0;
BA_ "GenMsgCycleTime" BO_ 902 50;
BA_ "GenMsgSendType" BO_ 902 0;
BA_ "VFrameFormat" BO_ 901 0;
BA_ "GenMsgCycleTime" BO_ 901 50;
BA_ "GenMsgSendType" BO_ 901 0;
BA_ "VFrameFormat" BO_ 583 0;
BA_ "GenMsgCycleTime" BO_ 583 50;
BA_ "GenMsgSendType" BO_ 583 0;
BA_ "VFrameFormat" BO_ 900 0;
BA_ "GenMsgCycleTime" BO_ 900 50;
BA_ "GenMsgSendType" BO_ 900 0;
BA_ "VFrameFormat" BO_ 899 0;
BA_ "GenMsgCycleTime" BO_ 899 50;
BA_ "GenMsgSendType" BO_ 899 0;
BA_ "VFrameFormat" BO_ 177 0;
BA_ "GenMsgCycleTime" BO_ 177 10;
BA_ "GenMsgSendType" BO_ 177 0;
BA_ "VFrameFormat" BO_ 568 0;
BA_ "GenMsgCycleTime" BO_ 568 100;
BA_ "GenMsgSendType" BO_ 568 0;
BA_ "VFrameFormat" BO_ 688 0;
BA_ "GenMsgCycleTime" BO_ 688 10;
BA_ "GenMsgSendType" BO_ 688 0;
BA_ "VFrameFormat" BO_ 904 0;
BA_ "GenMsgCycleTime" BO_ 904 50;
BA_ "GenMsgSendType" BO_ 904 0;
BA_ "VFrameFormat" BO_ 903 0;
BA_ "GenMsgCycleTime" BO_ 903 50;
BA_ "GenMsgSendType" BO_ 903 0;
BA_ "VFrameFormat" BO_ 976 0;
BA_ "GenMsgCycleTime" BO_ 976 100;
BA_ "GenMsgSendType" BO_ 976 0;
BA_ "VFrameFormat" BO_ 320 0;
BA_ "GenMsgCycleTime" BO_ 320 100;
BA_ "GenMsgSendType" BO_ 320 0;
BA_ "VFrameFormat" BO_ 777 0;
BA_ "GenMsgCycleTime" BO_ 777 100;
BA_ "GenMsgSendType" BO_ 777 0;
BA_ "VFrameFormat" BO_ 746 0;
BA_ "GenMsgCycleTime" BO_ 746 100;
BA_ "GenMsgSendType" BO_ 746 0;
BA_ "VFrameFormat" BO_ 304 0;
BA_ "GenMsgCycleTime" BO_ 304 10;
BA_ "GenMsgSendType" BO_ 304 0;
BA_ "VFrameFormat" BO_ 275 0;
BA_ "GenMsgCycleTime" BO_ 275 100;
BA_ "GenMsgSendType" BO_ 275 0;
BA_ "VFrameFormat" BO_ 274 0;
BA_ "GenMsgCycleTime" BO_ 274 20;
BA_ "GenMsgSendType" BO_ 274 0;
BA_ "VFrameFormat" BO_ 273 0;
BA_ "GenMsgCycleTime" BO_ 273 20;
BA_ "GenMsgSendType" BO_ 273 0;
BA_ "VFrameFormat" BO_ 272 0;
BA_ "GenMsgCycleTime" BO_ 272 20;
BA_ "GenMsgSendType" BO_ 272 0;
BA_ "VFrameFormat" BO_ 164 0;
BA_ "GenMsgCycleTime" BO_ 164 10;
BA_ "GenMsgSendType" BO_ 164 0;
BA_ "VFrameFormat" BO_ 163 0;
BA_ "GenMsgCycleTime" BO_ 163 10;
BA_ "GenMsgSendType" BO_ 163 0;
BA_ "VFrameFormat" BO_ 1292 0;
BA_ "GenMsgSendType" BO_ 1292 1;
BA_ "VFrameFormat" BO_ 1293 0;
BA_ "GenMsgCycleTime" BO_ 1293 500;
BA_ "GenMsgSendType" BO_ 1293 0;
BA_ "VFrameFormat" BO_ 743 0;
BA_ "GenMsgCycleTime" BO_ 743 1000;
BA_ "GenMsgSendType" BO_ 743 0;
BA_ "VFrameFormat" BO_ 898 0;
BA_ "GenMsgCycleTime" BO_ 898 50;
BA_ "GenMsgSendType" BO_ 898 0;
BA_ "VFrameFormat" BO_ 897 0;
BA_ "GenMsgCycleTime" BO_ 897 50;
BA_ "GenMsgSendType" BO_ 897 0;
BA_ "VFrameFormat" BO_ 1428 0;
BA_ "GenMsgSendType" BO_ 1428 1;
BA_ "VFrameFormat" BO_ 464 0;
BA_ "GenMsgCycleTime" BO_ 464 10;
BA_ "GenMsgSendType" BO_ 464 0;
BA_ "VFrameFormat" BO_ 1198 0;
BA_ "GenMsgCycleTime" BO_ 1198 50;
BA_ "GenMsgSendType" BO_ 1198 0;
BA_ "VFrameFormat" BO_ 1196 0;
BA_ "GenMsgCycleTime" BO_ 1196 50;
BA_ "GenMsgSendType" BO_ 1196 0;
BA_ "VFrameFormat" BO_ 1194 0;
BA_ "GenMsgCycleTime" BO_ 1194 50;
BA_ "GenMsgSendType" BO_ 1194 0;
BA_ "VFrameFormat" BO_ 1192 0;
BA_ "GenMsgCycleTime" BO_ 1192 50;
BA_ "GenMsgSendType" BO_ 1192 0;
BA_ "VFrameFormat" BO_ 1190 0;
BA_ "GenMsgCycleTime" BO_ 1190 50;
BA_ "GenMsgSendType" BO_ 1190 0;
BA_ "VFrameFormat" BO_ 1188 0;
BA_ "GenMsgCycleTime" BO_ 1188 50;
BA_ "GenMsgSendType" BO_ 1188 0;
BA_ "VFrameFormat" BO_ 1424 0;
BA_ "GenMsgCycleTime" BO_ 1424 1000;
BA_ "GenMsgSendType" BO_ 1424 0;
BA_ "VFrameFormat" BO_ 538 0;
BA_ "GenMsgCycleTime" BO_ 538 20;
BA_ "GenMsgSendType" BO_ 538 0;
BA_ "VFrameFormat" BO_ 582 0;
BA_ "GenMsgCycleTime" BO_ 582 50;
BA_ "GenMsgSendType" BO_ 582 0;
BA_ "VFrameFormat" BO_ 581 0;
BA_ "GenMsgCycleTime" BO_ 581 50;
BA_ "GenMsgSendType" BO_ 581 0;
BA_ "VFrameFormat" BO_ 579 0;
BA_ "GenMsgCycleTime" BO_ 579 50;
BA_ "GenMsgSendType" BO_ 579 0;
BA_ "VFrameFormat" BO_ 580 0;
BA_ "GenMsgCycleTime" BO_ 580 50;
BA_ "GenMsgSendType" BO_ 580 0;
BA_ "VFrameFormat" BO_ 1104 0;
BA_ "GenMsgCycleTime" BO_ 1104 250;
BA_ "GenMsgSendType" BO_ 1104 0;
BA_ "VFrameFormat" BO_ 523 0;
BA_ "GenMsgCycleTime" BO_ 523 100;
BA_ "GenMsgSendType" BO_ 523 0;
BA_ "VFrameFormat" BO_ 356 0;
BA_ "GenMsgCycleTime" BO_ 356 50;
BA_ "GenMsgSendType" BO_ 356 0;
BA_ "VFrameFormat" BO_ 353 0;
BA_ "GenMsgCycleTime" BO_ 353 100;
BA_ "GenMsgSendType" BO_ 353 0;
BA_ "VFrameFormat" BO_ 778 0;
BA_ "GenMsgCycleTime" BO_ 778 50;
BA_ "GenMsgSendType" BO_ 778 0;
BA_ "VFrameFormat" BO_ 642 0;
BA_ "GenMsgCycleTime" BO_ 642 100;
BA_ "GenMsgSendType" BO_ 642 0;
BA_ "GenSigStartValue" SG_ 1309 BCM_LightSwReason_Val 6;
BA_ "GenSigStartValue" SG_ 724 VCU_MaxAlowTrq_Val 5427;
BA_ "GenSigStartValue" SG_ 933 EMS_MinCurrentStaty 1023;
BA_ "GenSigStartValue" SG_ 933 EMS_MaxCurrentStaty 1023;
BA_ "GenSigStartValue" SG_ 933 EMS_MaxTorque 1023;
BA_ "GenSigStartValue" SG_ 933 EMS_MinTorque 1023;
BA_ "GenSigStartValue" SG_ 141 EMS_DesEMotorTorque 16383;
BA_ "GenSigStartValue" SG_ 141 EMS_DesInvMode 15;
BA_ "GenSigStartValue" SG_ 305 ESC_NotSupported 65535;
BA_ "GenSigStartValue" SG_ 305 ESC_AX 32767;
BA_ "GenSigStartValue" SG_ 277 EMS_MMotActLm 30000;
BA_ "GenSigStartValue" SG_ 277 EMS_MMotMax 30000;
BA_ "GenSigStartValue" SG_ 304 ESC_PSIP1_Val 32768;
BA_ "GenSigStartValue" SG_ 274 ESC_VacuumPressure_Val 20;
BA_ "GenSigStartValue" SG_ 272 ESC_ATCTrqRq_Val 30000;
BA_ "GenSigStartValue" SG_ 538 EPB_TargetDecel_Val 80;
BA_ "GenSigStartValue" SG_ 582 DMRR_DoorAjarState 1;
BA_ "GenSigStartValue" SG_ 581 DMRL_DoorAjarState 1;
BA_ "GenSigStartValue" SG_ 579 DMFR_DoorAjarState 1;
BA_ "GenSigStartValue" SG_ 580 DMFL_ChildLockRRTab_Stat 1;
BA_ "GenSigStartValue" SG_ 580 DMFL_ChildLockRLTab_Stat 1;
BA_ "GenSigStartValue" SG_ 580 DMFL_ChildLockCentralTab_Stat 1;
BA_ "GenSigStartValue" SG_ 580 DMFL_ChildLock_RRdoor_Stat 1;
BA_ "GenSigStartValue" SG_ 580 DMFL_ChildLock_RLwindow_Stat 1;
BA_ "GenSigStartValue" SG_ 580 DMFL_ChildLock_RRwindow_Stat 1;
BA_ "GenSigStartValue" SG_ 580 DMFL_ChildLock_RLdoor_Stat 1;
VAL_ 3221225472 MAS_TmissionMode_Req 0 "Not requested" 1 "P" 2 "R" 3 "N" 4 "D" ;
VAL_ 355 DAS_MASPermission_Stat 0 "No permission" 1 "Permission" ;
VAL_ 355 DAS_MasStop_Req 0 "Not requested" 1 "Requested" ;
VAL_ 355 DAS_MasPause_Req 0 "Not requested" 1 "Requested" ;
VAL_ 355 DAS_DistanceTraveled_Val 0 "Not requested" 1 "Requested" ;
VAL_ 640 BCM_T15_Stat 1 "Terminal active" 0 "Terminal inactive" ;
VAL_ 640 BCM_CCTerm_Stat 1 "Terminal on" 0 "Terminal off" ;
VAL_ 640 BCM_SwIndIntens_Stat 1 "Low level" 0 "Hight level" ;
VAL_ 640 BCM_T30d_Stat 1 "Terminal active" 0 "Terminal inactive" ;
VAL_ 640 HUD_IntensityRequest 255 "Fault" ;
VAL_ 640 StealthModeEn 1 "Stealth Mode enable" 0 "Stealth Mode disable" ;
VAL_ 640 BCM_T30i_DisableWarning 1 "Warning Active" 0 "No Warning" ;
VAL_ 640 BCM_T30i_Stat 1 "Terminal active" 0 "Terminal inactive" ;
VAL_ 640 BCM_Light_Stat 1 "Terminal on" 0 "Terminal off" ;
VAL_ 640 BCM_LightBCM_Stat 1 "Terminal on" 0 "Terminal off" ;
VAL_ 640 BCM_CCTermDisableWarning 1 "Warning Active" 0 "No Warning" ;
VAL_ 640 BCM_SwBackIntens_Val 255 "Fault" ;
VAL_ 640 BCM_LVBatteryVoltage 255 "Error" ;
VAL_ 640 BCM_PreheatFunction_Stat 3 "Preheating Fault" 2 "Preheating Active" 1 "Preheatng In progress/ Additional Heating" 0 "Preheating Inactive" ;
VAL_ 640 BCM_ADASTerm_Stat 1 "Terminal on" 0 "Terminal off" ;
VAL_ 640 BCM_VehicleBody_Stat 6 "Sedan long" 5 "Cabrio" 4 "SUV" 3 "MPV" 2 "Limo" 1 "Sedan" 0 "Not set" ;
VAL_ 640 BCM_T30d_DisableWarning 1 "Warning Active" 0 "No Warning" ;
VAL_ 640 BCM_VehicleType_Stat 1 "Armored" 0 "Normal" ;
VAL_ 640 BCM_T15h_Stat 1 "Terminal active" 0 "Terminal inactive" ;
VAL_ 640 BCM_VehicleMode_Stat 6 "RemoteStart_Mode" 5 "Service_Mode" 4 "Drive_Mode" 3 "Ignition_Mode" 2 "StandBy_Mode" 1 "PreHeating_Mode" 0 "Sleep_Mode" ;
VAL_ 640 BCM_Vehicle_DrvMode 6 "Reserved" 5 "Reserved" 4 "Offroad" 3 "Reserved" 2 "Range" 1 "Dynamic" 0 "Comfort" 7 "Reserved" ;
VAL_ 640 BCM_VehiclePowertrain_Stat 3 "PFCV" 2 "PHEV" 1 "BEV" 0 "HEV (default)" ;
VAL_ 640 BCM_SPV_Feature_Stat 1 "SPV vehicle type" 0 "Commercial vehicle type" ;
VAL_ 1535 DAS_CaebConf_Stat 1 "Set in the configuration" 0 "No set in the configuration" ;
VAL_ 1535 DAS_CcConf_Stat 0 "no set in the configuration" 1 "set in the configuration" ;
VAL_ 1535 DAS_AccConf_Stat 0 "no set in the configuration" 1 "set in the configuration" ;
VAL_ 1535 DAS_LimConf_Stat 0 "no set in the configuration" 1 "set in the configuration" ;
VAL_ 1535 DAS_AslaConf_Stat 0 "no set in the configuration" 1 "set in the configuration" ;
VAL_ 1535 DAS_LkaConf_Stat 0 "no set in the configuration" 1 "set in the configuration" ;
VAL_ 1535 DAS_FcwConf_Stat 0 "no set in the configuration" 1 "set in the configuration" ;
VAL_ 1535 DAS_AebConf_Stat 0 "no set in the configuration" 1 "set in the configuration" ;
VAL_ 1535 DAS_LccConf_Stat 0 "no set in the configuration" 1 "set in the configuration" ;
VAL_ 1535 DAS_AlccConf_Stat 0 "no set in the configuration" 1 "set in the configuration" ;
VAL_ 1535 DAS_DowConf_Stat 0 "no set in the configuration" 1 "set in the configuration" ;
VAL_ 1535 DAS_LdwConf_Stat 0 "no set in the configuration" 1 "set in the configuration" ;
VAL_ 1535 DAS_LdpConf_Stat 0 "no set in the configuration" 1 "set in the configuration" ;
VAL_ 1535 DAS_TsrConf_Stat 0 "no set in the configuration" 1 "set in the configuration" ;
VAL_ 1535 DAS_AaConf_Stat 0 "no set in the configuration" 1 "set in the configuration" ;
VAL_ 1535 DAS_AfsConf_Stat 0 "no set in the configuration" 1 "set in the configuration" ;
VAL_ 1535 DAS_RdaConf_Stat 0 "no set in the configuration" 1 "set in the configuration" ;
VAL_ 1535 DAS_RctcConf_Stat 0 "no set in the configuration" 1 "set in the configuration" ;
VAL_ 1535 DAS_RcwConf_Stat 0 "no set in the configuration" 1 "set in the configuration" ;
VAL_ 1535 DAS_RecConf_Stat 0 "no set in the configuration" 1 "set in the configuration" ;
VAL_ 1535 DAS_NvConf_Stat 0 "no set in the configuration" 1 "set in the configuration" ;
VAL_ 1535 DAS_VisualConf_Stat 0 "no set in the configuration" 1 "set in the configuration" ;
VAL_ 1535 DAS_MliaConf_Stat 1 "Set in the configuration" 0 "No set in the configuration" ;
VAL_ 1309 BCM_LightAmbient_Val 255 "Signal invalid" ;
VAL_ 1309 BCM_LightFront_Val 255 "Signal invalid" ;
VAL_ 1309 BCM_LightSwReason_Val 0 "Day" 1 "Twillight" 2 "Darkness" 3 "Precipitation" 4 "Tunnel" 5 "Underground car park" 6 "Signal invalid " ;
VAL_ 894 MAS_Sensor7_Distance_Val 0 "Minimum distance (0 cm) from sensor to obstacle" 254 "No obstacle or  Distance to obstacle > 600 cm" 255 "Sensor failure detected" ;
VAL_ 894 MAS_Sensor6_Distance_Val 0 "Minimum distance (0 cm) from sensor to obstacle" 254 "No obstacle or  Distance to obstacle > 600 cm" 255 "Sensor failure detected" ;
VAL_ 894 MAS_Sensor1_Distance_Val 0 "Minimum distance (0 cm) from sensor to obstacle" 254 "No obstacle or  Distance to obstacle > 600 cm" 255 "Sensor failure detected" ;
VAL_ 894 MAS_Sensor12_Distance_Val 0 "Minimum distance (0 cm) from sensor to obstacle" 254 "No obstacle or  Distance to obstacle > 600 cm" 255 "Sensor failure detected" ;
VAL_ 893 MAS_Sensor9_Distance_Val 0 "Minimum distance (0 cm) from sensor to obstacle" 254 "No obstacle or  Distance to obstacle > 250 cm" 255 "Sensor failure detected" ;
VAL_ 893 MAS_Sensor8_Distance_Val 0 "Minimum distance (0 cm) from sensor to obstacle" 254 "No obstacle or  Distance to obstacle > 250 cm" 255 "Sensor failure detected" ;
VAL_ 893 MAS_Sensor11_Distance_Val 0 "Minimum distance (0 cm) from sensor to obstacle" 254 "No obstacle or  Distance to obstacle > 250 cm" 255 "Sensor failure detected" ;
VAL_ 893 MAS_Sensor10_Distance_Val 0 "Minimum distance (0 cm) from sensor to obstacle" 254 "No obstacle or  Distance to obstacle > 250 cm" 255 "Sensor failure detected" ;
VAL_ 891 MAS_Sensor5_Distance_Val 0 "Minimum distance (0 cm) from sensor to obstacle" 254 "No obstacle or  Distance to obstacle > 250 cm" 255 "Sensor failure detected" ;
VAL_ 891 MAS_Sensor4_Distance_Val 0 "Minimum distance (0 cm) from sensor to obstacle" 254 "No obstacle or  Distance to obstacle > 250 cm" 255 "Sensor failure detected" ;
VAL_ 891 MAS_Sensor3_Distance_Val 0 "Minimum distance (0 cm) from sensor to obstacle" 254 "No obstacle or  Distance to obstacle > 250 cm" 255 "Sensor failure detected" ;
VAL_ 891 MAS_Sensor2_Distance_Val 0 "Minimum distance (0 cm) from sensor to obstacle" 254 "No obstacle or  Distance to obstacle > 250 cm" 255 "Sensor failure detected" ;
VAL_ 567 SWM_DC_WheelPosition_Stat 63 "Failure" ;
VAL_ 567 SWM_MMSPrevBtn_Stat 3 "Failure" 2 "Pressed" 1 "Released" 0 "Reserved" ;
VAL_ 567 SWM_DC_WheelButton_Stat 3 "Failure" 2 "Pressed" 1 "Released" 0 "Reserved" ;
VAL_ 567 SWM_TELBtn_Stat 3 "Failure" 2 "Pressed" 1 "Released" 0 "Reserved" ;
VAL_ 567 SWM_ECULED_Stat 3 "Failure" 2 "On" 1 "Off" 0 "Reserved" ;
VAL_ 567 SWM_ACC_SpeedIncrease_Stat 3 "Failure" 2 "Pressed" 1 "Released" 0 "Reserved" ;
VAL_ 567 SWM_ACCDistanceChange_Stat 3 "Failure" 2 "Pressed" 1 "Released" 0 "Reserved" ;
VAL_ 567 SWM_UpshiftPaddle_Stat 3 "Failure" 2 "Pressed" 1 "Released" 0 "Reserved" ;
VAL_ 567 SWM_ACCactivate_Stat 3 "Failure" 2 "Pressed" 1 "Released" 0 "Reserved" ;
VAL_ 567 SWM_MMSNextBtn_Stat 3 "Failure" 2 "Pressed" 1 "Released" 0 "Reserved" ;
VAL_ 567 SWM_ACCSpeedDecrease_Stat 3 "Failure" 2 "Pressed" 1 "Released" 0 "Reserved" ;
VAL_ 567 SWM_DownshiftPaddle_Stat 3 "Failure" 2 "Pressed" 1 "Released" 0 "Reserved" ;
VAL_ 567 SWM_VOLWheelBtn_Stat 3 "Failure" 2 "Pressed" 1 "Released" 0 "Reserved" ;
VAL_ 567 SWM_VCBtn_Stat 3 "Failure" 2 "Pressed" 1 "Released" 0 "Reserved" ;
VAL_ 387 VCU_DriverDmdTrq_Val 65535 "Init" ;
VAL_ 387 VCU_DriverDmdTrqInt_Val 65535 "Init" ;
VAL_ 724 VCU_ExtTrqSource_Stat 0 "Default(No ext torque intervention)" 1 "ESC intervention" 2 "ADAS intervention" 3 "Reserved" ;
VAL_ 933 EMS_MinCurrentStaty 1023 "Init" ;
VAL_ 933 EMS_MaxCurrentStaty 1023 "Init" ;
VAL_ 933 EMS_MaxTorque 1023 "Init" ;
VAL_ 933 EMS_MinTorque 1023 "Init" ;
VAL_ 141 EMS_DesEMotorTorque 16383 "Init" ;
VAL_ 141 EMS_DesInvMode 15 "Init" 1 "TorqueControl" 0 "Standby" ;
VAL_ 593 DownwardPosReq 1 "Lower suspension position request" 0 "No request" ;
VAL_ 593 DrivingMode_Sig 4 "Signal failure" 3 "All Road mode" 2 "Comfort mode" 1 "Sport mode" 0 "Auto mode" ;
VAL_ 593 DMS_ServiceMode 1 "Request" 0 "No Request" ;
VAL_ 593 DMS_HDC_Req 1 "Request" 0 "No Request" ;
VAL_ 593 UpwardPosReq 1 "Upper suspension position request " 0 "No request" ;
VAL_ 242 SCU_RightFrHeight 255 "Fault value" ;
VAL_ 242 SCU_LeftRearHeight 255 "Fault value" ;
VAL_ 242 SCU_RightRearHeight 255 "Fault value" ;
VAL_ 242 SCU_LeftFrHeight 255 "Fault value" ;
VAL_ 902 mLEDR_LowBeam_Stat 6 "Error" 5 "Emergency On" 4 "On W" 3 "On E" 2 "On V" 1 "On C" 0 "Off" ;
VAL_ 902 mLEDR_Voltage_Stat 2 "High Voltage (>16V)" 1 "Low Voltage (< 9V)" 0 "Normal Voltage" ;
VAL_ 902 mLEDR_SteeringAngActual_Val 40 "10 and more degrees right" 39 "9.5 degrees right" 38 "9 degrees right" 37 "8.5 degrees right" 36 "8 degrees right" 35 "7.5 degrees right" 34 "7 degrees right" 33 "6.5 degrees right" 32 "6 degrees right" 31 "5.5 degrees right" 30 "5 degrees right" 29 "4.5 degrees right" 28 "4 degrees right" 27 "3.5 degrees right" 26 "3 degrees right" 25 "2.5 degrees right" 24 "2 degrees right" 23 "1.5 degrees right" 22 "1 degrees right" 21 "0.5 degrees right" 20 "Zero position" 19 "0.5 degrees left" 18 "1 degrees left" 17 "1.5 degrees left" 16 "2 degrees left" 15 "2.5 degrees left" 14 "3 degrees left" 13 "3.5 degrees left" 12 "4 degrees left" 11 "4.5 degrees left" 10 "5 degrees left" 9 "5.5 degrees left" 8 "6 degrees left" 7 "6.5 degrees left" 6 "7 degrees left" 5 "7.5 degrees left" 4 "8 degrees left" 3 "8.5 degrees left" 2 "9 degrees left" 1 "9.5 degrees left" 0 "10 and more degrees left" ;
VAL_ 902 mLEDR_HighBeam_Stat 4 "Error" 3 "On boost" 2 "On auto" 1 "On full" 0 "Off" ;
VAL_ 902 mLEDR_Temp_Val 255 "Error" ;
VAL_ 902 mLEDR_FaultCount_Val 2 "Critical" 1 "Not critical" 0 "No detect" ;
VAL_ 901 mLEDL_HighBeam_Stat 4 "Error" 3 "On boost" 2 "On auto" 1 "On manual" 0 "Off" ;
VAL_ 901 mLEDL_SteeringAngActual_Val 40 "10 and more degrees right" 39 "9.5 degrees right" 38 "9 degrees right" 37 "8.5 degrees right" 36 "8 degrees right" 35 "7.5 degrees right" 34 "7 degrees right" 33 "6.5 degrees right" 32 "6 degrees right" 31 "5.5 degrees right" 30 "5 degrees right" 29 "4.5 degrees right" 28 "4 degrees right" 27 "3.5 degrees right" 26 "3 degrees right" 25 "2.5 degrees right" 24 "2 degrees right" 23 "1.5 degrees right" 22 "1 degrees right" 21 "0.5 degrees right" 20 "Zero position" 19 "0.5 degrees left" 18 "1 degrees left" 17 "1.5 degrees left" 16 "2 degrees left" 15 "2.5 degrees left" 14 "3 degrees left" 13 "3.5 degrees left" 12 "4 degrees left" 11 "4.5 degrees left" 10 "5 degrees left" 9 "5.5 degrees left" 8 "6 degrees left" 7 "6.5 degrees left" 6 "7 degrees left" 5 "7.5 degrees left" 4 "8 degrees left" 3 "8.5 degrees left" 2 "9 degrees left" 1 "9.5 degrees left" 0 "10 and more degrees left" ;
VAL_ 901 mLEDL_LowBeam_Stat 6 "Error" 5 "Emergency On" 4 "On W" 3 "On E" 2 "On V" 1 "On C" 0 "Off" ;
VAL_ 901 mLEDL_Voltage_Stat 2 "High Voltage (>16V)" 1 "Low Voltage (< 9V)" 0 "Normal Voltage" ;
VAL_ 901 mLEDL_Temp_Val 255 "Error" ;
VAL_ 901 mLEDL_FaultCount_Val 2 "Critical" 1 "Not critical" 0 "No detect" ;
VAL_ 583 TM_CoolingBox_Stat 3 "Normal 9°C" 2 "Soft 5°C" 1 "Off" 0 "Reserved" ;
VAL_ 583 TM_T30spec_Stat 1 "Terminal on" 0 "Terminal off" ;
VAL_ 583 TM_FuelLidOpen_Req 1 "Fuel lid open request" 0 "No  request" ;
VAL_ 583 TM_TrunkLatch_Stat 3 "Open" 2 "Secondary position" 1 "Primary position" 0 "Unknown" ;
VAL_ 583 TM_LicensePlateLight_State 2 "License Plate Lamp Failure" 1 "Lamps Active" 0 "Lamps inactive" ;
VAL_ 583 TM_TrailerConnect_Stat 1 "Connected" 0 "Not Connected" ;
VAL_ 583 TM_LockAndCloseSW_Req 1 "Close&LockReq" 0 "No_Request" ;
VAL_ 583 TM_Comm_Req 1 "WakeUp_Request" 0 "No_Request" ;
VAL_ 583 TM_BrakeLightHM_Status 1 "HighMount brake light failure" 0 "No failure" ;
VAL_ 583 TM_RearWindowHeating_Stat 1 "Heating ON" 0 "Heating OFF" ;
VAL_ 583 TM_WarningInd 1 "Warning_Active" 0 "No_Warning" ;
VAL_ 583 TM_RearCushion_State 4 "Stopped" 3 "Closing" 2 "Opening" 1 "Closed" 0 "Open" ;
VAL_ 583 TM_FuelLid_Stat 1 "HV lid opened" 0 "Lid closed" ;
VAL_ 583 TM_ExtTrunkSW_Req 1 "TrunkOpenReq" 0 "No_Request" ;
VAL_ 583 TM_IntTrunkSW_Req 1 "TrunkOpenReq" 0 "No_Request" ;
VAL_ 583 TM_Kick_Req 1 "KickReqActive" 0 "No_Request" ;
VAL_ 900 TLR_Voltage_Stat 2 "High Voltage (>16V)" 1 "Low Voltage (< 9V)" 0 "Normal Voltage" ;
VAL_ 900 TLR_Temp_Val 255 "Error" ;
VAL_ 900 TLR_ReverseLgt_Stat 3 "Reserved" 2 "Error" 1 "On" 0 "Off" ;
VAL_ 900 TLR_TurnInd_Stat 3 "Reserved" 2 "Error" 1 "On" 0 "Off" ;
VAL_ 900 TLR_PositionLgt_Stat 3 "Reserved" 2 "Error" 1 "On" 0 "Off" ;
VAL_ 900 TLR_BrakeLgt_Stat 3 "Reserved" 2 "Error" 1 "On" 0 "Off" ;
VAL_ 900 TLR_RearFogLgt_Stat 3 "Reserved" 2 "Error" 1 "On" 0 "Off" ;
VAL_ 899 TLL_Temp_Val 255 "Error" ;
VAL_ 899 TLL_Voltage_Stat 2 "High Voltage (>16V)" 1 "Low Voltage (< 9V)" 0 "Normal Voltage" ;
VAL_ 899 TLL_BrakeLgt_Stat 3 "Reserved" 2 "Error" 1 "On" 0 "Off" ;
VAL_ 899 TLL_TurnInd_Stat 3 "Reserved" 2 "Error" 1 "On" 0 "Off" ;
VAL_ 899 TLL_ReverseLgt_Stat 3 "Reserved" 2 "Error" 1 "On" 0 "Off" ;
VAL_ 899 TLL_PositionLgt_Stat 3 "Reserved" 2 "Error" 1 "On" 0 "Off" ;
VAL_ 899 TLL_RearFogLgt_Stat 3 "Reserved" 2 "Error" 1 "On" 0 "Off" ;
VAL_ 177 TCU_VehicleSpeed_ValueError 1 "Invalid value in vehicle speed signal" 0 "Valid value in vehicle speed signal" ;
VAL_ 177 stGbxMILReq 3 "Default" 2 "Not Available" 1 "MIL ON" 0 "MIL OFF" ;
VAL_ 177 TCU_DriverBrakeReq 1 "Brake pedal requested" 0 "No Request" ;
VAL_ 177 stGearLvr 7 "Default" 6 "Not available" 5 "undefined" 4 "D" 3 "N" 2 "R" 1 "P" 0 "Error" ;
VAL_ 177 gearChangeSPDphase 1 "not changing" 0 "changing" ;
VAL_ 177 numGearEngaged 15 "Default" 14 "Unavailable" 13 "Undefined" 12 "Undefined" 11 "Undefined" 10 "Reverse" 9 "Ninth gear" 8 "Eight gear" 7 "Seventh gear" 6 "Sixth gear" 5 "Fifth gear" 4 "Fourth gear" 3 "Third gear" 2 "Second gear" 1 "First gear" 0 "Neutral" ;
VAL_ 177 stManualGbxMode 1 "Manual" 0 "Auto" ;
VAL_ 177 stTransmissionWarnings 15 "Default" 14 "Not available" 13 "Undefined" 12 "Undefined" 11 "Undefined" 10 "Undefined" 9 "Undefined" 8 "Undefined" 7 "Undefined" 6 "Drive to stop" 5 "Limited functionality" 4 "No failures" 3 "Critical Failure" 2 "Reserved" 1 "Overheat" 0 "Reserved" ;
VAL_ 177 numGearTarget 15 "Default" 14 "Unavailable" 13 "Undefined" 12 "Undefined" 11 "Undefined" 10 "Reverse" 9 "Ninth gear" 8 "Eight gear" 7 "Seventh gear" 6 "Sixth gear" 5 "Fifth gear" 4 "Fourth gear" 3 "Third gear" 2 "Second gear" 1 "First gear" 0 "Neutral" ;
VAL_ 177 stGearboxMode 7 "Default" 6 "Not available" 5 "Undefined" 4 "All Season" 3 "Auto" 2 "Comfort" 1 "Sport" 0 "Error" ;
VAL_ 177 bShiftInProgress 1 "Shift in progress" 0 "Not shifting" ;
VAL_ 568 SWM_VolumeMute_Req 3 "Failure" 2 "Pressed" 1 "Released" 0 "Reserved" ;
VAL_ 568 SWM_VolumeDownBtn_Req 3 "Failure" 2 "Pressed" 1 "Released" 0 "Reserved" ;
VAL_ 568 SWM_VolumeUpBtn_Req 3 "Failure" 2 "Pressed" 1 "Released" 0 "Reserved" ;
VAL_ 568 SWM_VoiceCntrl_Req 3 "Failure" 2 "Pressed" 1 "Released" 0 "Reserved" ;
VAL_ 568 SWM_MMCPrevBtn_Req 3 "Failure" 2 "Pressed" 1 "Released" 0 "Reserved" ;
VAL_ 568 SWM_MMCNextBtn_Req 3 "Failure" 2 "Pressed" 1 "Released" 0 "Reserved" ;
VAL_ 568 SWM_MODE_Req 3 "Failure" 2 "Pressed" 0 "Reserved" 1 "Released" ;
VAL_ 568 SWM_CNCL_Req 3 "Failure" 2 "Pressed" 0 "Reserved" 1 "Released" ;
VAL_ 568 SWM_DIS_Req 3 "Failure" 2 "Pressed" 0 "Reserved" 1 "Released" ;
VAL_ 568 SWM_RES_Req 3 "Failure" 2 "Pressed" 0 "Reserved" 1 "Released" ;
VAL_ 568 SWM_UserFunc_Req 3 "Failure" 2 "Pressed" 0 "Reserved" 1 "Released" ;
VAL_ 568 SWM_ACCSpeedDecrease_Req 3 "Failure" 2 "Pressed" 0 "Reserved" 1 "Released" ;
VAL_ 568 SWM_ACCSpeedIncrease_Req 3 "Failure" 2 "Pressed" 0 "Reserved" 1 "Released" ;
VAL_ 568 SWM_SETSpeed_Req 3 "Failure" 2 "Pressed" 0 "Reserved" 1 "Released" ;
VAL_ 568 SWM_TELBtn_Req 3 "Failure" 2 "Pressed" 0 "Reserved" 1 "Released" ;
VAL_ 568 SWM_Home_Req 3 "Failure" 2 "Pressed" 0 "Reserved" 1 "Released" ;
VAL_ 568 SWM_Back_Req 3 "Failure" 2 "Pressed" 0 "Reserved" 1 "Released" ;
VAL_ 568 SWM_ICNextBtn_Req 3 "Failure" 2 "Pressed" 0 "Reserved" 1 "Released" ;
VAL_ 568 SWM_ICPrevBtn_Req 3 "Failure" 2 "Pressed" 0 "Reserved" 1 "Released" ;
VAL_ 568 SWM_ICUpBtn_Req 3 "Failure" 2 "Pressed" 0 "Reserved" 1 "Released" ;
VAL_ 568 SWM_ICDownBtn_Req 3 "Failure" 2 "Pressed" 0 "Reserved" 1 "Released" ;
VAL_ 568 SWM_ICConfBtn_Req 3 "Failure" 2 "Pressed" 0 "Reserved" 1 "Released" ;
VAL_ 568 SWM_UpshiftPaddle_Req 3 "Failure" 2 "Pressed" 0 "Reserved" 1 "Released" ;
VAL_ 568 SWM_DownshiftPaddle_Req 3 "Failure" 2 "Pressed" 0 "Reserved" 1 "Released" ;
VAL_ 568 SWM_PosHand_Stat 1 "Not on steereng wheel" 0 "On steering wheel" 3 "Failure" 2 "On steering wheel" ;
VAL_ 688 SAS_CAL_Stat 1 "sensor calibrated" 0 "Sensor not calibrated" ;
VAL_ 688 SAS_TRIM_Stat 1 "sensor trimmer" 0 "Sensor not trimmed" ;
VAL_ 688 SAS_Angle 32767 "Fault value" ;
VAL_ 688 SAS_OK_Stat 1 "sensor information valid" 0 "sensor information invalid, internal sensor fault" ;
VAL_ 688 SAS_Speed 255 "Fault value" ;
VAL_ 904 RLR_PositionLgt_Stat 2 "Error" 1 "On" 0 "Off" ;
VAL_ 904 RLR_ReverseLgt_Stat 2 "Error" 1 "On" 0 "Off" ;
VAL_ 904 RLR_Temp_Val 255 "Error" ;
VAL_ 904 RLR_BrakeLgt_Stat 2 "Error" 1 "On" 0 "Off" ;
VAL_ 904 RLR_TurnInd_Stat 2 "Error" 1 "On" 0 "Off" ;
VAL_ 904 RLR_Voltage_Stat 2 "High Voltage (>16V)" 1 "Low Voltage (< 9V)" 0 "Normal Voltage" ;
VAL_ 904 RLR_RearFogLgt_Stat 2 "Error" 1 "On" 0 "Off" ;
VAL_ 903 RLL_BrakeLgt_Stat 2 "Error" 1 "On" 0 "Off" ;
VAL_ 903 RLL_Temp_Val 255 "Error" ;
VAL_ 903 RLL_PositionLgt_Stat 2 "Error" 1 "On" 0 "Off" ;
VAL_ 903 RLL_ReverseLgt_Stat 2 "Error" 1 "On" 0 "Off" ;
VAL_ 903 RLL_TurnInd_Stat 2 "Error" 1 "On" 0 "Off" ;
VAL_ 903 RLL_RearFogLgt_Stat 2 "Error" 1 "On" 0 "Off" ;
VAL_ 903 RLL_Voltage_Stat 2 "High Voltage (>16V)" 1 "Low Voltage (< 9V)" 0 "Normal Voltage" ;
VAL_ 976 MAS_ParkingOutSuccess_Stat 0 "Parking Out is not executed" 1 "Parking Out is Successful" ;
VAL_ 976 MAS_ParkingOutAvailable_Stat 0 "AutoParkOut not available" 1 "AutoParkOut is available" ;
VAL_ 976 MAS_APAMode_Stat 0 "APA is not active" 1 "Init" 2 "Search" 3 "Search paused" 4 "Select" 5 "Move" 6 "Move paused" 7 "Fatal Error" ;
VAL_ 976 MAS_APAManeuverSuccess_Stat 0 "Not started or not success" 1 "Success" ;
VAL_ 976 MAS_AVMUltrasonicSide_Stat 2 "Sensor error" 1 "Dirt or blocked" 0 "Available" ;
VAL_ 976 MAS_AVMUltrasonicRear_Stat 2 "Sensor error" 1 "Dirt or blocked" 0 "Available" ;
VAL_ 976 MAS_AVMUltrasonicFront_Stat 2 "Sensor error" 1 "Dirt or blocked" 0 "Available" ;
VAL_ 976 MAS_AVMCameraRightSide_Stat 1 "Error" 0 "Not Error" ;
VAL_ 976 MAS_AVMCameraLeftSide_Stat 1 "Error" 0 "Not Error" ;
VAL_ 976 MAS_AVMCameraRear_Stat 1 "Error" 0 "Not Error" ;
VAL_ 976 MAS_AVMCameraFront_Stat 1 "Error" 0 "Not Error" ;
VAL_ 976 MAS_AVMUltraSonic_Stat 1 "Active" 0 "Inactive" ;
VAL_ 976 MAS_AVMNarrowMode_Stat 2 "Narrow" 1 "Wide (full)" 0 "Nothing" ;
VAL_ 976 MAS_AVMAutoAct_Stat 1 "Automatic activation OFF" 0 "Automatic activation ON" ;
VAL_ 976 MAS_MASmode_Stat 4 "Error" 3 "Not avaliable" 2 "APA" 1 "AVM" 0 "MAS not requested" ;
VAL_ 976 MAS_View_Stat 7 "Parking View" 6 "3D Free View (Rotation)" 5 "3D Right" 4 "3D Left" 3 "3D Main (Rear Top View)" 2 "2D Rear" 1 "2D Front" 0 "Nothing" ;
VAL_ 976 MAS_Calibration_Stat 1 "Calibration started" 0 "Calibration not started" ;
VAL_ 320 DAS_LeftLaneLDWWarning_Req 0 "No Warning requested" 1 "Warning requested" ;
VAL_ 320 DAS_RightLaneLDWWarning_Req 0 "No Warning requested" 1 "Warning requested" ;
VAL_ 320 DAS_SPLimRoadSignInf1_Stat 12 "Stop sign" 11 "Crosswalk sign" 10 "Yield sign" 9 "Right of way" 8 "Speed bump" 7 "Pedestrian crossing" 6 "End of all previous prohibitions" 5 "No Entry" 4 "End Of Speed limit" 3 "Speed limit" 2 "End of prohibition for overtake" 0 "No Road Sign" 1 "No Overtaking" ;
VAL_ 320 DAS_SPLimRoadSignInf2_Stat 12 "Stop sign" 11 "Crosswalk sign" 10 "Yield sign" 9 "Right of way" 8 "Speed bump" 7 "Pedestrian crossing" 6 "End of all previous prohibitions" 5 "No Entry" 4 "End Of Speed limit" 3 "Speed limit" 2 "End of prohibition for overtake" 0 "No Road Sign" 1 "No Overtaking" ;
VAL_ 320 DAS_SPLimRoadSignInf3_Stat 12 "Stop sign" 11 "Crosswalk sign" 10 "Yield sign" 9 "Right of way" 8 "Speed bump" 7 "Pedestrian crossing" 6 "End of all previous prohibitions" 5 "No Entry" 4 "End Of Speed limit" 3 "Speed limit" 2 "End of prohibition for overtake" 0 "No Road Sign" 1 "No Overtaking" ;
VAL_ 320 DAS_RoadSignAddressing_Stat 2 "Road Sign List 3 Addressed" 0 "Road Sign List 1 Addressed" 1 "Road Sign List 2 Addressed" ;
VAL_ 320 DAS_RoadLaneAddressing_Stat 0 " Left Road Side" 1 " Right Road Side" ;
VAL_ 777 DAS_ACCSetDistance_Stat 0 "Close distance" 1 "Normal distance" 2 "Long away" ;
VAL_ 777 DAS_ACCResDistance_Stat 2 "Long away" 0 "Close distance" 1 "Normal distance" ;
VAL_ 777 DAS_ACCtargetDetected_Stat 0 "Target not detected" 1 "Target detected" ;
VAL_ 746 IC_RSRFuncEnable 1 "Enable" 0 "Disable" ;
VAL_ 746 IC_LDWFuncEnable 1 "Enable" 0 "Disable" ;
VAL_ 746 IC_VisualAct_Req 1 "Requested" 0 "Not requested" ;
VAL_ 746 IC_NvAct_Req 1 "Requested" 0 "Not requested" ;
VAL_ 746 IC_DistBar_Stat 1 "Active" 0 "Inactive" ;
VAL_ 275 CddTempOff 1 "CDD OFF due to brake Temperature" 0 "CDD ON" ;
VAL_ 275 AbpActive 1 "Active" 0 "Inactive" ;
VAL_ 275 AebAvailable 1 "Available" 0 "Not Available" ;
VAL_ 275 CddAvailable 1 "Available" 0 "Not Available" ;
VAL_ 275 CddSkiddingDetected 1 "Skidding Detected" 0 "No Skidding" ;
VAL_ 275 CddVehicleStandstill 1 "Standstill by CDD ON" 0 "Standstill by CDD OFF" ;
VAL_ 275 CddFailure 1 "Failure" 0 "No Failure" ;
VAL_ 275 CddActive 1 "Active" 0 "Inactive" ;
VAL_ 275 AbpAvailable 1 "Available" 0 "Not Available" ;
VAL_ 275 BrakeJerkApplied 1 "BrakeJerk Applied" 0 "BrakeJerk Not Applied" ;
VAL_ 274 ESC_BrakePressureMC_Val 4095 "Error" ;
VAL_ 273 ESC_pWheelRR_Val 32767 "Fault value" ;
VAL_ 273 ESC_pWheelRL_Val 32767 "Fault value" ;
VAL_ 272 ESC_ATCTrqRq_Val 65535 "Error" ;
VAL_ 272 ESC_ATCMode_Req 7 "Error" 3 "Fast open request" 2 "Limit maximum" 1 "Limit minimum" 0 "No intervention" ;
VAL_ 272 ESC_pWheelFR_Val 32767 "Fault value" ;
VAL_ 272 ESC_pWheelFL_Val 32767 "Fault value" ;
VAL_ 164 EMS_bPowertrainSignalSpdErr 1 "Error present" 0 "No error" ;
VAL_ 164 EMS_nICEngineSpeed1 65535 "Error value" ;
VAL_ 164 EMS_bICEngineFCO 1 "Engine in fuel cut-off" 0 "Engine fueled" ;
VAL_ 163 EMS_bAccPedSensorFail 1 "Failure" 0 "No Failure" ;
VAL_ 163 EMS_stKickDown 3 "default" 2 "not used" 1 "kickdown active" 0 "no kickdown" ;
VAL_ 163 EMS_ratAccPed_Stat 1 "Fault" 0 "No fault" ;
VAL_ 163 EMS_bPwrTrnTorqueEstErr 1 "Error" 0 "No Error" ;
VAL_ 1292 IC_Speed 511 "Fault value" ;
VAL_ 1293 IC_DMS_Calibration_Stat 2 "Calibration done" 1 "Calibration process" 0 "No calibration" ;
VAL_ 1293 IC_EyeClosed_Stat 1 "Closed" 0 "Opened" ;
VAL_ 1293 IC_FaceRecognition_Stat 1 "Face recognized" 0 "Face not recognized" ;
VAL_ 1293 IC_GazeOther_Stat 1 "Focused" 0 "Not-Focused" ;
VAL_ 1293 IC_LvlFatigues_Stat 3 "Sleep" 2 "Drowsy" 1 "Questionable" 0 "Awake" ;
VAL_ 1293 IC_DataReliability_Stat 1 "Mouth found" 0 "Mouth not found" ;
VAL_ 1293 IC_LvlDistractions_Stat 2 "High Risk" 1 "Medium Risk" 0 "No Risk" ;
VAL_ 1293 IC_GazeFront_Stat 1 "Focused" 0 "Not-focused" ;
VAL_ 1293 IC_GazeleftSide_Stat 1 "Focused" 0 "Not-focused" ;
VAL_ 1293 IC_ViewRoadSide_Stat 1 "Focused" 0 "Not-Focused" ;
VAL_ 1293 IC_GazeRightSide_Stat 1 "Focused" 0 "Not-Focused" ;
VAL_ 743 IC_AbsoluteDateAndTime -1 "Fault value" ;
VAL_ 898 HLR_DayRunningLgt_Stat 2 "Error" 1 "On" 0 "Off" ;
VAL_ 898 HLR_Temp_Val 255 "Error" ;
VAL_ 898 HLR_CorrectorActual_Val 255 "Reserved" 127 "Zero level" 0 "No change" ;
VAL_ 898 HLR_HighBeam_Stat 4 "Error" 3 "On boost" 2 "On auto" 1 "On full" 0 "Off" ;
VAL_ 898 HLR_Voltage_Stat 2 "High Voltage (>16V)" 1 "Low Voltage (< 9V)" 0 "Normal Voltage" ;
VAL_ 898 HLR_RightCorneringLgt_Stat 2 "Error" 1 "On" 0 "Off" ;
VAL_ 898 HLR_TurnIndRight_Stat 2 "Error" 1 "On" 0 "Off" ;
VAL_ 898 HLR_LowBeam_Stat 6 "Error" 5 "Emergency On" 4 "On W" 3 "On E" 2 "On V" 1 "On C" 0 "Off" ;
VAL_ 898 HLR_PositionLgt_Stat 2 "Error" 1 "On" 0 "Off" ;
VAL_ 897 HLL_LowBeam_Stat 6 "Error" 5 "Emergency On" 4 "On W" 3 "On E" 2 "On V" 1 "On C" 0 "Off" ;
VAL_ 897 HLL_DayRunningLgt_Stat 2 "Error" 1 "On" 0 "Off" ;
VAL_ 897 HLL_CorrectorActual_Val 255 "Reserved" 127 "Zero level" 0 "No change" ;
VAL_ 897 HLL_Temp_Val 255 "Error" ;
VAL_ 897 HLL_Voltage_Stat 2 "High Voltage (>16V)" 1 "Low Voltage (< 9V)" 0 "Normal Voltage" ;
VAL_ 897 HLL_TurnIndLeft_Stat 2 "Error" 1 "On" 0 "Off" ;
VAL_ 897 HLL_PositionLgt_Stat 2 "Error" 1 "On" 0 "Off" ;
VAL_ 897 HLL_HighBeam_Stat 4 "Error" 3 "On Boost" 2 "On auto" 1 "On full" 0 "Off" ;
VAL_ 897 HLL_LeftCorneringLgt_Stat 2 "Error" 1 "On" 0 "Off" ;
VAL_ 1428 FIU_FR_Synx_Req 2 "No synx" 1 "Synx" 0 "No change" ;
VAL_ 1428 FIU_FL_Synx_Req 2 "No synx" 1 "Synx" 0 "No change" ;
VAL_ 1428 FIU_ReduceChrgCurr_Stat 0 "Inactive" 1 "Active" ;
VAL_ 1428 FIU_SchedWed_Stat 0 "Inactive" 1 "Active" ;
VAL_ 1428 FIU_SchedTue_Stat 0 "Inactive" 1 "Active" ;
VAL_ 1428 FIU_SchedThu_Stat 0 "Inactive" 1 "Active" ;
VAL_ 1428 FIU_SchedSu_Stat 0 "Inactive" 1 "Active" ;
VAL_ 1428 FIU_SchedStart_Stat 0 "Inactive" 1 "Active" ;
VAL_ 1428 FIU_SchedSat_Stat 0 "Inactive" 1 "Active" ;
VAL_ 1428 FIU_SchedMon_Stat 0 "Inactive" 1 "Active" ;
VAL_ 1428 FIU_SchedFri_Stat 0 "Inactive" 1 "Active" ;
VAL_ 1428 FIU_SchedEnd_Stat 0 "Inactive" 1 "Active" ;
VAL_ 1428 FIU_PrepearClim_Stat 0 "Inactive" 1 "Active" ;
VAL_ 1428 FIU_ProjectionLiveObj_Req 1 "Active" 0 "Inactive" ;
VAL_ 1428 FIU_ProjectionNavigation_Req 0 "Inactive" 1 "Active" ;
VAL_ 1428 FIU_ProjectionRoadSigns_Req 1 "Active" 0 "Inactive" ;
VAL_ 1428 FIU_ProjectionOnRoad_Req 1 "Active" 0 "Inactive" ;
VAL_ 1428 FIU_RR_Synx_Req 2 "No synx" 1 "Synx" 0 "No change" ;
VAL_ 1428 FIU_RL_Synx_Req 2 "No synx" 1 "Synx" 0 "No change" ;
VAL_ 1428 FIU_ICimage_Req 3 "Image 3" 2 "Image 2" 1 "Image 1" 0 "No action" ;
VAL_ 1428 FIU_RearSideWindowsElcrome_Req 3 "Strong" 2 "Medium" 1 "Soft" 0 "No action" ;
VAL_ 1428 FIU_ArmrestHeatFL_Req 1 "Active" 0 "Inactive" ;
VAL_ 1428 FIU_ArmrestHeatRL_Req 1 "Active" 0 "Inactive" ;
VAL_ 1428 FIU_ArmrestHeatFR_Req 1 "Active" 0 "Inactive" ;
VAL_ 1428 FIU_ArmrestHeatRR_Req 1 "Active" 0 "Inactive" ;
VAL_ 464 RSA_Torque_Val 255 "Fault value" ;
VAL_ 464 RSA_Fault_Stat 1 "Fault" 0 "No fault" ;
VAL_ 464 RSA_ExternalControl_Stat 1 "RSA under external control" 0 "No external control" ;
VAL_ 464 RSA_Enable_Stat 1 "Enable" 0 "Disable" ;
VAL_ 464 RSA_Angle_Val 255 "Fault value" ;
VAL_ 1424 ERAG_Status 31 "undefined" 30 "not_used" 19 "..." 18 "not_used" 17 "not_initialized" 16 "incoming_call" 15 "MSD_sends" 14 "sleep_pin" 13 "enable_sleep" 12 "dial" 11 "call_preparation" 10 "registration" 9 "SERV_comm" 8 "SOS_comm" 7 "testing_sound condition" 6 "testing_other" 5 "testing_w3" 4 "testing_w2" 3 "testing_w1" 2 "sleep" 1 "idle" 0 "initializing" ;
VAL_ 1424 ERAG_FailureSts 6 "Full Failure" 5 "Unavailable GSM/GPRS" 4 "Unavailable GPS" 3 "Unavailable SOS button" 2 "Unavailable speaker" 1 "Unavailable microphone" 0 "No Failure" ;
VAL_ 1424 ERAG_MuteReq 1 "Mute Active" 0 "Mute Inactive" ;
VAL_ 538 EPB_BrakeLight_Req 1 "Request" 0 "No request" ;
VAL_ 538 EPB_AppliedForce_Stat 3 "Maximum force applied" 2 "Medium force applied" 1 "Low force applied" 0 "No force applied" ;
VAL_ 538 EPB_Failure_Stat 1 "Failure" 0 "No Failure" ;
VAL_ 538 EPB_CurrParkBrake_Stat 5 "Reserved" 4 "Engagement under Progress" 3 "Release Under Progress" 2 "Engaged" 1 "Released" 0 "Not Initialized" ;
VAL_ 538 EPB_CurrEPBSw_Stat 3 "Fault" 2 "Lock Brake" 1 "Release Brake" 0 "No Request" ;
VAL_ 538 EPB_AudibleChime_Req 1 "Request" 0 "No Request" ;
VAL_ 538 EPB_Indicator_Req 3 "Failure Indication" 2 "Dynamic Braking Indication" 1 "Engaged Brake Indication" 0 "No Indication" ;
VAL_ 538 EPB_DynamicEmergencyApply_Stat 1 "Enabled" 0 "Not Enabled" ;
VAL_ 582 DMRR_DoorCloseSw_Req 1 "External Door Close request" 0 "No Req" ;
VAL_ 582 DMRR_DoorDirection_Stat 2 "Closing" 1 "Opening" 0 "Stopped" ;
VAL_ 582 DMRR_ChildLock_Stat 2 "Error" 1 "Locked" 0 "Unlocked" ;
VAL_ 582 DMRR_DoorMovement_Stat 4 "Fault" 3 "Fully open" 2 "Intermediate" 1 "Fully closed" 0 "Unknown" ;
VAL_ 582 DMRR_RearCurtain_Req 1 "Short pressed" 0 "Not requested" 2 "Long pressed" ;
VAL_ 582 DMRR_IntDoorHandle_Req 1 "Requested" 0 "No request" ;
VAL_ 582 DMRR_WarningInd 1 "Warning_Active" 0 "No_Warning" ;
VAL_ 582 DMRR_VolumeLevel_Cmd 3 "Short Press (Mute Req - Volume Off)" 2 "Decrease sound" 1 "Increase sound" 0 "No request" 4 "Long Press (Voice Assist Req)" ;
VAL_ 582 DMRR_WindowFullyClosed_Stat 1 "Window fully closed" 0 "Window not fully closed" ;
VAL_ 582 DMRR_Comm_Req 1 "Requested" 0 "Not requested" ;
VAL_ 582 DMRR_ElcromeBright_Stat 3 "Strong Dimmming" 2 "Medium Dimming" 1 "Soft Dimming" 0 "Dimming switched off" ;
VAL_ 582 DMRR_DoorLockState 2 "Fault" 1 "Door_Locked" 0 "Door Unlocked" ;
VAL_ 582 DMRR_Multimedia_Req 2 "MMS ON/OFF requested" 1 "Mute ON/OFF requested" 0 "Not requested" ;
VAL_ 582 DMRR_Antipinch_Stat 1 "Pinch detected" 0 "Pinch not detected" ;
VAL_ 582 DMRR_RL_Window_Cmd 4 "Auto up" 3 "Auto down" 2 "Manual up" 1 "Manual down" 0 "No action" ;
VAL_ 582 DMRR_IntDoorLockSw_Cmd 2 "Lock requested" 1 "Unlock requested" 0 "No requested" ;
VAL_ 582 DMRR_SunShade_Stat 4 "Stopped" 3 "Closing" 2 "Opening" 1 "Closed" 0 "Open" ;
VAL_ 582 DMRR_DoorAjarState 1 "Door_Close" 0 "Door_Open" ;
VAL_ 582 DMRR_DoorAjarFault_Stat 1 "Fault detect" 0 "No fault detect" ;
VAL_ 581 DMRL_DoorCloseSw_Req 1 "External Door Close request" 0 "No Req" ;
VAL_ 581 DMRL_WindowFullyClosed_Stat 1 "Window fully closed" 0 "Window not fully closed" ;
VAL_ 581 DMRL_ChildLock_Stat 2 "Error" 1 "Locked" 0 "Unlocked" ;
VAL_ 581 DMRL_IntDoorHandle_Req 1 "Requested" 0 "No request" ;
VAL_ 581 DMRL_IntDoorLockSw_Cmd 2 "Lock requested" 1 "Unlock requested" 0 "No requested" ;
VAL_ 581 DMRL_DoorLockState 2 "Fault" 1 "Door_Locked" 0 "Door Unlocked" ;
VAL_ 581 DMRL_ElcromeBright_Stat 3 "Strong Dimmming" 2 "Medium Dimming" 1 "Soft Dimming" 0 "Dimming switched off" ;
VAL_ 581 DMRL_DoorMovement_Stat 4 "Fault" 3 "Fully open" 2 "Intermediate" 1 "Fully closed" 0 "Unknown" ;
VAL_ 581 DMRL_RR_Window_Cmd 4 "Auto up" 3 "Auto down" 2 "Manual up" 1 "Manual down" 0 "No action" ;
VAL_ 581 DMRL_RearCurtain_Req 1 "Short pressed" 0 "Not requested" 2 "Long pressed" ;
VAL_ 581 DMRL_DoorDirection_Stat 2 "Closing" 1 "Opening" 0 "Stopped" ;
VAL_ 581 DMRL_Antipinch_Stat 1 "Pinch detected" 0 "Pinch not detected" ;
VAL_ 581 DMRL_WarningInd 1 "Warning_Active" 0 "No_Warning" ;
VAL_ 581 DMRL_VolumeLevel_Cmd 4 "Long Press (Voice Assist Req)" 3 "Short Press (Mute Req - Volume Off)" 2 "Decrease Volume" 1 "Increase Volume" 0 "No Request" ;
VAL_ 581 DMRL_Multimedia_Req 2 "MMS ON/OFF requested" 1 "Mute ON/OFF requested" 0 "Not requested" ;
VAL_ 581 DMRL_Comm_Req 1 "Requested" 0 "Not requested" ;
VAL_ 581 DMRL_SunShade_Stat 4 "Stopped" 3 "Closing" 2 "Opening" 1 "Closed" 0 "Open" ;
VAL_ 581 DMRL_DoorAjarState 1 "Door_Close" 0 "Door_Open" ;
VAL_ 581 DMRL_DoorAjarFault_Stat 1 "Fault detect" 0 "No fault detect" ;
VAL_ 579 DMFR_ShortDrop_Stat 0 "Window above short drop point" 1 "Window is in OR below short drop point" ;
VAL_ 579 DMFR_DoorCloseSw_Req 1 "External Door Close request" 0 "No Req" ;
VAL_ 579 DMFR_Comm_Req 1 "Requested" 0 "Not requested" ;
VAL_ 579 DMFR_DoorMovement_Stat 4 "Fault" 3 "Fully open" 2 "Intermediate" 1 "Fully closed" 0 "Unknown" ;
VAL_ 579 DMFR_MirrorHeating_Status 3 "Fault" 2 "Heating off" 1 "Heating on" 0 "Unknown" ;
VAL_ 579 DMFR_Antipinch_Stat 1 "Pinch detected" 0 "Pinch not detected" ;
VAL_ 579 DMFR_IntDoorLockSw_Cmd 2 "Lock requested" 1 "Unlock requested" 0 "No requested" ;
VAL_ 579 DMFR_TurnInd_Stat 2 "Error" 1 "On" 0 "Off" ;
VAL_ 579 DMFR_DoorLockState 2 "Fault" 1 "Door_Locked" 0 "Door Unlocked" ;
VAL_ 579 DMFR_DoorDirection_Stat 2 "Closing" 1 "Opening" 0 "Stopped" ;
VAL_ 579 DMFR_WindowFullyClosed_Stat 1 "Window fully closed" 0 "Window not fully closed" ;
VAL_ 579 DMFR_IntDoorHandle_Req 1 "Requested" 0 "No request" ;
VAL_ 579 DMFR_WarningInd 1 "Warning_Active" 0 "No_Warning" ;
VAL_ 579 DMFR_BSDLed_Stat 1 "Error" 0 "No error" ;
VAL_ 579 DMFR_DoorAjarState 1 "Door_Close" 0 "Door_Open" ;
VAL_ 579 DMFR_DoorAjarFault_Stat 1 "Fault detect" 0 "No fault detect" ;
VAL_ 580 DMFL_ChildLockRRTab_Stat 1 "Function active" 0 "Function inactive" ;
VAL_ 580 DMFL_ChildLockRLTab_Stat 1 "Function active" 0 "Function inactive" ;
VAL_ 580 DMFL_ShortDrop_Stat 0 "Window above short drop point" 1 "Window is in OR below short drop point" ;
VAL_ 580 DMFL_ChildLockCentralTab_Stat 1 "Function active" 0 "Function inactive" ;
VAL_ 580 DMFL_DoorCloseSw_Req 1 "External Door Close request" 0 "No Req" ;
VAL_ 580 DMFL_RightMirrorFold_Cmd 2 "Unfold" 1 "Fold" 0 "No action" ;
VAL_ 580 DMFL_DoorMovement_Stat 4 "Fault" 3 "Fully open" 2 "Intermediate" 1 "Fully closed" 0 "Unknown" ;
VAL_ 580 DMFL_KeyCylinder_Req 3 "Fault" 2 "Lock_Req" 1 "Unlock_Req" 0 "No_Request" ;
VAL_ 580 DMFL_DoorLockState 2 "Fault" 1 "Door_Locked" 0 "Door Unlocked" ;
VAL_ 580 DMFL_RRWindow_Cmd 4 "Auto up" 3 "Auto down" 2 "Manual up" 1 "Manual down" 0 "No action" ;
VAL_ 580 DMFL_ChildLock_RRdoor_Stat 1 "Function active" 0 "Function inactive" ;
VAL_ 580 DMFL_ChildLock_RLwindow_Stat 1 "Function active" 0 "Function inactive" ;
VAL_ 580 DMFL_WindowFullyClosed_Stat 1 "Window fully closed" 0 "Window not fully closed" ;
VAL_ 580 DMFL_ChildLock_RRwindow_Stat 1 "Function active" 0 "Function inactive" ;
VAL_ 580 DMFL_BSDLed_Stat 1 "Error" 0 "No error" ;
VAL_ 580 DMFL_IntDoorHandle_Req 1 "Requested" 0 "No request" ;
VAL_ 580 DMFL_TurnInd_Stat 2 "Error" 1 "On" 0 "Off" ;
VAL_ 580 DMFL_Antipinch_Stat 1 "Pinch detected" 0 "Pinch not detected" ;
VAL_ 580 DMFL_WarningInd 1 "Warning_Active" 0 "No_Warning" ;
VAL_ 580 DMFL_Comm_Req 1 "Requested" 0 "Not requested" ;
VAL_ 580 DMFL_RightMirrorTilt_Cmd 1 "On" 0 "Off" ;
VAL_ 580 DMFL_RLWindow_Cmd 4 "Auto up" 3 "Auto down" 2 "Manual up" 1 "Manual down" 0 "No action" ;
VAL_ 580 DMFL_RearWindowCurtain_Req 1 "Short pressed" 0 "Not requested" 2 "Long pressed" ;
VAL_ 580 DMFL_ChildLock_RLdoor_Stat 1 "Function active" 0 "Function inactive" ;
VAL_ 580 DMFL_RightMirrorAdjust_Cmd 4 "Right" 3 "Left" 2 "Down" 1 "Up" 0 "No action" ;
VAL_ 580 DMFL_ChildLock_Stat 1 "Function active" 0 "Function inactive" ;
VAL_ 580 DMFL_MirrorHeating_Status 3 "Fault" 2 "Heating off" 1 "Heating on" 0 "Unknown" ;
VAL_ 580 DMFL_IntDoorLockSw_Cmd 2 "Lock requested" 1 "Unlock requested" 0 "No requested" ;
VAL_ 580 DMFL_FRWindow_Cmd 4 "Auto up" 3 "Auto down" 2 "Manual up" 1 "Manual down" 0 "No action" ;
VAL_ 580 DMFL_DoorDirection_Stat 2 "Closing" 1 "Opening" 0 "Stopped" ;
VAL_ 580 DMFL_DoorAjarState 1 "Door_Close" 0 "Door_Open" ;
VAL_ 580 DMFL_DoorAjarFault_Stat 1 "Fault detect" 0 "No fault detect" ;
VAL_ 1104 DAS_AslaChSpd_Req 0 "Not requested" ;
VAL_ 1104 DAS_AaError_Stat 1 "Error" 0 "No error" ;
VAL_ 1104 DAS_RcwWarn_Req 1 "Requested" 0 "Not requested" ;
VAL_ 1104 DAS_NvMode_Stat 2 "Active" 1 "Availible" 0 "Not availible" ;
VAL_ 1104 DAS_NvNotifError_Req 1 "Error" 0 "No error" ;
VAL_ 1104 DAS_RecMode_Stat 1 "On" 0 "Off" ;
VAL_ 1104 DAS_TsrMode_Stat 1 "Active" 0 "Off" ;
VAL_ 1104 DAS_TsrSignSpeedType_Stat 20 "Reserved" 19 "Reserved" 18 "Reserved" 17 "CancelSpdLim" 16 "150 kmh" 15 "140 kmh" 14 "130 kmh" 13 "120 kmh" 12 "110 kmh" 11 "100 kmh" 10 "90 kmh" 9 "80 kmh" 8 "70 kmh" 7 "60 kmh" 6 "50 kmh" 5 "40 kmh" 4 "30 kmh" 3 "20 kmh" 2 "10 kmh" 1 "5 kmh" 0 "No sign" ;
VAL_ 1104 DAS_TsrSignOverTakingType_Stat 11 "SecondRoad" 10 "MainRoad" 9 "SpeedBumpNear" 8 "CrosswalkNear" 7 "NoEntry" 6 "Stop" 5 "SpeedBumpFar " 4 "CrossWalkFar" 3 "Cancel all" 2 "Overtaking cancellation" 1 "OverTaking" 0 "Nothing" ;
VAL_ 1104 DAS_RcwMode_Stat 1 "Active" 0 "Off" ;
VAL_ 1104 DAS_AaMode_Stat 2 "Active" 1 "Standby" 0 "Off" ;
VAL_ 1104 DAS_TsrSignError_Stat 1 "Error" 0 "No error" ;
VAL_ 1104 DAS_AaWarnNotif_Req 1 "Requested" 0 "Not requested" ;
VAL_ 1104 DAS_TsrSignNotifError_Req 1 "Active" 0 "Off" ;
VAL_ 523 DAS_LdpNotifError_Req 1 "Error" 0 "No error" ;
VAL_ 523 DAS_ALccNotifError_Req 1 "Error" 0 "No error" ;
VAL_ 523 DAS_LdpRightLaneWarn_Req 1 "Requested" 0 "Not requested" ;
VAL_ 523 DAS_LdpLeftLaneWarn_Req 1 "Requested" 0 "Not requested" ;
VAL_ 523 DAS_LdwLeftLaneWarn_Req 1 "Requested" 0 "Not requested" ;
VAL_ 523 DAS_LkaWarnNotif_Req 1 "Requested" 0 "Not requested" ;
VAL_ 523 DAS_LkaNotifError_Req 1 "Error" 0 "No error" ;
VAL_ 523 DAS_DowMode_Stat 1 "Active" 0 "Off" ;
VAL_ 523 DAS_LccLeftWarn_Req 1 "Requested" 0 "Not requested" ;
VAL_ 523 DAS_LccRightLed_Req 1 "Requested" 0 "Not requested" ;
VAL_ 523 DAS_LdwSound_Req 1 "Requested" 0 "Not requested" ;
VAL_ 523 DAS_RdaNotifError_Req 1 "Error" 0 "No error" ;
VAL_ 523 DAS_LccNotifError_Req 1 "Error" 0 "No error" ;
VAL_ 523 DAS_LkaShootdownSound_Req 1 "Requested" 0 "Not requested" ;
VAL_ 523 DAS_LccSound_Req 1 "Requested" 0 "Not requested" ;
VAL_ 523 DAS_LdwMode_Stat 4 "Active right" 3 "Active left" 2 "Active" 1 "Standby" 0 "Off" ;
VAL_ 523 DAS_LccLeftLed_Req 1 "Requested" 0 "Not requested" ;
VAL_ 523 DAS_LdwNotifError_Req 1 "Error" 0 "No error" ;
VAL_ 523 DAS_DowNotifError_Req 1 "Error" 0 "No error" ;
VAL_ 523 DAS_RctcWarn_Req 1 "Requested" 0 "Not requested" ;
VAL_ 523 DAS_RdaWarn_Req 1 "Requested" 0 "Not requested" ;
VAL_ 523 DAS_LdwRightLaneWarn_Req 1 "Requested" 0 "Not requested" ;
VAL_ 523 DAS_LkaWarnSound_Req 1 "Requested" 0 "Not requested" ;
VAL_ 523 DAS_LccRightWarn_Req 1 "Requested" 0 "Not requested" ;
VAL_ 523 DAS_LccMode_Stat 2 "Active" 1 "Standby" 0 "Off" ;
VAL_ 356 DAS_USSSide_Req 0 "Not requested" 1 "Requested" ;
VAL_ 356 DAS_USSRear_Req 0 "Not requested" 1 "Requested" ;
VAL_ 356 DAS_USSFront_Req 0 "Not requested" 1 "Requested" ;
VAL_ 356 DAS_AdasSensLidarDirty_Stat 1 "Dirty" 0 "Clear" ;
VAL_ 356 DAS_Adas_SensTicuDirty_Stat 1 "Dirty" 0 "Clear" ;
VAL_ 356 DAS_AdasSensMrrxDirty_Stat 3 "Dirty both" 2 "Dirty right" 1 "Dirty left" 0 "Clear" ;
VAL_ 356 DAS_AdasSensWSHeat_Req 3 "Max requested" 2 "Med requested" 1 "Low requested" 0 "Not requested" ;
VAL_ 356 DAS_AdasSensAllDirty_Stat 1 "Dirty" 0 "Clear" ;
VAL_ 356 DAS_AdasSensFrcuDirty_Stat 1 "Dirty" 0 "Clear" ;
VAL_ 356 DAS_AdasSensClear_Req 4 "LIDAR" 3 "TICU" 2 "FCU" 1 "FRCU" 0 "Not requested" ;
VAL_ 356 DAS_AdasSensSteerWhVibr_Req 1 "Requested" 0 "Not requested" ;
VAL_ 356 DAS_AdasAvailMode_Stat 2 "Available" 1 "Degradate" 0 "Not available" ;
VAL_ 353 DAS_SettRdaAutoBrake_Stat 1 "On" 0 "Off" ;
VAL_ 353 DAS_ProjectionRoadSigns_Req 1 "Active" 0 "Inactive" ;
VAL_ 353 DAS_ProjectionOnRoad_Req 1 "Active" 0 "Inactive" ;
VAL_ 353 DAS_ProjectionNavigation_Req 0 "Inactive" 1 "Active" ;
VAL_ 353 DAS_ProjectionLiveObj_Req 1 "Active" 0 "Inactive" ;
VAL_ 353 DAS_SettFcwMode_Stat 2 "Late mode" 1 "Normal mode" 0 "Early mode" ;
VAL_ 353 DAS_SettRda_Stat 1 "On" 0 "Off" ;
VAL_ 353 DAS_SettLdwVibration_Stat 1 "On" 0 "Off" ;
VAL_ 353 DAS_SettRctc_Stat 1 "On" 0 "Off" ;
VAL_ 353 DAS_SettAa_Stat 1 "On" 0 "Off" ;
VAL_ 353 DAS_SettLdw_Stat 1 "On" 0 "Off" ;
VAL_ 353 DAS_SettLdwSound_Stat 1 "On" 0 "Off" ;
VAL_ 353 DAS_SettLdp_Stat 1 "On" 0 "Off" ;
VAL_ 353 DAS_SettLcc_Stat 1 "On" 0 "Off" ;
VAL_ 353 DAS_SettLdwMode_Stat 1 "While crossing" 0 "Before crossing" ;
VAL_ 353 DAS_SettLka_Stat 1 "On" 0 "Off" ;
VAL_ 353 DAS_SettFcw_Stat 1 "On" 0 "Off" ;
VAL_ 353 DAS_SettRecResol_Stat 1 "FHD" 0 "HD" ;
VAL_ 353 DAS_SettSensClean_Stat 1 "On" 0 "Off" ;
VAL_ 353 DAS_SettCcMode_Stat 2 "Dynamic mode" 1 "Comfort mode" 0 "Auto mode" ;
VAL_ 353 DAS_SettLccSound_Stat 1 "On" 0 "Off" ;
VAL_ 353 DAS_SettRec_Stat 1 "On" 0 "Off" ;
VAL_ 353 DAS_SettDowSound_Stat 1 "On" 0 "Off" ;
VAL_ 353 DAS_SettAaMode_Stat 1 "High sensitivity mode" 0 "Low sensitivity mode" ;
VAL_ 353 DAS_SettAfs_Stat 1 "On" 0 "Off" ;
VAL_ 353 DAS_SettTsr_Stat 1 "On" 0 "Off" ;
VAL_ 353 DAS_SettLccMode_Stat 2 "Far mode" 1 "Normal mode" 0 "Close mode" ;
VAL_ 353 DAS_SettRecFileSize_Stat 2 "5 min" 1 "2 min" 0 "1 min" ;
VAL_ 353 DAS_SettDow_Stat 1 "On" 0 "Off" ;
VAL_ 353 DAS_SettLccVibration_Stat 1 "On" 0 "Off" ;
VAL_ 353 DAS_SettFcwVibration_Stat 1 "On" 0 "Off" ;
VAL_ 353 DAS_SettCcSpdCorrect_Stat 1 "On" 0 "Off" ;
VAL_ 353 DAS_SettCcType_Stat 3 "LIM" 2 "ACC" 1 "CC" 0 "Off" ;
VAL_ 353 DAS_SettAlcc_Stat 1 "On" 0 "Off" ;
VAL_ 353 DAS_SettAsla_Stat 1 "On" 0 "Off" ;
VAL_ 353 DAS_SettAeb_Stat 1 "On" 0 "Off" ;
VAL_ 778 DAS_LkaShootdownNotif_Req 1 "Requested" 0 "Not requested" ;
VAL_ 778 DAS_MliaStreetLigth_Stat 1 "Street light detected" 0 "No street light" ;
VAL_ 778 DAS_AccToCc_Req 1 "Request" 0 "Not request" ;
VAL_ 778 DAS_AccNotifError_Req 1 "Error" 0 "No error" ;
VAL_ 778 DAS_LimNotifError_Req 1 "Error" 0 "No error" ;
VAL_ 778 DAS_AebUnAvaliable_Stat 1 "Unavailible" 0 "Availible" ;
VAL_ 778 DAS_AebDeactivNotif_Stat 1 "Active" 0 "Off" ;
VAL_ 778 DAS_CcSetDist_Stat 3 "Max" 2 "Med" 1 "Lowmed" 0 "Min" ;
VAL_ 778 DAS_CcReject_Req 6 "Lim is not available" 5 "Cruise Function off (With sound)" 4 "Cruise cannot be activated due to insufficient travel speed" 3 "Cruise cannot be activated due to Off Road mode" 2 "Cruise cannot be activated. The seat belt is not fastened" 1 "Cruise cannot be activated" 0 "Nothing" ;
VAL_ 778 DAS_CcNotifError_Req 1 "Error" 0 "No error" ;
VAL_ 778 DAS_FcwSoundWarn_Req 1 "Requested" 0 "Not requested" ;
VAL_ 778 DAS_AslaMode_Stat 1 "Active" 0 "Off" ;
VAL_ 778 DAS_CcTargetId_Stat 1 ">1 - target car is detected" 0 "No Target Car" ;
VAL_ 778 DAS_AebNotifError_Req 1 "Active" 0 "Inactive" ;
VAL_ 778 DAS_FcwNotifError_Req 1 "Active" 0 "Inactive" ;
VAL_ 778 DAS_FcwMode_Stat 1 "Active" 0 "Inactive" ;
VAL_ 778 DAS_CcType_Stat 3 "LIM" 2 "ACC SG" 1 "CC" 0 "Nothing" ;
VAL_ 778 DAS_CcSleep_Stat 1 "Sleep" 0 "No sleep" ;
VAL_ 778 DAS_FcwActivNotif_Req 1 "Active" 0 "Off" ;
VAL_ 778 DAS_MliaMode_Stat 3 "Boost" 2 "Active" 1 "StandBy or StreetLight" 0 "Off" ;
VAL_ 778 DAS_MliaFuncError_Stat 1 "Error" 0 "No error" ;
VAL_ 642 BCM_RoofControl_Req 0 "No request" 1 "Open roof request" 2 "Close roof request" ;
VAL_ 642 BCM_AdasSensWSHeat_Req 2 "Error" 1 "On" 0 "Off" ;
VAL_ 642 BCM_PanoramicViewLed_Cmd 1 "On" 0 "Off" ;
VAL_ 642 BCM_AntiTheft_Stat 1 "Anti Theft Active state" 0 "Anti Theft Inactive state" ;
VAL_ 642 BCM_LccBtn_Stat 1 "Button pressed" 0 "Button not pressed" ;
VAL_ 642 BCM_LdwBtn_Stat 1 "Button pressed" 0 "Button not pressed" ;
VAL_ 642 BCM_AdasSensClear_Stat 1 "Washing active" 0 "Washing inactive" ;
VAL_ 642 BCM_FootrestRRWarning_Stat 1 "Warning" 0 "No warning" ;
VAL_ 642 BCM_GovernmentComSw_Stat 1 "Government Com. Switch Active" 0 "Government Com. Switch Inactive" ;
VAL_ 642 BCM_FootrestRLWarning_Stat 1 "Warning" 0 "No warning" ;
VAL_ 642 BCM_MAS_Activation_Req 2 "Switch requested long press" 1 "Switch requested short press" 0 "Not requested" ;
VAL_ 642 BCM_EasyExitSMFL_Stat 1 "easy Exit Enable" 0 "easy Exit Disable" ;
VAL_ 642 BCM_GovernmentHandset_Stat 1 "Handset Picked Up" 0 "Handset Not Picked Up" ;
VAL_ 642 BCM_ElcromeMirror_Req 255 "Error" 0 "No shadding" ;
VAL_ 642 BCM_HeadUpDispSw_Stat 1 "Switch requested" 0 "Not requested" ;
VAL_ 642 BCM_RearWindowHeatingLED 1 "On" 0 "Off" ;
VAL_ 642 BCM_EasyExitSMRL_Stat 1 "easy Exit Enable" 0 "easy Exit Disable" ;
VAL_ 642 BCM_EasyExitSMRR_Stat 1 "easy Exit Enable" 0 "easy Exit Disable" ;
VAL_ 642 BCM_EasyExitSMFR_Stat 1 "easy Exit Enable" 0 "easy Exit Disable" ;
VAL_ 642 BCM_FootrestRR_Stat 3 "Error" 2 "Open (Unfolded)" 1 "Intermediate" 0 "Close (Folded)" ;
VAL_ 642 BCM_FootrestRL_Stat 3 "Error" 2 "Open (Unfolded)" 1 "Intermediate" 0 "Close (Folded)" ;
VAL_ 642 BCM_RemoteStart_Stat 3 "Failure" 2 "Active_Mode" 1 "Initialization_Mode" 0 "Inactive" ;
VAL_ 642 BCM_T15h_Deactivation_Req 1 "Requested" 0 "Not requested" ;

SG_MUL_VAL_ 320 DAS_LeftLaneLDWWarning_Req DAS_RoadLaneAddressing_Stat 0-0;
SG_MUL_VAL_ 320 DAS_RightLaneLDWWarning_Req DAS_RoadLaneAddressing_Stat 1-1;
SG_MUL_VAL_ 320 DAS_SPLimRoadSignInf1_Stat DAS_RoadSignAddressing_Stat 0-0;
SG_MUL_VAL_ 320 DAS_SPLimRoadSignInf2_Stat DAS_RoadSignAddressing_Stat 1-1;
SG_MUL_VAL_ 320 DAS_SPLimRoadSignInf3_Stat DAS_RoadSignAddressing_Stat 2-2;
